VERSION ""

NS_ :

BS_:

BU_: mADC

BO_ 1321 mADC_529: 64 mADC
 SG_ ACC_Target17BSDStatus : 493|2@0+ (1,0) [0|3] "" Vector__XXX
 SG_ ACC_Target16RightLightStatus : 494|1@0+ (1,0) [0|1] "" Vector__XXX
 SG_ ACC_Target16LngRelSpeed : 487|9@0+ (1,-250) [-250|250] "km/h" Vector__XXX
 SG_ ACC_Target16LngRange : 467|12@0+ (0.1,-100) [-100|300] "m" Vector__XXX
 SG_ ACC_Target16LeftLightStatus : 436|1@0+ (1,0) [0|1] "" Vector__XXX
 SG_ ACC_Target16LDC : 437|1@0+ (1,0) [0|1] "" Vector__XXX
 SG_ ACC_Target16LatRelSpeed : 461|10@0+ (0.125,-64) [-64|63.875] "m/s" Vector__XXX
 SG_ ACC_Target16LatRange : 455|10@0+ (0.1,-50) [-50|50] "m" Vector__XXX
 SG_ ACC_Target16ID : 427|6@0+ (1,0) [0|63] "" Vector__XXX
 SG_ ACC_Target16HeadingAngle : 421|10@0+ (0.01,-3.14) [-3.14|3.14] "rad" Vector__XXX
 SG_ ACC_Target16Direction : 408|3@0+ (1,0) [0|7] "" Vector__XXX
 SG_ ACC_Target16Detection : 411|3@0+ (1,0) [0|7] "" Vector__XXX
 SG_ ACC_Target16BSDStatus : 413|2@0+ (1,0) [0|3] "" Vector__XXX
 SG_ ACC_Target16BrakeLightStatus : 414|1@0+ (1,0) [0|1] "" Vector__XXX
 SG_ ACC_Target15ZoneID : 360|5@0+ (1,0) [0|31] "" Vector__XXX
 SG_ ACC_Target15Type : 402|4@0+ (1,0) [0|15] "" Vector__XXX
 SG_ ACC_Target15RightLightStatus : 361|1@0+ (1,0) [0|1] "" Vector__XXX
 SG_ ACC_Target15LngRelSpeed : 395|9@0+ (1,-250) [-250|250] "km/h" Vector__XXX
 SG_ ACC_Target15LngRange : 391|12@0+ (0.1,-100) [-100|300] "m" Vector__XXX
 SG_ ACC_Target15LeftLightStatus : 362|1@0+ (1,0) [0|1] "" Vector__XXX
 SG_ ACC_Target15LDC : 363|1@0+ (1,0) [0|1] "" Vector__XXX
 SG_ ACC_Target15LatRelSpeed : 357|10@0+ (0.125,-64) [-64|63.875] "m/s" Vector__XXX
 SG_ ACC_Target15LatRange : 351|10@0+ (0.1,-50) [-50|50] "m" Vector__XXX
 SG_ ACC_Target15ID : 341|6@0+ (1,0) [0|63] "" Vector__XXX
 SG_ ACC_Target15HeadingAngle : 335|10@0+ (0.01,-3.14) [-3.14|3.14] "rad" Vector__XXX
 SG_ ACC_Target15Direction : 322|3@0+ (1,0) [0|7] "" Vector__XXX
 SG_ ACC_Target15Detection : 325|3@0+ (1,0) [0|7] "" Vector__XXX
 SG_ ACC_Target15BSDStatus : 327|2@0+ (1,0) [0|3] "" Vector__XXX
 SG_ ACC_Target14ZoneID : 40|5@0+ (1,0) [0|31] "" Vector__XXX
 SG_ ACC_Target14Type : 311|4@0+ (1,0) [0|15] "" Vector__XXX
 SG_ ACC_Target14LngRelSpeed : 288|9@0+ (1,-250) [-250|250] "km/h" Vector__XXX
 SG_ ACC_Target14LngRange : 284|12@0+ (0.1,-100) [-100|300] "m" Vector__XXX
 SG_ ACC_Target14LeftLightStatus : 41|1@0+ (1,0) [0|1] "" Vector__XXX
 SG_ ACC_Target14LDC : 285|1@0+ (1,0) [0|1] "" Vector__XXX
 SG_ ACC_Target14LatRelSpeed : 279|10@0+ (0.125,-64) [-64|63.875] "m/s" Vector__XXX
 SG_ ACC_Target14LatRange : 257|10@0+ (0.1,-50) [-50|50] "m" Vector__XXX
 SG_ ACC_Target14ID : 263|6@0+ (1,0) [0|63] "" Vector__XXX
 SG_ ACC_Target14HeadingAngle : 237|10@0+ (0.01,-3.14) [-3.14|3.14] "rad" Vector__XXX
 SG_ ACC_Target14Direction : 224|3@0+ (1,0) [0|7] "" Vector__XXX
 SG_ ACC_Target14Detection : 227|3@0+ (1,0) [0|7] "" Vector__XXX
 SG_ ACC_Target14BSDStatus : 229|2@0+ (1,0) [0|3] "" Vector__XXX
 SG_ ACC_Target14BrakeLightStatus : 230|1@0+ (1,0) [0|1] "" Vector__XXX
 SG_ ACC_Target13ZoneID : 219|5@0+ (1,0) [0|31] "" Vector__XXX
 SG_ ACC_Target13Type : 223|4@0+ (1,0) [0|15] "" Vector__XXX
 SG_ ACC_Target13RightLightStatus : 208|1@0+ (1,0) [0|1] "" Vector__XXX
 SG_ ACC_Target13LngRelSpeed : 201|9@0+ (1,-250) [-250|250] "km/h" Vector__XXX
 SG_ ACC_Target13LngRange : 197|12@0+ (0.1,-100) [-100|300] "m" Vector__XXX
 SG_ ACC_Target13LeftLightStatus : 198|1@0+ (1,0) [0|1] "" Vector__XXX
 SG_ ACC_Target13LDC : 199|1@0+ (1,0) [0|1] "" Vector__XXX
 SG_ ACC_Target13LatRelSpeed : 173|10@0+ (0.125,-64) [-64|63.875] "m/s" Vector__XXX
 SG_ ACC_Target13LatRange : 167|10@0+ (0.1,-50) [-50|50] "m" Vector__XXX
 SG_ ACC_Target13ID : 157|6@0+ (1,0) [0|63] "" Vector__XXX
 SG_ ACC_Target13HeadingAngle : 151|10@0+ (0.01,-3.14) [-3.14|3.14] "rad" Vector__XXX
 SG_ ACC_Target13Direction : 138|3@0+ (1,0) [0|7] "" Vector__XXX
 SG_ ACC_Target13Detection : 141|3@0+ (1,0) [0|7] "" Vector__XXX
 SG_ ACC_Target13BSDStatus : 117|2@0+ (1,0) [0|3] "" Vector__XXX
 SG_ ACC_Target13BrakeLightStatus : 142|1@0+ (1,0) [0|1] "" Vector__XXX
 SG_ ACC_Target12ZoneID : 131|5@0+ (1,0) [0|31] "" Vector__XXX
 SG_ ACC_Target12Type : 135|4@0+ (1,0) [0|15] "" Vector__XXX
 SG_ ACC_Target12RightLightStatus : 118|1@0+ (1,0) [0|1] "" Vector__XXX
 SG_ ACC_Target12LngRelSpeed : 111|9@0+ (1,-250) [-250|250] "km/h" Vector__XXX
 SG_ ACC_Target12LngRange : 91|12@0+ (0.1,-100) [-100|300] "m" Vector__XXX
 SG_ ACC_Target12LeftLightStatus : 92|1@0+ (1,0) [0|1] "" Vector__XXX
 SG_ ACC_Target12LDC : 93|1@0+ (1,0) [0|1] "" Vector__XXX
 SG_ ACC_Target12LatRelSpeed : 87|10@0+ (0.125,-64) [-64|63.875] "m/s" Vector__XXX
 SG_ ACC_Target12LatRange : 65|10@0+ (0.1,-50) [-50|50] "m" Vector__XXX
 SG_ ACC_Target12ID : 71|6@0+ (1,0) [0|63] "" Vector__XXX
 SG_ ACC_Target12HeadingAngle : 35|10@0+ (0.01,-3.14) [-3.14|3.14] "rad" Vector__XXX
 SG_ ACC_Target12Direction : 38|3@0+ (1,0) [0|7] "" Vector__XXX
 SG_ ACC_Target12Detection : 25|3@0+ (1,0) [0|7] "" Vector__XXX
 SG_ ACC_Target12BSDStatus : 27|2@0+ (1,0) [0|3] "" Vector__XXX
 SG_ ACC_Target12BrakeLightStatus : 28|1@0+ (1,0) [0|1] "" Vector__XXX
 SG_ ACC_Target11ZoneID : 17|5@0+ (1,0) [0|31] "" Vector__XXX
 SG_ ACC_Target11RightLightStatus : 18|1@0+ (1,0) [0|1] "" Vector__XXX
 SG_ ACC_Target11LngRelSpeed : 11|9@0+ (1,-250) [-250|250] "km/h" Vector__XXX
 SG_ ACC_Target11LngRange : 7|12@0+ (0.1,-100) [-100|300] "m" Vector__XXX

BO_ 1323 mADC_52B: 64 mADC
 SG_ ACC_Target22BSDStatus : 493|2@0+ (1,0) [0|3] "" Vector__XXX
 SG_ ACC_Target21RightLightStatus : 436|1@0+ (1,0) [0|1] "" Vector__XXX
 SG_ ACC_Target21LngRange : 473|12@0+ (0.1,-100) [-100|300] "m" Vector__XXX
 SG_ ACC_Target21LeftLightStatus : 437|1@0+ (1,0) [0|1] "" Vector__XXX
 SG_ ACC_Target21LDC : 438|1@0+ (1,0) [0|1] "" Vector__XXX
 SG_ ACC_Target21LatRelSpeed : 467|10@0+ (0.125,-64) [-64|63.875] "m/s" Vector__XXX
 SG_ ACC_Target21LatRange : 461|10@0+ (0.1,-50) [-50|50] "m" Vector__XXX
 SG_ ACC_Target21HeadingAngle : 455|10@0+ (0.01,-3.14) [-3.14|3.14] "rad" Vector__XXX
 SG_ ACC_Target21Direction : 425|3@0+ (1,0) [0|7] "" Vector__XXX
 SG_ ACC_Target21Detection : 428|3@0+ (1,0) [0|7] "" Vector__XXX
 SG_ ACC_Target21BSDStatus : 430|2@0+ (1,0) [0|3] "" Vector__XXX
 SG_ ACC_Target21BrakeLightStatus : 431|1@0+ (1,0) [0|1] "" Vector__XXX
 SG_ ACC_Target20ZoneID : 420|5@0+ (1,0) [0|31] "" Vector__XXX
 SG_ ACC_Target20Type : 408|4@0+ (1,0) [0|15] "" Vector__XXX
 SG_ ACC_Target20RightLightStatus : 372|1@0+ (1,0) [0|1] "" Vector__XXX
 SG_ ACC_Target20LngRelSpeed : 401|9@0+ (1,-250) [-250|250] "km/h" Vector__XXX
 SG_ ACC_Target20LngRange : 397|12@0+ (0.1,-100) [-100|300] "m" Vector__XXX
 SG_ ACC_Target20LeftLightStatus : 373|1@0+ (1,0) [0|1] "" Vector__XXX
 SG_ ACC_Target20LDC : 374|1@0+ (1,0) [0|1] "" Vector__XXX
 SG_ ACC_Target20LatRelSpeed : 391|10@0+ (0.125,-64) [-64|63.875] "m/s" Vector__XXX
 SG_ ACC_Target20LatRange : 352|10@0+ (0.1,-50) [-50|50] "m" Vector__XXX
 SG_ ACC_Target20ID : 358|6@0+ (1,0) [0|63] "" Vector__XXX
 SG_ ACC_Target20HeadingAngle : 336|10@0+ (0.01,-3.14) [-3.14|3.14] "rad" Vector__XXX
 SG_ ACC_Target20Direction : 339|3@0+ (1,0) [0|7] "" Vector__XXX
 SG_ ACC_Target20Detection : 342|3@0+ (1,0) [0|7] "" Vector__XXX
 SG_ ACC_Target20BSDStatus : 328|2@0+ (1,0) [0|3] "" Vector__XXX
 SG_ ACC_Target20BrakeLightStatus : 329|1@0+ (1,0) [0|1] "" Vector__XXX
 SG_ ACC_Target1RightLightStatus : 330|1@0+ (1,0) [0|1] "" Vector__XXX
 SG_ ACC_Target1LngRelSpeed : 323|9@0+ (1,-250) [-250|250] "km/h" Vector__XXX
 SG_ ACC_Target1LeftLightStatus : 325|1@0+ (1,0) [0|1] "" Vector__XXX
 SG_ ACC_Target1LDC : 324|1@0+ (1,0) [0|1] "" Vector__XXX
 SG_ ACC_Target1LatRelSpeed : 301|10@0+ (0.125,-64) [-64|63.875] "m/s" Vector__XXX
 SG_ ACC_Target1BSDStatus : 327|2@0+ (1,0) [0|3] "" Vector__XXX
 SG_ ACC_Target1BrakeLightStatus : 302|1@0+ (1,0) [0|1] "" Vector__XXX
 SG_ ACC_Target19ZoneID : 291|5@0+ (1,0) [0|31] "" Vector__XXX
 SG_ ACC_Target19Type : 295|4@0+ (1,0) [0|15] "" Vector__XXX
 SG_ ACC_Target19RightLightStatus : 280|1@0+ (1,0) [0|1] "" Vector__XXX
 SG_ ACC_Target19LngRelSpeed : 273|9@0+ (1,-250) [-250|250] "km/h" Vector__XXX
 SG_ ACC_Target19LngRange : 269|12@0+ (0.1,-100) [-100|300] "m" Vector__XXX
 SG_ ACC_Target19LeftLightStatus : 244|1@0+ (1,0) [0|1] "" Vector__XXX
 SG_ ACC_Target19LDC : 245|1@0+ (1,0) [0|1] "" Vector__XXX
 SG_ ACC_Target19LatRelSpeed : 263|10@0+ (0.125,-64) [-64|63.875] "m/s" Vector__XXX
 SG_ ACC_Target19LatRange : 239|10@0+ (0.1,-50) [-50|50] "m" Vector__XXX
 SG_ ACC_Target19ID : 229|6@0+ (1,0) [0|63] "" Vector__XXX
 SG_ ACC_Target19HeadingAngle : 223|10@0+ (0.01,-3.14) [-3.14|3.14] "rad" Vector__XXX
 SG_ ACC_Target19Direction : 210|3@0+ (1,0) [0|7] "" Vector__XXX
 SG_ ACC_Target19Detection : 213|3@0+ (1,0) [0|7] "" Vector__XXX
 SG_ ACC_Target19BSDStatus : 215|2@0+ (1,0) [0|3] "" Vector__XXX
 SG_ ACC_Target19BrakeLightStatus : 200|1@0+ (1,0) [0|1] "" Vector__XXX
 SG_ ACC_Target18ZoneID : 205|5@0+ (1,0) [0|31] "" Vector__XXX
 SG_ ACC_Target18Type : 183|4@0+ (1,0) [0|15] "" Vector__XXX
 SG_ ACC_Target18RightLightStatus : 206|1@0+ (1,0) [0|1] "" Vector__XXX
 SG_ ACC_Target18LngRelSpeed : 199|9@0+ (1,-250) [-250|250] "km/h" Vector__XXX
 SG_ ACC_Target18LngRange : 163|12@0+ (0.1,-100) [-100|300] "m" Vector__XXX
 SG_ ACC_Target18LeftLightStatus : 108|1@0+ (1,0) [0|1] "" Vector__XXX
 SG_ ACC_Target18LDC : 109|1@0+ (1,0) [0|1] "" Vector__XXX
 SG_ ACC_Target18LatRelSpeed : 157|10@0+ (0.125,-64) [-64|63.875] "m/s" Vector__XXX
 SG_ ACC_Target18LatRange : 151|10@0+ (0.1,-50) [-50|50] "m" Vector__XXX
 SG_ ACC_Target18ID : 141|6@0+ (1,0) [0|63] "" Vector__XXX
 SG_ ACC_Target18HeadingAngle : 135|10@0+ (0.01,-3.14) [-3.14|3.14] "rad" Vector__XXX
 SG_ ACC_Target18Direction : 96|3@0+ (1,0) [0|7] "" Vector__XXX
 SG_ ACC_Target18Detection : 99|3@0+ (1,0) [0|7] "" Vector__XXX
 SG_ ACC_Target18BSDStatus : 101|2@0+ (1,0) [0|3] "" Vector__XXX
 SG_ ACC_Target18BrakeLightStatus : 102|1@0+ (1,0) [0|1] "" Vector__XXX
 SG_ ACC_Target17ZoneID : 91|5@0+ (1,0) [0|31] "" Vector__XXX
 SG_ ACC_Target17Type : 95|4@0+ (1,0) [0|15] "" Vector__XXX
 SG_ ACC_Target17RightLightStatus : 80|1@0+ (1,0) [0|1] "" Vector__XXX
 SG_ ACC_Target17LngRelSpeed : 73|9@0+ (1,-250) [-250|250] "km/h" Vector__XXX
 SG_ ACC_Target17LngRange : 69|12@0+ (0.1,-100) [-100|300] "m" Vector__XXX
 SG_ ACC_Target17LeftLightStatus : 70|1@0+ (1,0) [0|1] "" Vector__XXX
 SG_ ACC_Target17LDC : 71|1@0+ (1,0) [0|1] "" Vector__XXX
 SG_ ACC_Target17LatRelSpeed : 45|10@0+ (0.125,-64) [-64|63.875] "m/s" Vector__XXX
 SG_ ACC_Target17LatRange : 39|10@0+ (0.1,-50) [-50|50] "m" Vector__XXX
 SG_ ACC_Target17ID : 29|6@0+ (1,0) [0|63] "" Vector__XXX
 SG_ ACC_Target17HeadingAngle : 23|10@0+ (0.01,-3.14) [-3.14|3.14] "rad" Vector__XXX
 SG_ ACC_Target17Direction : 10|3@0+ (1,0) [0|7] "" Vector__XXX
 SG_ ACC_Target17Detection : 13|3@0+ (1,0) [0|7] "" Vector__XXX
 SG_ ACC_Target17BrakeLightStatus : 14|1@0+ (1,0) [0|1] "" Vector__XXX
 SG_ ACC_Target16ZoneID : 3|5@0+ (1,0) [0|31] "" Vector__XXX
 SG_ ACC_Target16Type : 7|4@0+ (1,0) [0|15] "" Vector__XXX

BO_ 1329 mADC_531: 64 mADC
 SG_ ACC_Target27BrakeLightStatus : 492|1@0+ (1,0) [0|1] "" Vector__XXX
 SG_ ACC_Target26ZoneID : 481|5@0+ (1,0) [0|31] "" Vector__XXX
 SG_ ACC_Target26RightLightStatus : 436|1@0+ (1,0) [0|1] "" Vector__XXX
 SG_ ACC_Target26LngRange : 477|12@0+ (0.1,-100) [-100|300] "m" Vector__XXX
 SG_ ACC_Target26LeftLightStatus : 437|1@0+ (1,0) [0|1] "" Vector__XXX
 SG_ ACC_Target26LDC : 438|1@0+ (1,0) [0|1] "" Vector__XXX
 SG_ ACC_Target26LatRelSpeed : 471|10@0+ (0.125,-64) [-64|63.875] "m/s" Vector__XXX
 SG_ ACC_Target26LatRange : 449|10@0+ (0.1,-50) [-50|50] "m" Vector__XXX
 SG_ ACC_Target26ID : 455|6@0+ (1,0) [0|63] "" Vector__XXX
 SG_ ACC_Target26HeadingAngle : 416|10@0+ (0.01,-3.14) [-3.14|3.14] "rad" Vector__XXX
 SG_ ACC_Target26Direction : 419|3@0+ (1,0) [0|7] "" Vector__XXX
 SG_ ACC_Target26Detection : 422|3@0+ (1,0) [0|7] "" Vector__XXX
 SG_ ACC_Target26BSDStatus : 408|2@0+ (1,0) [0|3] "" Vector__XXX
 SG_ ACC_Target26BrakeLightStatus : 409|1@0+ (1,0) [0|1] "" Vector__XXX
 SG_ ACC_Target25ZoneID : 414|5@0+ (1,0) [0|31] "" Vector__XXX
 SG_ ACC_Target25Type : 402|4@0+ (1,0) [0|15] "" Vector__XXX
 SG_ ACC_Target25RightLightStatus : 372|1@0+ (1,0) [0|1] "" Vector__XXX
 SG_ ACC_Target25LngRelSpeed : 395|9@0+ (1,-250) [-250|250] "km/h" Vector__XXX
 SG_ ACC_Target25LngRange : 391|12@0+ (0.1,-100) [-100|300] "m" Vector__XXX
 SG_ ACC_Target25LeftLightStatus : 373|1@0+ (1,0) [0|1] "" Vector__XXX
 SG_ ACC_Target25LDC : 374|1@0+ (1,0) [0|1] "" Vector__XXX
 SG_ ACC_Target25LatRelSpeed : 352|10@0+ (0.125,-64) [-64|63.875] "m/s" Vector__XXX
 SG_ ACC_Target25LatRange : 346|10@0+ (0.1,-50) [-50|50] "m" Vector__XXX
 SG_ ACC_Target25ID : 336|6@0+ (1,0) [0|63] "" Vector__XXX
 SG_ ACC_Target25HeadingAngle : 330|10@0+ (0.01,-3.14) [-3.14|3.14] "rad" Vector__XXX
 SG_ ACC_Target25Direction : 333|3@0+ (1,0) [0|7] "" Vector__XXX
 SG_ ACC_Target25Detection : 320|3@0+ (1,0) [0|7] "" Vector__XXX
 SG_ ACC_Target25BSDStatus : 322|2@0+ (1,0) [0|3] "" Vector__XXX
 SG_ ACC_Target25BrakeLightStatus : 308|1@0+ (1,0) [0|1] "" Vector__XXX
 SG_ ACC_Target24ZoneID : 327|5@0+ (1,0) [0|31] "" Vector__XXX
 SG_ ACC_Target24Type : 296|4@0+ (1,0) [0|15] "" Vector__XXX
 SG_ ACC_Target24RightLightStatus : 297|1@0+ (1,0) [0|1] "" Vector__XXX
 SG_ ACC_Target24LngRelSpeed : 290|9@0+ (1,-250) [-250|250] "km/h" Vector__XXX
 SG_ ACC_Target24LngRange : 286|12@0+ (0.1,-100) [-100|300] "m" Vector__XXX
 SG_ ACC_Target24LeftLightStatus : 287|1@0+ (1,0) [0|1] "" Vector__XXX
 SG_ ACC_Target24LDC : 272|1@0+ (1,0) [0|1] "" Vector__XXX
 SG_ ACC_Target24LatRelSpeed : 266|10@0+ (0.125,-64) [-64|63.875] "m/s" Vector__XXX
 SG_ ACC_Target24LatRange : 260|10@0+ (0.1,-50) [-50|50] "m" Vector__XXX
 SG_ ACC_Target24ID : 233|6@0+ (1,0) [0|63] "" Vector__XXX
 SG_ ACC_Target24HeadingAngle : 227|10@0+ (0.01,-3.14) [-3.14|3.14] "rad" Vector__XXX
 SG_ ACC_Target24Direction : 230|3@0+ (1,0) [0|7] "" Vector__XXX
 SG_ ACC_Target24Detection : 263|3@0+ (1,0) [0|7] "" Vector__XXX
 SG_ ACC_Target24BSDStatus : 216|2@0+ (1,0) [0|3] "" Vector__XXX
 SG_ ACC_Target24BrakeLightStatus : 217|1@0+ (1,0) [0|1] "" Vector__XXX
 SG_ ACC_Target23ZoneID : 222|5@0+ (1,0) [0|31] "" Vector__XXX
 SG_ ACC_Target23Type : 210|4@0+ (1,0) [0|15] "" Vector__XXX
 SG_ ACC_Target23RightLightStatus : 172|1@0+ (1,0) [0|1] "" Vector__XXX
 SG_ ACC_Target23LngRelSpeed : 203|9@0+ (1,-250) [-250|250] "km/h" Vector__XXX
 SG_ ACC_Target23LngRange : 199|12@0+ (0.1,-100) [-100|300] "m" Vector__XXX
 SG_ ACC_Target23LeftLightStatus : 173|1@0+ (1,0) [0|1] "" Vector__XXX
 SG_ ACC_Target23LDC : 116|1@0+ (1,0) [0|1] "" Vector__XXX
 SG_ ACC_Target23LatRelSpeed : 167|10@0+ (0.125,-64) [-64|63.875] "m/s" Vector__XXX
 SG_ ACC_Target23LatRange : 145|10@0+ (0.1,-50) [-50|50] "m" Vector__XXX
 SG_ ACC_Target23ID : 151|6@0+ (1,0) [0|63] "" Vector__XXX
 SG_ ACC_Target23HeadingAngle : 129|10@0+ (0.01,-3.14) [-3.14|3.14] "rad" Vector__XXX
 SG_ ACC_Target23Direction : 119|3@0+ (1,0) [0|7] "" Vector__XXX
 SG_ ACC_Target23Detection : 106|3@0+ (1,0) [0|7] "" Vector__XXX
 SG_ ACC_Target23BSDStatus : 108|2@0+ (1,0) [0|3] "" Vector__XXX
 SG_ ACC_Target23BrakeLightStatus : 109|1@0+ (1,0) [0|1] "" Vector__XXX
 SG_ ACC_Target22ZoneID : 98|5@0+ (1,0) [0|31] "" Vector__XXX
 SG_ ACC_Target22Type : 102|4@0+ (1,0) [0|15] "" Vector__XXX
 SG_ ACC_Target22RightLightStatus : 103|1@0+ (1,0) [0|1] "" Vector__XXX
 SG_ ACC_Target22LngRelSpeed : 80|9@0+ (1,-250) [-250|250] "km/h" Vector__XXX
 SG_ ACC_Target22LngRange : 76|12@0+ (0.1,-100) [-100|300] "m" Vector__XXX
 SG_ ACC_Target22LeftLightStatus : 77|1@0+ (1,0) [0|1] "" Vector__XXX
 SG_ ACC_Target22LDC : 52|1@0+ (1,0) [0|1] "" Vector__XXX
 SG_ ACC_Target22LatRelSpeed : 71|10@0+ (0.125,-64) [-64|63.875] "m/s" Vector__XXX
 SG_ ACC_Target22LatRange : 46|10@0+ (0.1,-50) [-50|50] "m" Vector__XXX
 SG_ ACC_Target22ID : 36|6@0+ (1,0) [0|63] "" Vector__XXX
 SG_ ACC_Target22HeadingAngle : 30|10@0+ (0.01,-3.14) [-3.14|3.14] "rad" Vector__XXX
 SG_ ACC_Target22Direction : 17|3@0+ (1,0) [0|7] "" Vector__XXX
 SG_ ACC_Target22Detection : 20|3@0+ (1,0) [0|7] "" Vector__XXX
 SG_ ACC_Target22BrakeLightStatus : 21|1@0+ (1,0) [0|1] "" Vector__XXX
 SG_ ACC_Target21ZoneID : 10|5@0+ (1,0) [0|31] "" Vector__XXX
 SG_ ACC_Target21Type : 14|4@0+ (1,0) [0|15] "" Vector__XXX
 SG_ ACC_Target21LngRelSpeed : 7|9@0+ (1,-250) [-250|250] "km/h" Vector__XXX
 SG_ ACC_Target21ID : 135|6@0+ (1,0) [0|63] "" Vector__XXX

BO_ 1330 mADC_532: 64 mADC
 SG_ ACC_Target31LngRange : 487|12@0+ (0.1,-100) [-100|300] "m" Vector__XXX
 SG_ ACC_Target31LeftLightStatus : 472|1@0+ (1,0) [0|1] "" Vector__XXX
 SG_ ACC_Target31LDC : 473|1@0+ (1,0) [0|1] "" Vector__XXX
 SG_ ACC_Target31LatRelSpeed : 467|10@0+ (0.125,-64) [-64|63.875] "m/s" Vector__XXX
 SG_ ACC_Target31LatRange : 461|10@0+ (0.1,-50) [-50|50] "m" Vector__XXX
 SG_ ACC_Target31ID : 425|6@0+ (1,0) [0|63] "" Vector__XXX
 SG_ ACC_Target31HeadingAngle : 455|10@0+ (0.01,-3.14) [-3.14|3.14] "rad" Vector__XXX
 SG_ ACC_Target31Direction : 428|3@0+ (1,0) [0|7] "" Vector__XXX
 SG_ ACC_Target31Detection : 431|3@0+ (1,0) [0|7] "" Vector__XXX
 SG_ ACC_Target31BSDStatus : 417|2@0+ (1,0) [0|3] "" Vector__XXX
 SG_ ACC_Target31BrakeLightStatus : 418|1@0+ (1,0) [0|1] "" Vector__XXX
 SG_ ACC_Target30ZoneID : 423|5@0+ (1,0) [0|31] "" Vector__XXX
 SG_ ACC_Target30Type : 411|4@0+ (1,0) [0|15] "" Vector__XXX
 SG_ ACC_Target30RightLightStatus : 412|1@0+ (1,0) [0|1] "" Vector__XXX
 SG_ ACC_Target30LngRelSpeed : 405|9@0+ (1,-250) [-250|250] "km/h" Vector__XXX
 SG_ ACC_Target30LngRange : 385|12@0+ (0.1,-100) [-100|300] "m" Vector__XXX
 SG_ ACC_Target30LeftLightStatus : 372|1@0+ (1,0) [0|1] "" Vector__XXX
 SG_ ACC_Target30LDC : 373|1@0+ (1,0) [0|1] "" Vector__XXX
 SG_ ACC_Target30LatRelSpeed : 367|10@0+ (0.125,-64) [-64|63.875] "m/s" Vector__XXX
 SG_ ACC_Target30LatRange : 345|10@0+ (0.1,-50) [-50|50] "m" Vector__XXX
 SG_ ACC_Target30ID : 391|6@0+ (1,0) [0|63] "" Vector__XXX
 SG_ ACC_Target30HeadingAngle : 339|10@0+ (0.01,-3.14) [-3.14|3.14] "rad" Vector__XXX
 SG_ ACC_Target30Direction : 342|3@0+ (1,0) [0|7] "" Vector__XXX
 SG_ ACC_Target30Detection : 329|3@0+ (1,0) [0|7] "" Vector__XXX
 SG_ ACC_Target30BSDStatus : 331|2@0+ (1,0) [0|3] "" Vector__XXX
 SG_ ACC_Target30BrakeLightStatus : 332|1@0+ (1,0) [0|1] "" Vector__XXX
 SG_ ACC_Target2RightLightStatus : 333|1@0+ (1,0) [0|1] "" Vector__XXX
 SG_ ACC_Target2LngRelSpeed : 326|9@0+ (1,-250) [-250|250] "km/h" Vector__XXX
 SG_ ACC_Target2LeftLightStatus : 327|1@0+ (1,0) [0|1] "" Vector__XXX
 SG_ ACC_Target2LDC : 308|1@0+ (1,0) [0|1] "" Vector__XXX
 SG_ ACC_Target2LatRelSpeed : 302|10@0+ (0.125,-64) [-64|63.875] "m/s" Vector__XXX
 SG_ ACC_Target2BSDStatus : 288|2@0+ (1,0) [0|3] "" Vector__XXX
 SG_ ACC_Target2BrakeLightStatus : 289|1@0+ (1,0) [0|1] "" Vector__XXX
 SG_ ACC_Target29ZoneID : 294|5@0+ (1,0) [0|31] "" Vector__XXX
 SG_ ACC_Target29Type : 282|4@0+ (1,0) [0|15] "" Vector__XXX
 SG_ ACC_Target29RightLightStatus : 283|1@0+ (1,0) [0|1] "" Vector__XXX
 SG_ ACC_Target29LngRelSpeed : 276|9@0+ (1,-250) [-250|250] "km/h" Vector__XXX
 SG_ ACC_Target29LngRange : 256|12@0+ (0.1,-100) [-100|300] "m" Vector__XXX
 SG_ ACC_Target29LeftLightStatus : 257|1@0+ (1,0) [0|1] "" Vector__XXX
 SG_ ACC_Target29LDC : 244|1@0+ (1,0) [0|1] "" Vector__XXX
 SG_ ACC_Target29LatRelSpeed : 238|10@0+ (0.125,-64) [-64|63.875] "m/s" Vector__XXX
 SG_ ACC_Target29LatRange : 216|10@0+ (0.1,-50) [-50|50] "m" Vector__XXX
 SG_ ACC_Target29ID : 263|6@0+ (1,0) [0|63] "" Vector__XXX
 SG_ ACC_Target29HeadingAngle : 210|10@0+ (0.01,-3.14) [-3.14|3.14] "rad" Vector__XXX
 SG_ ACC_Target29Direction : 213|3@0+ (1,0) [0|7] "" Vector__XXX
 SG_ ACC_Target29Detection : 200|3@0+ (1,0) [0|7] "" Vector__XXX
 SG_ ACC_Target29BSDStatus : 202|2@0+ (1,0) [0|3] "" Vector__XXX
 SG_ ACC_Target29BrakeLightStatus : 203|1@0+ (1,0) [0|1] "" Vector__XXX
 SG_ ACC_Target28ZoneID : 192|5@0+ (1,0) [0|31] "" Vector__XXX
 SG_ ACC_Target28Type : 196|4@0+ (1,0) [0|15] "" Vector__XXX
 SG_ ACC_Target28RightLightStatus : 197|1@0+ (1,0) [0|1] "" Vector__XXX
 SG_ ACC_Target28LngRelSpeed : 172|9@0+ (1,-250) [-250|250] "km/h" Vector__XXX
 SG_ ACC_Target28LngRange : 152|12@0+ (0.1,-100) [-100|300] "m" Vector__XXX
 SG_ ACC_Target28LeftLightStatus : 198|1@0+ (1,0) [0|1] "" Vector__XXX
 SG_ ACC_Target28LDC : 199|1@0+ (1,0) [0|1] "" Vector__XXX
 SG_ ACC_Target28LatRelSpeed : 146|10@0+ (0.125,-64) [-64|63.875] "m/s" Vector__XXX
 SG_ ACC_Target28LatRange : 140|10@0+ (0.1,-50) [-50|50] "m" Vector__XXX
 SG_ ACC_Target28ID : 130|6@0+ (1,0) [0|63] "" Vector__XXX
 SG_ ACC_Target28HeadingAngle : 109|10@0+ (0.01,-3.14) [-3.14|3.14] "rad" Vector__XXX
 SG_ ACC_Target28Direction : 133|3@0+ (1,0) [0|7] "" Vector__XXX
 SG_ ACC_Target28Detection : 96|3@0+ (1,0) [0|7] "" Vector__XXX
 SG_ ACC_Target28BSDStatus : 135|2@0+ (1,0) [0|3] "" Vector__XXX
 SG_ ACC_Target28BrakeLightStatus : 97|1@0+ (1,0) [0|1] "" Vector__XXX
 SG_ ACC_Target27ZoneID : 102|5@0+ (1,0) [0|31] "" Vector__XXX
 SG_ ACC_Target27Type : 90|4@0+ (1,0) [0|15] "" Vector__XXX
 SG_ ACC_Target27RightLightStatus : 91|1@0+ (1,0) [0|1] "" Vector__XXX
 SG_ ACC_Target27LngRelSpeed : 84|9@0+ (1,-250) [-250|250] "km/h" Vector__XXX
 SG_ ACC_Target27LngRange : 64|12@0+ (0.1,-100) [-100|300] "m" Vector__XXX
 SG_ ACC_Target27LeftLightStatus : 65|1@0+ (1,0) [0|1] "" Vector__XXX
 SG_ ACC_Target27LDC : 66|1@0+ (1,0) [0|1] "" Vector__XXX
 SG_ ACC_Target27LatRelSpeed : 45|10@0+ (0.125,-64) [-64|63.875] "m/s" Vector__XXX
 SG_ ACC_Target27LatRange : 39|10@0+ (0.1,-50) [-50|50] "m" Vector__XXX
 SG_ ACC_Target27ID : 29|6@0+ (1,0) [0|63] "" Vector__XXX
 SG_ ACC_Target27HeadingAngle : 23|10@0+ (0.01,-3.14) [-3.14|3.14] "rad" Vector__XXX
 SG_ ACC_Target27Direction : 69|3@0+ (1,0) [0|7] "" Vector__XXX
 SG_ ACC_Target27Detection : 10|3@0+ (1,0) [0|7] "" Vector__XXX
 SG_ ACC_Target27BSDStatus : 71|2@0+ (1,0) [0|3] "" Vector__XXX
 SG_ ACC_Target26Type : 14|4@0+ (1,0) [0|15] "" Vector__XXX
 SG_ ACC_Target26LngRelSpeed : 7|9@0+ (1,-250) [-250|250] "km/h" Vector__XXX

BO_ 1331 mADC_533: 64 mADC
 SG_ APA_DynamicButton : 172|4@0+ (1,0) [0|15] "" Vector__XXX
 SG_ APA_DLPReq : 495|4@0+ (1,0) [0|15] "" Vector__XXX
 SG_ APA_DetailedVoice_Switch : 480|1@0+ (1,0) [0|1] "" Vector__XXX
 SG_ APA_BackstageSearchSts : 481|1@0+ (1,0) [0|1] "" Vector__XXX
 SG_ ADS_IACCSysdeactiveReason : 485|4@0+ (1,0) [0|15] "" Vector__XXX
 SG_ ADS_IACC_LatTakeOverReason : 473|4@0+ (1,0) [0|15] "" Vector__XXX
 SG_ ACC_RLaneQuality : 479|6@0+ (0.015625,0) [0|0.984375] "" Vector__XXX
 SG_ ACC_RedLightRemindEnable : 464|1@0+ (1,0) [0|1] "" Vector__XXX
 SG_ ACC_DOSECountDown : 469|5@0+ (1,0) [0|31] "" Vector__XXX
 SG_ ACC_Target9ZoneID : 458|5@0+ (1,0) [0|31] "" Vector__XXX
 SG_ ACC_Target9Type : 462|4@0+ (1,0) [0|15] "" Vector__XXX
 SG_ ACC_Target9RightLightStatus : 436|1@0+ (1,0) [0|1] "" Vector__XXX
 SG_ ACC_Target9LngRelSpeed : 455|9@0+ (1,-250) [-250|250] "km/h" Vector__XXX
 SG_ ACC_Target9LngRange : 416|12@0+ (0.1,-100) [-100|300] "m" Vector__XXX
 SG_ ACC_Target9LeftLightStatus : 372|1@0+ (1,0) [0|1] "" Vector__XXX
 SG_ ACC_Target9LDC : 373|1@0+ (1,0) [0|1] "" Vector__XXX
 SG_ ACC_Target9LatRelSpeed : 410|10@0+ (0.125,-64) [-64|63.875] "m/s" Vector__XXX
 SG_ ACC_Target9LatRange : 404|10@0+ (0.1,-50) [-50|50] "m" Vector__XXX
 SG_ ACC_Target9ID : 394|6@0+ (1,0) [0|63] "" Vector__XXX
 SG_ ACC_Target9HeadingAngle : 388|10@0+ (0.01,-3.14) [-3.14|3.14] "rad" Vector__XXX
 SG_ ACC_Target9Direction : 391|3@0+ (1,0) [0|7] "" Vector__XXX
 SG_ ACC_Target9Detection : 360|3@0+ (1,0) [0|7] "" Vector__XXX
 SG_ ACC_Target9BSDStatus : 362|2@0+ (1,0) [0|3] "" Vector__XXX
 SG_ ACC_Target9BrakeLightStatus : 363|1@0+ (1,0) [0|1] "" Vector__XXX
 SG_ ACC_Target8ZoneID : 352|5@0+ (1,0) [0|31] "" Vector__XXX
 SG_ ACC_Target8Type : 356|4@0+ (1,0) [0|15] "" Vector__XXX
 SG_ ACC_Target8RightLightStatus : 357|1@0+ (1,0) [0|1] "" Vector__XXX
 SG_ ACC_Target8LngRelSpeed : 350|9@0+ (1,-250) [-250|250] "km/h" Vector__XXX
 SG_ ACC_Target8LngRange : 330|12@0+ (0.1,-100) [-100|300] "m" Vector__XXX
 SG_ ACC_Target8LeftLightStatus : 308|1@0+ (1,0) [0|1] "" Vector__XXX
 SG_ ACC_Target8LDC : 309|1@0+ (1,0) [0|1] "" Vector__XXX
 SG_ ACC_Target8LatRelSpeed : 324|10@0+ (0.125,-64) [-64|63.875] "m/s" Vector__XXX
 SG_ ACC_Target8LatRange : 303|10@0+ (0.1,-50) [-50|50] "m" Vector__XXX
 SG_ ACC_Target8ID : 293|6@0+ (1,0) [0|63] "" Vector__XXX
 SG_ ACC_Target8HeadingAngle : 287|10@0+ (0.01,-3.14) [-3.14|3.14] "rad" Vector__XXX
 SG_ ACC_Target8Direction : 327|3@0+ (1,0) [0|7] "" Vector__XXX
 SG_ ACC_Target8Detection : 274|3@0+ (1,0) [0|7] "" Vector__XXX
 SG_ ACC_Target8BSDStatus : 276|2@0+ (1,0) [0|3] "" Vector__XXX
 SG_ ACC_Target8BrakeLightStatus : 244|1@0+ (1,0) [0|1] "" Vector__XXX
 SG_ ACC_Target7RightLightStatus : 245|1@0+ (1,0) [0|1] "" Vector__XXX
 SG_ ACC_Target7LngRelSpeed : 269|9@0+ (1,-250) [-250|250] "km/h" Vector__XXX
 SG_ ACC_Target7LeftLightStatus : 246|1@0+ (1,0) [0|1] "" Vector__XXX
 SG_ ACC_Target7LDC : 247|1@0+ (1,0) [0|1] "" Vector__XXX
 SG_ ACC_Target7LatRelSpeed : 263|10@0+ (0.125,-64) [-64|63.875] "m/s" Vector__XXX
 SG_ ACC_Target7BSDStatus : 233|2@0+ (1,0) [0|3] "" Vector__XXX
 SG_ ACC_Target7BrakeLightStatus : 234|1@0+ (1,0) [0|1] "" Vector__XXX
 SG_ ACC_Target6RightLightStatus : 235|1@0+ (1,0) [0|1] "" Vector__XXX
 SG_ ACC_Target6LngRelSpeed : 228|9@0+ (1,-250) [-250|250] "km/h" Vector__XXX
 SG_ ACC_Target6LeftLightStatus : 229|1@0+ (1,0) [0|1] "" Vector__XXX
 SG_ ACC_Target6LDC : 230|1@0+ (1,0) [0|1] "" Vector__XXX
 SG_ ACC_Target6LatRelSpeed : 208|10@0+ (0.125,-64) [-64|63.875] "m/s" Vector__XXX
 SG_ ACC_Target6BSDStatus : 210|2@0+ (1,0) [0|3] "" Vector__XXX
 SG_ ACC_Target6BrakeLightStatus : 211|1@0+ (1,0) [0|1] "" Vector__XXX
 SG_ ACC_Target5RightLightStatus : 212|1@0+ (1,0) [0|1] "" Vector__XXX
 SG_ ACC_Target5LngRelSpeed : 205|9@0+ (1,-250) [-250|250] "km/h" Vector__XXX
 SG_ ACC_Target5LeftLightStatus : 180|1@0+ (1,0) [0|1] "" Vector__XXX
 SG_ ACC_Target5LDC : 181|1@0+ (1,0) [0|1] "" Vector__XXX
 SG_ ACC_Target5LatRelSpeed : 199|10@0+ (0.125,-64) [-64|63.875] "m/s" Vector__XXX
 SG_ ACC_Target5BSDStatus : 183|2@0+ (1,0) [0|3] "" Vector__XXX
 SG_ ACC_Target5BrakeLightStatus : 168|1@0+ (1,0) [0|1] "" Vector__XXX
 SG_ ACC_Target4RightLightStatus : 173|1@0+ (1,0) [0|1] "" Vector__XXX
 SG_ ACC_Target4LngRelSpeed : 166|9@0+ (1,-250) [-250|250] "km/h" Vector__XXX
 SG_ ACC_Target4LeftLightStatus : 167|1@0+ (1,0) [0|1] "" Vector__XXX
 SG_ ACC_Target4LDC : 152|1@0+ (1,0) [0|1] "" Vector__XXX
 SG_ ACC_Target4LatRelSpeed : 146|10@0+ (0.125,-64) [-64|63.875] "m/s" Vector__XXX
 SG_ ACC_Target4BSDStatus : 148|2@0+ (1,0) [0|3] "" Vector__XXX
 SG_ ACC_Target4BrakeLightStatus : 149|1@0+ (1,0) [0|1] "" Vector__XXX
 SG_ ACC_Target3RightLightStatus : 150|1@0+ (1,0) [0|1] "" Vector__XXX
 SG_ ACC_Target3LngRelSpeed : 143|9@0+ (1,-250) [-250|250] "km/h" Vector__XXX
 SG_ ACC_Target3LeftLightStatus : 128|1@0+ (1,0) [0|1] "" Vector__XXX
 SG_ ACC_Target3LDC : 129|1@0+ (1,0) [0|1] "" Vector__XXX
 SG_ ACC_Target3LatRelSpeed : 109|10@0+ (0.125,-64) [-64|63.875] "m/s" Vector__XXX
 SG_ ACC_Target3BSDStatus : 111|2@0+ (1,0) [0|3] "" Vector__XXX
 SG_ ACC_Target3BrakeLightStatus : 130|1@0+ (1,0) [0|1] "" Vector__XXX
 SG_ ACC_Target32ZoneID : 135|5@0+ (1,0) [0|31] "" Vector__XXX
 SG_ ACC_Target32Type : 99|4@0+ (1,0) [0|15] "" Vector__XXX
 SG_ ACC_Target32RightLightStatus : 100|1@0+ (1,0) [0|1] "" Vector__XXX
 SG_ ACC_Target32LngRelSpeed : 93|9@0+ (1,-250) [-250|250] "km/h" Vector__XXX
 SG_ ACC_Target32LngRange : 73|12@0+ (0.1,-100) [-100|300] "m" Vector__XXX
 SG_ ACC_Target32LeftLightStatus : 74|1@0+ (1,0) [0|1] "" Vector__XXX
 SG_ ACC_Target32LDC : 75|1@0+ (1,0) [0|1] "" Vector__XXX
 SG_ ACC_Target32LatRelSpeed : 69|10@0+ (0.125,-64) [-64|63.875] "m/s" Vector__XXX
 SG_ ACC_Target32LatRange : 45|10@0+ (0.1,-50) [-50|50] "m" Vector__XXX
 SG_ ACC_Target32ID : 35|6@0+ (1,0) [0|63] "" Vector__XXX
 SG_ ACC_Target32HeadingAngle : 29|10@0+ (0.01,-3.14) [-3.14|3.14] "rad" Vector__XXX
 SG_ ACC_Target32Direction : 16|3@0+ (1,0) [0|7] "" Vector__XXX
 SG_ ACC_Target32Detection : 19|3@0+ (1,0) [0|7] "" Vector__XXX
 SG_ ACC_Target32BSDStatus : 71|2@0+ (1,0) [0|3] "" Vector__XXX
 SG_ ACC_Target32BrakeLightStatus : 20|1@0+ (1,0) [0|1] "" Vector__XXX
 SG_ ACC_Target31ZoneID : 9|5@0+ (1,0) [0|31] "" Vector__XXX
 SG_ ACC_Target31Type : 13|4@0+ (1,0) [0|15] "" Vector__XXX
 SG_ ACC_Target31RightLightStatus : 14|1@0+ (1,0) [0|1] "" Vector__XXX
 SG_ ACC_Target31LngRelSpeed : 7|9@0+ (1,-250) [-250|250] "km/h" Vector__XXX

BO_ 959 GW_3BF: 8 Vector__XXX
 SG_ PCU_DteDisp : 5|11@0+ (1,0) [0|2046] "KM"  mADC

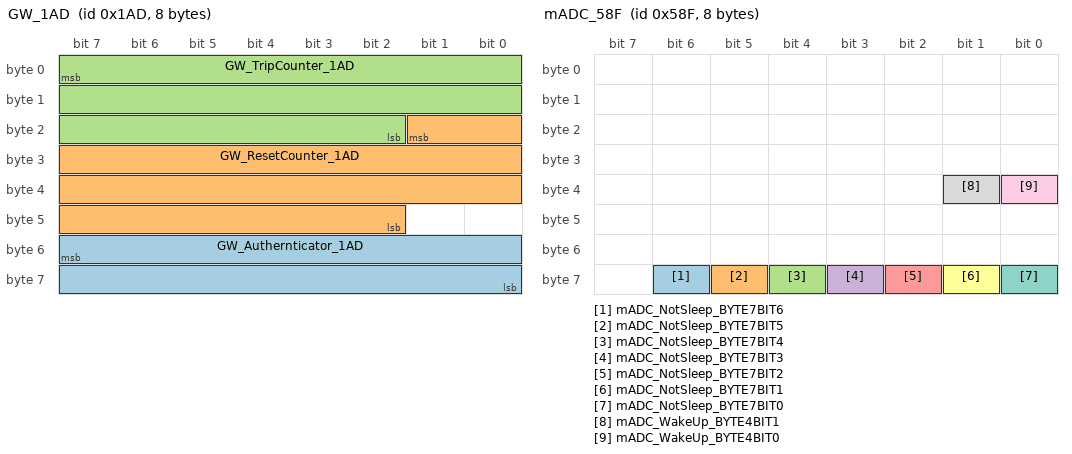
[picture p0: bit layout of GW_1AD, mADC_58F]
BO_ 429 GW_1AD: 8 Vector__XXX
 SG_ GW_Authernticator_1AD : 55|16@0+ (1,0) [0|65535] ""  mADC
 SG_ GW_ResetCounter_1AD : 17|24@0+ (1,0) [0|16777215] ""  mADC
 SG_ GW_TripCounter_1AD : 7|22@0+ (1,0) [0|4194303] ""  mADC

BO_ 1517 mADC_5ED: 8 mADC
 SG_ KeyLearn_Authernticator_5ED : 39|32@0+ (1,0) [1|4294967296] "" Vector__XXX
 SG_ KeyLearn_Random_5ED : 7|32@0+ (1,0) [1|4294967296] "" Vector__XXX

BO_ 1423 mADC_58F: 8 mADC
 SG_ mADC_NotSleep_BYTE7BIT6 : 62|1@0+ (1,0) [0|1] "" Vector__XXX
 SG_ mADC_NotSleep_BYTE7BIT5 : 61|1@0+ (1,0) [0|1] "" Vector__XXX
 SG_ mADC_NotSleep_BYTE7BIT4 : 60|1@0+ (1,0) [0|1] "" Vector__XXX
 SG_ mADC_NotSleep_BYTE7BIT3 : 59|1@0+ (1,0) [0|1] "" Vector__XXX
 SG_ mADC_NotSleep_BYTE7BIT2 : 58|1@0+ (1,0) [0|1] "" Vector__XXX
 SG_ mADC_NotSleep_BYTE7BIT1 : 57|1@0+ (1,0) [0|1] "" Vector__XXX
 SG_ mADC_NotSleep_BYTE7BIT0 : 56|1@0+ (1,0) [0|1] "" Vector__XXX
 SG_ mADC_WakeUp_BYTE4BIT1 : 33|1@0+ (1,0) [0|1] "" Vector__XXX
 SG_ mADC_WakeUp_BYTE4BIT0 : 32|1@0+ (1,0) [0|1] "" Vector__XXX

BO_ 958 GW_3BE: 8 Vector__XXX
 SG_ ATS_CurrentDrivingMode : 35|4@0+ (1,0) [0|15] ""  mADC

BO_ 1718 mADC_6B6: 64 mADC
 SG_ IQSoftwareversion_P : 151|48@0+ (1,0) [0|1] "" Vector__XXX
 SG_ IQSoftwareversion_D : 103|48@0+ (1,0) [0|1] "" Vector__XXX
 SG_ IQSoftwareversion_R : 55|48@0+ (1,0) [0|1] "" Vector__XXX
 SG_ IQSoftwareversion_F : 7|48@0+ (1,0) [0|1] "" Vector__XXX

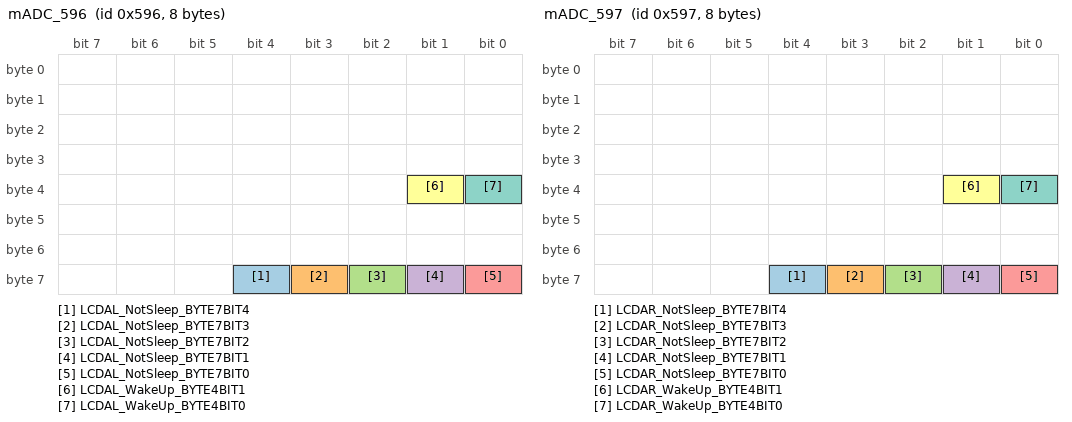
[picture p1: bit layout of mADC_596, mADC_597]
BO_ 1430 mADC_596: 8 mADC
 SG_ LCDAL_NotSleep_BYTE7BIT4 : 60|1@0+ (1,0) [0|1] "" Vector__XXX
 SG_ LCDAL_NotSleep_BYTE7BIT3 : 59|1@0+ (1,0) [0|1] "" Vector__XXX
 SG_ LCDAL_NotSleep_BYTE7BIT2 : 58|1@0+ (1,0) [0|1] "" Vector__XXX
 SG_ LCDAL_NotSleep_BYTE7BIT1 : 57|1@0+ (1,0) [0|1] "" Vector__XXX
 SG_ LCDAL_NotSleep_BYTE7BIT0 : 56|1@0+ (1,0) [0|1] "" Vector__XXX
 SG_ LCDAL_WakeUp_BYTE4BIT1 : 33|1@0+ (1,0) [0|1] "" Vector__XXX
 SG_ LCDAL_WakeUp_BYTE4BIT0 : 32|1@0+ (1,0) [0|1] "" Vector__XXX

BO_ 1431 mADC_597: 8 mADC
 SG_ LCDAR_NotSleep_BYTE7BIT4 : 60|1@0+ (1,0) [0|1] "" Vector__XXX
 SG_ LCDAR_NotSleep_BYTE7BIT3 : 59|1@0+ (1,0) [0|1] "" Vector__XXX
 SG_ LCDAR_NotSleep_BYTE7BIT2 : 58|1@0+ (1,0) [0|1] "" Vector__XXX
 SG_ LCDAR_NotSleep_BYTE7BIT1 : 57|1@0+ (1,0) [0|1] "" Vector__XXX
 SG_ LCDAR_NotSleep_BYTE7BIT0 : 56|1@0+ (1,0) [0|1] "" Vector__XXX
 SG_ LCDAR_WakeUp_BYTE4BIT1 : 33|1@0+ (1,0) [0|1] "" Vector__XXX
 SG_ LCDAR_WakeUp_BYTE4BIT0 : 32|1@0+ (1,0) [0|1] "" Vector__XXX

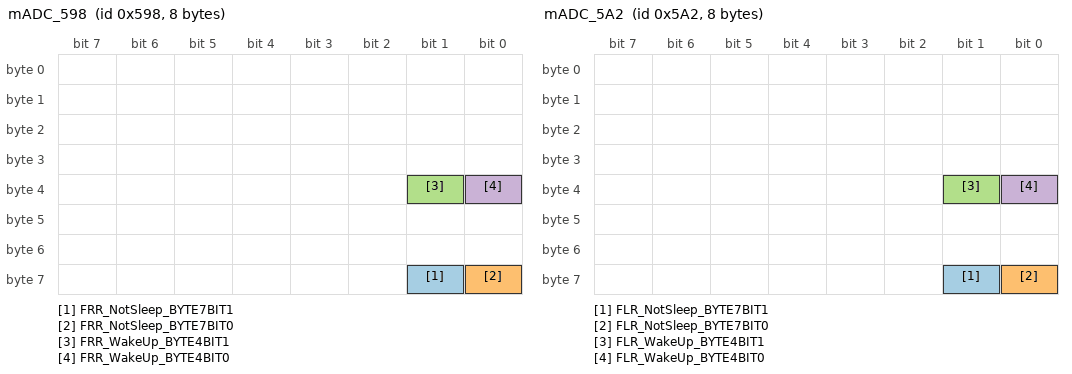
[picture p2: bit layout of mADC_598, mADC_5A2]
BO_ 1432 mADC_598: 8 mADC
 SG_ FRR_NotSleep_BYTE7BIT1 : 57|1@0+ (1,0) [0|1] "" Vector__XXX
 SG_ FRR_NotSleep_BYTE7BIT0 : 56|1@0+ (1,0) [0|1] "" Vector__XXX
 SG_ FRR_WakeUp_BYTE4BIT1 : 33|1@0+ (1,0) [0|1] "" Vector__XXX
 SG_ FRR_WakeUp_BYTE4BIT0 : 32|1@0+ (1,0) [0|1] "" Vector__XXX

BO_ 1442 mADC_5A2: 8 mADC
 SG_ FLR_NotSleep_BYTE7BIT1 : 57|1@0+ (1,0) [0|1] "" Vector__XXX
 SG_ FLR_NotSleep_BYTE7BIT0 : 56|1@0+ (1,0) [0|1] "" Vector__XXX
 SG_ FLR_WakeUp_BYTE4BIT1 : 33|1@0+ (1,0) [0|1] "" Vector__XXX
 SG_ FLR_WakeUp_BYTE4BIT0 : 32|1@0+ (1,0) [0|1] "" Vector__XXX

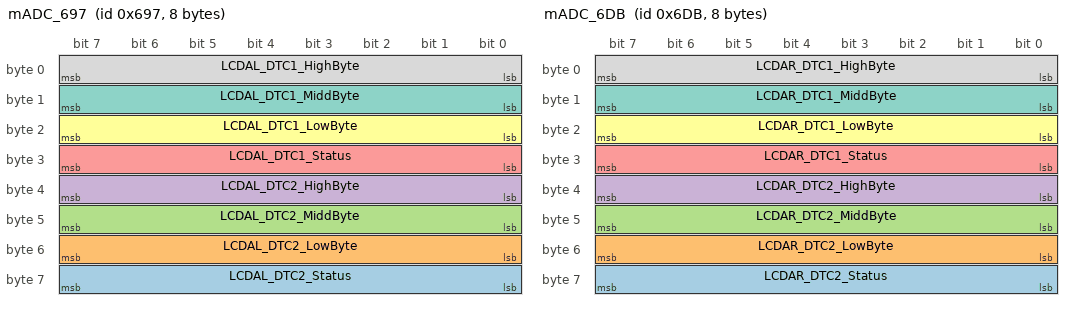
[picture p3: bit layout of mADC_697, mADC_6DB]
BO_ 1687 mADC_697: 8 mADC
 SG_ LCDAL_DTC2_Status : 63|8@0+ (1,0) [0|255] "" Vector__XXX
 SG_ LCDAL_DTC2_LowByte : 55|8@0+ (1,0) [0|255] "" Vector__XXX
 SG_ LCDAL_DTC2_MiddByte : 47|8@0+ (1,0) [0|255] "" Vector__XXX
 SG_ LCDAL_DTC2_HighByte : 39|8@0+ (1,0) [0|255] "" Vector__XXX
 SG_ LCDAL_DTC1_Status : 31|8@0+ (1,0) [0|255] "" Vector__XXX
 SG_ LCDAL_DTC1_LowByte : 23|8@0+ (1,0) [0|255] "" Vector__XXX
 SG_ LCDAL_DTC1_MiddByte : 15|8@0+ (1,0) [0|255] "" Vector__XXX
 SG_ LCDAL_DTC1_HighByte : 7|8@0+ (1,0) [0|255] "" Vector__XXX

BO_ 1755 mADC_6DB: 8 mADC
 SG_ LCDAR_DTC2_Status : 63|8@0+ (1,0) [0|255] "" Vector__XXX
 SG_ LCDAR_DTC2_LowByte : 55|8@0+ (1,0) [0|255] "" Vector__XXX
 SG_ LCDAR_DTC2_MiddByte : 47|8@0+ (1,0) [0|255] "" Vector__XXX
 SG_ LCDAR_DTC2_HighByte : 39|8@0+ (1,0) [0|255] "" Vector__XXX
 SG_ LCDAR_DTC1_Status : 31|8@0+ (1,0) [0|255] "" Vector__XXX
 SG_ LCDAR_DTC1_LowByte : 23|8@0+ (1,0) [0|255] "" Vector__XXX
 SG_ LCDAR_DTC1_MiddByte : 15|8@0+ (1,0) [0|255] "" Vector__XXX
 SG_ LCDAR_DTC1_HighByte : 7|8@0+ (1,0) [0|255] "" Vector__XXX

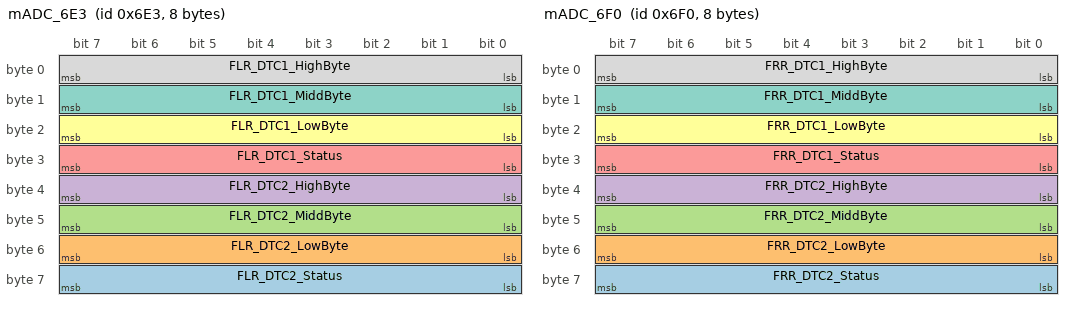
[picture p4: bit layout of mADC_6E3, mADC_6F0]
BO_ 1763 mADC_6E3: 8 mADC
 SG_ FLR_DTC2_Status : 63|8@0+ (1,0) [0|255] "" Vector__XXX
 SG_ FLR_DTC2_LowByte : 55|8@0+ (1,0) [0|255] "" Vector__XXX
 SG_ FLR_DTC2_MiddByte : 47|8@0+ (1,0) [0|255] "" Vector__XXX
 SG_ FLR_DTC2_HighByte : 39|8@0+ (1,0) [0|255] "" Vector__XXX
 SG_ FLR_DTC1_Status : 31|8@0+ (1,0) [0|255] "" Vector__XXX
 SG_ FLR_DTC1_LowByte : 23|8@0+ (1,0) [0|255] "" Vector__XXX
 SG_ FLR_DTC1_MiddByte : 15|8@0+ (1,0) [0|255] "" Vector__XXX
 SG_ FLR_DTC1_HighByte : 7|8@0+ (1,0) [0|255] "" Vector__XXX

BO_ 1776 mADC_6F0: 8 mADC
 SG_ FRR_DTC2_Status : 63|8@0+ (1,0) [0|255] "" Vector__XXX
 SG_ FRR_DTC2_LowByte : 55|8@0+ (1,0) [0|255] "" Vector__XXX
 SG_ FRR_DTC2_MiddByte : 47|8@0+ (1,0) [0|255] "" Vector__XXX
 SG_ FRR_DTC2_HighByte : 39|8@0+ (1,0) [0|255] "" Vector__XXX
 SG_ FRR_DTC1_Status : 31|8@0+ (1,0) [0|255] "" Vector__XXX
 SG_ FRR_DTC1_LowByte : 23|8@0+ (1,0) [0|255] "" Vector__XXX
 SG_ FRR_DTC1_MiddByte : 15|8@0+ (1,0) [0|255] "" Vector__XXX
 SG_ FRR_DTC1_HighByte : 7|8@0+ (1,0) [0|255] "" Vector__XXX

BO_ 2015 GW_7DF: 8 Vector__XXX
 SG_ Diagnose_message7DF : 0|1@0+ (1,0) [1|1] ""  mADC

BO_ 1937 GW_791: 64 Vector__XXX
 SG_ Diagnose_message791 : 0|1@0+ (1,0) [1|1] ""  mADC

BO_ 1945 mADC_799: 8 mADC
 SG_ Diagnose_message799 : 0|1@0+ (1,0) [1|1] "" Vector__XXX

BO_ 1895 GW_767: 64 Vector__XXX
 SG_ Diagnose_message767 : 0|1@0+ (1,0) [1|1] ""  mADC

BO_ 1903 mADC_76F: 8 mADC
 SG_ Diagnose_message76F : 0|1@0+ (1,0) [1|1] "" Vector__XXX

BO_ 1894 GW_766: 64 Vector__XXX
 SG_ Diagnose_message766 : 0|1@0+ (1,0) [1|1] ""  mADC

BO_ 1902 mADC_76E: 8 mADC
 SG_ Diagnose_message76E : 0|1@0+ (1,0) [1|1] "" Vector__XXX

BO_ 1875 GW_753: 64 Vector__XXX
 SG_ Diagnose_message753 : 0|1@0+ (1,0) [1|1] ""  mADC

BO_ 1883 mADC_75B: 8 mADC
 SG_ Diagnose_message75B : 0|1@0+ (1,0) [1|1] "" Vector__XXX

BO_ 1876 GW_754: 64 Vector__XXX
 SG_ Diagnose_message754 : 0|1@0+ (1,0) [1|1] ""  mADC

BO_ 1884 mADC_75C: 8 mADC
 SG_ Diagnose_message75C : 0|1@0+ (1,0) [1|1] "" Vector__XXX

BO_ 1890 GW_762: 64 Vector__XXX
 SG_ Diagnose_message762 : 0|1@0+ (1,0) [1|1] ""  mADC

BO_ 1898 mADC_76A: 8 mADC
 SG_ Diagnose_message76A : 0|1@0+ (1,0) [1|1] "" Vector__XXX

BO_ 953 GW_3B9: 8 Vector__XXX
 SG_ BDC_TurnLightSw : 61|3@0+ (1,1) [0|7] "1"  mADC

BO_ 691 GW_2B3: 8 Vector__XXX
 SG_ THU_ShippingMod : 22|2@0+ (1,0) [0|2] ""  mADC

BO_ 989 GW_3DD: 64 Vector__XXX
 SG_ HU_frontline8_icon : 127|8@0+ (1,0) [0|255] ""  mADC
 SG_ HU_frontline7_icon : 119|8@0+ (1,0) [0|255] ""  mADC
 SG_ HU_frontline6_icon : 111|8@0+ (1,0) [0|255] ""  mADC
 SG_ HU_frontline5_icon : 103|8@0+ (1,0) [0|255] ""  mADC
 SG_ HU_frontline4_icon : 95|8@0+ (1,0) [0|255] ""  mADC
 SG_ HU_frontline3_icon : 87|8@0+ (1,0) [0|255] ""  mADC
 SG_ HU_frontline2_icon : 79|8@0+ (1,0) [0|255] ""  mADC
 SG_ HU_frontline1_icon : 71|8@0+ (1,0) [0|255] ""  mADC
 SG_ HU_backline8_icon : 63|8@0+ (1,0) [0|255] ""  mADC
 SG_ HU_backline7_icon : 55|8@0+ (1,0) [0|255] ""  mADC
 SG_ HU_backline6_icon : 47|8@0+ (1,0) [0|255] ""  mADC
 SG_ HU_backline5_icon : 39|8@0+ (1,0) [0|255] ""  mADC
 SG_ HU_backline4_icon : 31|8@0+ (1,0) [0|255] ""  mADC
 SG_ HU_backline3_icon : 23|8@0+ (1,0) [0|255] ""  mADC
 SG_ HU_backline2_icon : 15|8@0+ (1,0) [0|255] ""  mADC
 SG_ HU_backline1_icon : 7|8@0+ (1,0) [0|255] ""  mADC
 SG_ HU_LineShow : 135|1@0+ (1,0) [0|1] ""  mADC

BO_ 1018 GW_3FA: 8 Vector__XXX
 SG_ ESP_EpbReqAvl : 2|1@0+ (1,0) [0|1] ""  mADC

BO_ 913 GW_391: 8 Vector__XXX
 SG_ PCU_TowingMode : 41|1@0+ (1,0) [0|1] ""  mADC

BO_ 573 GW_23D: 64 Vector__XXX
 SG_ HU_RollingCounter_23D : 491|4@0+ (1,0) [0|15] ""  mADC
 SG_ HU_CRCCheck_23D : 503|16@0+ (1,0) [0|65535] ""  mADC
 SG_ HU_8stRoadTransferTime : 375|16@0+ (1,0) [0|65535] "s"  mADC
 SG_ HU_8stRoadLength : 359|16@0+ (1,0) [0|65535] "m"  mADC
 SG_ HU_8stRoadTrafficStatus : 411|4@0+ (1,0) [0|15] ""  mADC
 SG_ HU_8stRoadNumber : 343|16@0+ (1,0) [0|65535] ""  mADC
 SG_ HU_7stRoadTransferTime : 327|16@0+ (1,0) [0|65535] "s"  mADC
 SG_ HU_7stRoadLength : 311|16@0+ (1,0) [0|65535] "m"  mADC
 SG_ HU_7stRoadTrafficStatus : 415|4@0+ (1,0) [0|15] ""  mADC
 SG_ HU_7stRoadNumber : 295|16@0+ (1,0) [0|65535] ""  mADC
 SG_ HU_6stRoadTransferTime : 279|16@0+ (1,0) [0|65535] "s"  mADC
 SG_ HU_6stRoadLength : 263|16@0+ (1,0) [0|65535] "m"  mADC
 SG_ HU_6stRoadTrafficStatus : 403|4@0+ (1,0) [0|15] ""  mADC
 SG_ HU_6stRoadNumber : 247|16@0+ (1,0) [0|65535] ""  mADC
 SG_ HU_5stRoadTransferTime : 231|16@0+ (1,0) [0|65535] "s"  mADC
 SG_ HU_5stRoadLength : 215|16@0+ (1,0) [0|65535] "m"  mADC
 SG_ HU_5stRoadTrafficStatus : 407|4@0+ (1,0) [0|15] ""  mADC
 SG_ HU_5stRoadNumber : 199|16@0+ (1,0) [0|65535] ""  mADC
 SG_ HU_4stRoadTransferTime : 183|16@0+ (1,0) [0|65535] "s"  mADC
 SG_ HU_4stRoadLength : 167|16@0+ (1,0) [0|65535] "m"  mADC
 SG_ HU_4stRoadTrafficStatus : 395|4@0+ (1,0) [0|15] ""  mADC
 SG_ HU_4stRoadNumber : 151|16@0+ (1,0) [0|65535] ""  mADC
 SG_ HU_3stRoadTransferTime : 135|16@0+ (1,0) [0|65535] "s"  mADC
 SG_ HU_3stRoadLength : 119|16@0+ (1,0) [0|65535] "m"  mADC
 SG_ HU_3stRoadTrafficStatus : 399|4@0+ (1,0) [0|15] ""  mADC
 SG_ HU_3stRoadNumber : 103|16@0+ (1,0) [0|65535] ""  mADC
 SG_ HU_2stRoadTransferTime : 87|16@0+ (1,0) [0|65535] "s"  mADC
 SG_ HU_2stRoadLength : 71|16@0+ (1,0) [0|65535] "m"  mADC
 SG_ HU_2stRoadTrafficStatus : 387|4@0+ (1,0) [0|15] ""  mADC
 SG_ HU_2stRoadNumber : 55|16@0+ (1,0) [0|65535] ""  mADC
 SG_ HU_1stRoadTransferTime : 39|16@0+ (1,0) [0|65535] "s"  mADC
 SG_ HU_1stRoadLength : 23|16@0+ (1,0) [0|65535] "m"  mADC
 SG_ HU_1stRoadTrafficStatus : 391|4@0+ (1,0) [0|15] ""  mADC
 SG_ HU_1stRoadNumber : 7|16@0+ (1,0) [0|65535] ""  mADC

BO_ 392 GW_188: 8 Vector__XXX
 SG_ TCU_ShiftinProgress : 5|1@0+ (1,0) [0|1] ""  mADC

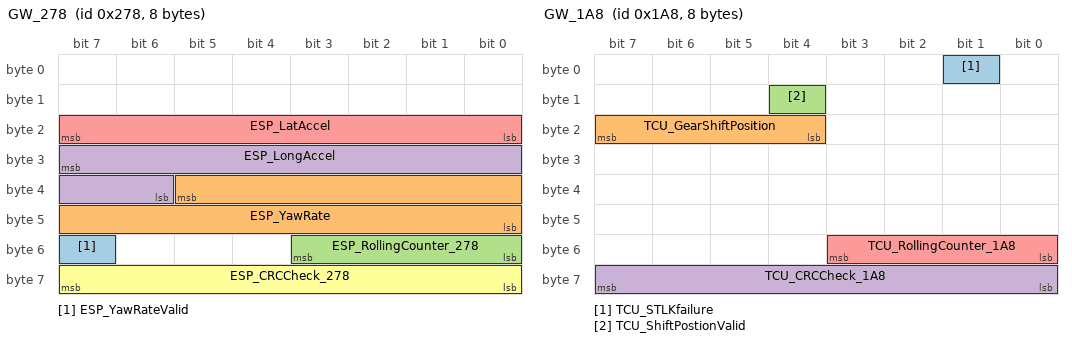
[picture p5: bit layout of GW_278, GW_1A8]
BO_ 632 GW_278: 8 Vector__XXX
 SG_ ESP_YawRateValid : 55|1@0+ (1,0) [0|1] ""  mADC
 SG_ ESP_YawRate : 37|14@0+ (0.01,-81.91) [-81.91|81.91] "degree/s"  mADC
 SG_ ESP_RollingCounter_278 : 51|4@0+ (1,0) [0|15] ""  mADC
 SG_ ESP_LongAccel : 31|10@0+ (0.03125,-16) [-16|15.90625] "m/s2"  mADC
 SG_ ESP_LatAccel : 23|8@0+ (0.1,-12.7) [-12.7|12.7] "m/s2"  mADC
 SG_ ESP_CRCCheck_278 : 63|8@0+ (1,0) [0|255] ""  mADC

BO_ 424 GW_1A8: 8 Vector__XXX
 SG_ TCU_STLKfailure : 1|1@0+ (1,0) [0|1] ""  mADC
 SG_ TCU_GearShiftPosition : 23|4@0+ (1,0) [0|15] ""  mADC
 SG_ TCU_ShiftPostionValid : 12|1@0+ (1,0) [0|1] ""  mADC
 SG_ TCU_CRCCheck_1A8 : 63|8@0+ (1,0) [0|255] ""  mADC
 SG_ TCU_RollingCounter_1A8 : 51|4@0+ (1,0) [0|15] ""  mADC

BO_ 588 GW_24C: 8 Vector__XXX
 SG_ TCU_APAShiftGearRequestEnable : 39|2@0+ (1,0) [0|3] ""  mADC

BO_ 726 GW_2D6: 8 Vector__XXX
 SG_ EMS_AltitudeFactor : 47|8@0+ (0.01575,0) [0|4] ""  mADC

BO_ 1515 GW_5EB: 8 Vector__XXX
 SG_ KeyLearn_Authernticator_5EB : 39|32@0+ (1,0) [1|4294967296] ""  mADC
 SG_ KeyLearn_Random_5EB : 7|32@0+ (1,0) [1|4294967296] ""  mADC

BO_ 901 GW_385: 8 Vector__XXX
 SG_ HU_CDCUnitSystSetStatus : 59|2@0+ (1,0) [0|2] ""  mADC

BO_ 890 GW_37A: 64 Vector__XXX
 SG_ VMC_EcasModeFB : 126|4@0+ (1,0) [0|15] ""  mADC
 SG_ VMC_RollingCounter_37A : 491|4@0+ (1,0) [0|15] ""  mADC
 SG_ VMC_CRCCheck_37A : 503|16@0+ (1,0) [0|65535] ""  mADC
 SG_ VMC_CtrlLevelRRValid : 115|1@0+ (1,0) [0|1] ""  mADC
 SG_ VMC_CtrlLevelRLyValid : 114|1@0+ (1,0) [0|1] ""  mADC
 SG_ VMC_CtrlLevelFRValid : 111|1@0+ (1,0) [0|1] ""  mADC
 SG_ VMC_CtrlLevelFLValid : 110|1@0+ (1,0) [0|1] ""  mADC
 SG_ VMC_LvlTarRR : 183|16@0+ (0.01,-327.67) [-327.67|327.67] ""  mADC
 SG_ VMC_LvlTarRL : 167|16@0+ (0.01,-327.67) [-327.67|327.67] ""  mADC
 SG_ VMC_LvlTarFR : 247|16@0+ (0.01,-327.67) [-327.67|327.67] ""  mADC
 SG_ VMC_LvlTarFL : 231|16@0+ (0.01,-327.67) [-327.67|327.67] ""  mADC
 SG_ VMC_EcasModeRELSts : 107|3@0+ (1,0) [0|7] ""  mADC
 SG_ VMC_EcasModeFRTSts : 113|3@0+ (1,0) [0|7] ""  mADC
 SG_ VMC_EcasModeCHASts : 9|2@0+ (1,0) [0|3] ""  mADC
 SG_ VMC_CtrlLevelRR : 215|16@0+ (0.01,-327.67) [-327.67|327.67] "mm"  mADC
 SG_ VMC_CtrlLevelRL : 199|16@0+ (0.01,-327.67) [-327.67|327.67] "mm"  mADC
 SG_ VMC_CtrlLevelFR : 151|16@0+ (0.01,-327.67) [-327.67|327.67] "mm"  mADC
 SG_ VMC_CtrlLevelFL : 135|16@0+ (0.01,-327.67) [-327.67|327.67] "mm"  mADC
 SG_ VMC_EcasModeVal : 15|1@0+ (1,0) [0|1] ""  mADC
 SG_ VMC_EcdcMode : 3|3@0+ (1,0) [0|4] ""  mADC

CM_ BO_ 1321 " ";
CM_ SG_ 1321 ACC_Target17BSDStatus " ";
CM_ SG_ 1321 ACC_Target16RightLightStatus " ";
CM_ SG_ 1321 ACC_Target16LngRelSpeed " ";
CM_ SG_ 1321 ACC_Target16LngRange " ";
CM_ SG_ 1321 ACC_Target16LeftLightStatus " ";
CM_ SG_ 1321 ACC_Target16LDC " ";
CM_ SG_ 1321 ACC_Target16LatRelSpeed " ";
CM_ SG_ 1321 ACC_Target16LatRange " ";
CM_ SG_ 1321 ACC_Target16ID " ";
CM_ SG_ 1321 ACC_Target16HeadingAngle " ";
CM_ SG_ 1321 ACC_Target16Direction " ";
CM_ SG_ 1321 ACC_Target16Detection " ";
CM_ SG_ 1321 ACC_Target16BSDStatus " ";
CM_ SG_ 1321 ACC_Target16BrakeLightStatus " ";
CM_ SG_ 1321 ACC_Target15ZoneID " ";
CM_ SG_ 1321 ACC_Target15Type " ";
CM_ SG_ 1321 ACC_Target15RightLightStatus " ";
CM_ SG_ 1321 ACC_Target15LngRelSpeed " ";
CM_ SG_ 1321 ACC_Target15LngRange " ";
CM_ SG_ 1321 ACC_Target15LeftLightStatus " ";
CM_ SG_ 1321 ACC_Target15LDC " ";
CM_ SG_ 1321 ACC_Target15LatRelSpeed " ";
CM_ SG_ 1321 ACC_Target15LatRange " ";
CM_ SG_ 1321 ACC_Target15ID " ";
CM_ SG_ 1321 ACC_Target15HeadingAngle " ";
CM_ SG_ 1321 ACC_Target15Direction " ";
CM_ SG_ 1321 ACC_Target15Detection " ";
CM_ SG_ 1321 ACC_Target15BSDStatus " ";
CM_ SG_ 1321 ACC_Target14ZoneID " ";
CM_ SG_ 1321 ACC_Target14Type " ";
CM_ SG_ 1321 ACC_Target14LngRelSpeed " ";
CM_ SG_ 1321 ACC_Target14LngRange " ";
CM_ SG_ 1321 ACC_Target14LeftLightStatus " ";
CM_ SG_ 1321 ACC_Target14LDC " ";
CM_ SG_ 1321 ACC_Target14LatRelSpeed " ";
CM_ SG_ 1321 ACC_Target14LatRange " ";
CM_ SG_ 1321 ACC_Target14ID " ";
CM_ SG_ 1321 ACC_Target14HeadingAngle " ";
CM_ SG_ 1321 ACC_Target14Direction " ";
CM_ SG_ 1321 ACC_Target14Detection " ";
CM_ SG_ 1321 ACC_Target14BSDStatus " ";
CM_ SG_ 1321 ACC_Target14BrakeLightStatus " ";
CM_ SG_ 1321 ACC_Target13ZoneID " ";
CM_ SG_ 1321 ACC_Target13Type " ";
CM_ SG_ 1321 ACC_Target13RightLightStatus " ";
CM_ SG_ 1321 ACC_Target13LngRelSpeed " ";
CM_ SG_ 1321 ACC_Target13LngRange " ";
CM_ SG_ 1321 ACC_Target13LeftLightStatus " ";
CM_ SG_ 1321 ACC_Target13LDC " ";
CM_ SG_ 1321 ACC_Target13LatRelSpeed " ";
CM_ SG_ 1321 ACC_Target13LatRange " ";
CM_ SG_ 1321 ACC_Target13ID " ";
CM_ SG_ 1321 ACC_Target13HeadingAngle " ";
CM_ SG_ 1321 ACC_Target13Direction " ";
CM_ SG_ 1321 ACC_Target13Detection " ";
CM_ SG_ 1321 ACC_Target13BSDStatus " ";
CM_ SG_ 1321 ACC_Target13BrakeLightStatus " ";
CM_ SG_ 1321 ACC_Target12ZoneID " ";
CM_ SG_ 1321 ACC_Target12Type " ";
CM_ SG_ 1321 ACC_Target12RightLightStatus " ";
CM_ SG_ 1321 ACC_Target12LngRelSpeed " ";
CM_ SG_ 1321 ACC_Target12LngRange " ";
CM_ SG_ 1321 ACC_Target12LeftLightStatus " ";
CM_ SG_ 1321 ACC_Target12LDC " ";
CM_ SG_ 1321 ACC_Target12LatRelSpeed " ";
CM_ SG_ 1321 ACC_Target12LatRange " ";
CM_ SG_ 1321 ACC_Target12ID " ";
CM_ SG_ 1321 ACC_Target12HeadingAngle " ";
CM_ SG_ 1321 ACC_Target12Direction " ";
CM_ SG_ 1321 ACC_Target12Detection " ";
CM_ SG_ 1321 ACC_Target12BSDStatus " ";
CM_ SG_ 1321 ACC_Target12BrakeLightStatus " ";
CM_ SG_ 1321 ACC_Target11ZoneID " ";
CM_ SG_ 1321 ACC_Target11RightLightStatus " ";
CM_ SG_ 1321 ACC_Target11LngRelSpeed " ";
CM_ SG_ 1321 ACC_Target11LngRange " ";
CM_ BO_ 1323 " ";
CM_ SG_ 1323 ACC_Target22BSDStatus " ";
CM_ SG_ 1323 ACC_Target21RightLightStatus " ";
CM_ SG_ 1323 ACC_Target21LngRange " ";
CM_ SG_ 1323 ACC_Target21LeftLightStatus " ";
CM_ SG_ 1323 ACC_Target21LDC " ";
CM_ SG_ 1323 ACC_Target21LatRelSpeed " ";
CM_ SG_ 1323 ACC_Target21LatRange " ";
CM_ SG_ 1323 ACC_Target21HeadingAngle " ";
CM_ SG_ 1323 ACC_Target21Direction " ";
CM_ SG_ 1323 ACC_Target21Detection " ";
CM_ SG_ 1323 ACC_Target21BSDStatus " ";
CM_ SG_ 1323 ACC_Target21BrakeLightStatus " ";
CM_ SG_ 1323 ACC_Target20ZoneID " ";
CM_ SG_ 1323 ACC_Target20Type " ";
CM_ SG_ 1323 ACC_Target20RightLightStatus " ";
CM_ SG_ 1323 ACC_Target20LngRelSpeed " ";
CM_ SG_ 1323 ACC_Target20LngRange " ";
CM_ SG_ 1323 ACC_Target20LeftLightStatus " ";
CM_ SG_ 1323 ACC_Target20LDC " ";
CM_ SG_ 1323 ACC_Target20LatRelSpeed " ";
CM_ SG_ 1323 ACC_Target20LatRange " ";
CM_ SG_ 1323 ACC_Target20ID " ";
CM_ SG_ 1323 ACC_Target20HeadingAngle " ";
CM_ SG_ 1323 ACC_Target20Direction " ";
CM_ SG_ 1323 ACC_Target20Detection " ";
CM_ SG_ 1323 ACC_Target20BSDStatus " ";
CM_ SG_ 1323 ACC_Target20BrakeLightStatus " ";
CM_ SG_ 1323 ACC_Target1RightLightStatus " ";
CM_ SG_ 1323 ACC_Target1LngRelSpeed " ";
CM_ SG_ 1323 ACC_Target1LeftLightStatus " ";
CM_ SG_ 1323 ACC_Target1LDC " ";
CM_ SG_ 1323 ACC_Target1LatRelSpeed " ";
CM_ SG_ 1323 ACC_Target1BSDStatus " ";
CM_ SG_ 1323 ACC_Target1BrakeLightStatus " ";
CM_ SG_ 1323 ACC_Target19ZoneID " ";
CM_ SG_ 1323 ACC_Target19Type " ";
CM_ SG_ 1323 ACC_Target19RightLightStatus " ";
CM_ SG_ 1323 ACC_Target19LngRelSpeed " ";
CM_ SG_ 1323 ACC_Target19LngRange " ";
CM_ SG_ 1323 ACC_Target19LeftLightStatus " ";
CM_ SG_ 1323 ACC_Target19LDC " ";
CM_ SG_ 1323 ACC_Target19LatRelSpeed " ";
CM_ SG_ 1323 ACC_Target19LatRange " ";
CM_ SG_ 1323 ACC_Target19ID " ";
CM_ SG_ 1323 ACC_Target19HeadingAngle " ";
CM_ SG_ 1323 ACC_Target19Direction " ";
CM_ SG_ 1323 ACC_Target19Detection " ";
CM_ SG_ 1323 ACC_Target19BSDStatus " ";
CM_ SG_ 1323 ACC_Target19BrakeLightStatus " ";
CM_ SG_ 1323 ACC_Target18ZoneID " ";
CM_ SG_ 1323 ACC_Target18Type " ";
CM_ SG_ 1323 ACC_Target18RightLightStatus " ";
CM_ SG_ 1323 ACC_Target18LngRelSpeed " ";
CM_ SG_ 1323 ACC_Target18LngRange " ";
CM_ SG_ 1323 ACC_Target18LeftLightStatus " ";
CM_ SG_ 1323 ACC_Target18LDC " ";
CM_ SG_ 1323 ACC_Target18LatRelSpeed " ";
CM_ SG_ 1323 ACC_Target18LatRange " ";
CM_ SG_ 1323 ACC_Target18ID " ";
CM_ SG_ 1323 ACC_Target18HeadingAngle " ";
CM_ SG_ 1323 ACC_Target18Direction " ";
CM_ SG_ 1323 ACC_Target18Detection " ";
CM_ SG_ 1323 ACC_Target18BSDStatus " ";
CM_ SG_ 1323 ACC_Target18BrakeLightStatus " ";
CM_ SG_ 1323 ACC_Target17ZoneID " ";
CM_ SG_ 1323 ACC_Target17Type " ";
CM_ SG_ 1323 ACC_Target17RightLightStatus " ";
CM_ SG_ 1323 ACC_Target17LngRelSpeed " ";
CM_ SG_ 1323 ACC_Target17LngRange " ";
CM_ SG_ 1323 ACC_Target17LeftLightStatus " ";
CM_ SG_ 1323 ACC_Target17LDC " ";
CM_ SG_ 1323 ACC_Target17LatRelSpeed " ";
CM_ SG_ 1323 ACC_Target17LatRange " ";
CM_ SG_ 1323 ACC_Target17ID " ";
CM_ SG_ 1323 ACC_Target17HeadingAngle " ";
CM_ SG_ 1323 ACC_Target17Direction " ";
CM_ SG_ 1323 ACC_Target17Detection " ";
CM_ SG_ 1323 ACC_Target17BrakeLightStatus " ";
CM_ SG_ 1323 ACC_Target16ZoneID " ";
CM_ SG_ 1323 ACC_Target16Type " ";
CM_ BO_ 1329 " ";
CM_ SG_ 1329 ACC_Target27BrakeLightStatus " ";
CM_ SG_ 1329 ACC_Target26ZoneID " ";
CM_ SG_ 1329 ACC_Target26RightLightStatus " ";
CM_ SG_ 1329 ACC_Target26LngRange " ";
CM_ SG_ 1329 ACC_Target26LeftLightStatus " ";
CM_ SG_ 1329 ACC_Target26LDC " ";
CM_ SG_ 1329 ACC_Target26LatRelSpeed " ";
CM_ SG_ 1329 ACC_Target26LatRange " ";
CM_ SG_ 1329 ACC_Target26ID " ";
CM_ SG_ 1329 ACC_Target26HeadingAngle " ";
CM_ SG_ 1329 ACC_Target26Direction " ";
CM_ SG_ 1329 ACC_Target26Detection " ";
CM_ SG_ 1329 ACC_Target26BSDStatus " ";
CM_ SG_ 1329 ACC_Target26BrakeLightStatus " ";
CM_ SG_ 1329 ACC_Target25ZoneID " ";
CM_ SG_ 1329 ACC_Target25Type " ";
CM_ SG_ 1329 ACC_Target25RightLightStatus " ";
CM_ SG_ 1329 ACC_Target25LngRelSpeed " ";
CM_ SG_ 1329 ACC_Target25LngRange " ";
CM_ SG_ 1329 ACC_Target25LeftLightStatus " ";
CM_ SG_ 1329 ACC_Target25LDC " ";
CM_ SG_ 1329 ACC_Target25LatRelSpeed " ";
CM_ SG_ 1329 ACC_Target25LatRange " ";
CM_ SG_ 1329 ACC_Target25ID " ";
CM_ SG_ 1329 ACC_Target25HeadingAngle " ";
CM_ SG_ 1329 ACC_Target25Direction " ";
CM_ SG_ 1329 ACC_Target25Detection " ";
CM_ SG_ 1329 ACC_Target25BSDStatus " ";
CM_ SG_ 1329 ACC_Target25BrakeLightStatus " ";
CM_ SG_ 1329 ACC_Target24ZoneID " ";
CM_ SG_ 1329 ACC_Target24Type " ";
CM_ SG_ 1329 ACC_Target24RightLightStatus " ";
CM_ SG_ 1329 ACC_Target24LngRelSpeed " ";
CM_ SG_ 1329 ACC_Target24LngRange " ";
CM_ SG_ 1329 ACC_Target24LeftLightStatus " ";
CM_ SG_ 1329 ACC_Target24LDC " ";
CM_ SG_ 1329 ACC_Target24LatRelSpeed " ";
CM_ SG_ 1329 ACC_Target24LatRange " ";
CM_ SG_ 1329 ACC_Target24ID " ";
CM_ SG_ 1329 ACC_Target24HeadingAngle " ";
CM_ SG_ 1329 ACC_Target24Direction " ";
CM_ SG_ 1329 ACC_Target24Detection " ";
CM_ SG_ 1329 ACC_Target24BSDStatus " ";
CM_ SG_ 1329 ACC_Target24BrakeLightStatus " ";
CM_ SG_ 1329 ACC_Target23ZoneID " ";
CM_ SG_ 1329 ACC_Target23Type " ";
CM_ SG_ 1329 ACC_Target23RightLightStatus " ";
CM_ SG_ 1329 ACC_Target23LngRelSpeed " ";
CM_ SG_ 1329 ACC_Target23LngRange " ";
CM_ SG_ 1329 ACC_Target23LeftLightStatus " ";
CM_ SG_ 1329 ACC_Target23LDC " ";
CM_ SG_ 1329 ACC_Target23LatRelSpeed " ";
CM_ SG_ 1329 ACC_Target23LatRange " ";
CM_ SG_ 1329 ACC_Target23ID " ";
CM_ SG_ 1329 ACC_Target23HeadingAngle " ";
CM_ SG_ 1329 ACC_Target23Direction " ";
CM_ SG_ 1329 ACC_Target23Detection " ";
CM_ SG_ 1329 ACC_Target23BSDStatus " ";
CM_ SG_ 1329 ACC_Target23BrakeLightStatus " ";
CM_ SG_ 1329 ACC_Target22ZoneID " ";
CM_ SG_ 1329 ACC_Target22Type " ";
CM_ SG_ 1329 ACC_Target22RightLightStatus " ";
CM_ SG_ 1329 ACC_Target22LngRelSpeed " ";
CM_ SG_ 1329 ACC_Target22LngRange " ";
CM_ SG_ 1329 ACC_Target22LeftLightStatus " ";
CM_ SG_ 1329 ACC_Target22LDC " ";
CM_ SG_ 1329 ACC_Target22LatRelSpeed " ";
CM_ SG_ 1329 ACC_Target22LatRange " ";
CM_ SG_ 1329 ACC_Target22ID " ";
CM_ SG_ 1329 ACC_Target22HeadingAngle " ";
CM_ SG_ 1329 ACC_Target22Direction " ";
CM_ SG_ 1329 ACC_Target22Detection " ";
CM_ SG_ 1329 ACC_Target22BrakeLightStatus " ";
CM_ SG_ 1329 ACC_Target21ZoneID " ";
CM_ SG_ 1329 ACC_Target21Type " ";
CM_ SG_ 1329 ACC_Target21LngRelSpeed " ";
CM_ SG_ 1329 ACC_Target21ID " ";
CM_ BO_ 1330 " ";
CM_ SG_ 1330 ACC_Target31LngRange " ";
CM_ SG_ 1330 ACC_Target31LeftLightStatus " ";
CM_ SG_ 1330 ACC_Target31LDC " ";
CM_ SG_ 1330 ACC_Target31LatRelSpeed " ";
CM_ SG_ 1330 ACC_Target31LatRange " ";
CM_ SG_ 1330 ACC_Target31ID " ";
CM_ SG_ 1330 ACC_Target31HeadingAngle " ";
CM_ SG_ 1330 ACC_Target31Direction " ";
CM_ SG_ 1330 ACC_Target31Detection " ";
CM_ SG_ 1330 ACC_Target31BSDStatus " ";
CM_ SG_ 1330 ACC_Target31BrakeLightStatus " ";
CM_ SG_ 1330 ACC_Target30ZoneID " ";
CM_ SG_ 1330 ACC_Target30Type " ";
CM_ SG_ 1330 ACC_Target30RightLightStatus " ";
CM_ SG_ 1330 ACC_Target30LngRelSpeed " ";
CM_ SG_ 1330 ACC_Target30LngRange " ";
CM_ SG_ 1330 ACC_Target30LeftLightStatus " ";
CM_ SG_ 1330 ACC_Target30LDC " ";
CM_ SG_ 1330 ACC_Target30LatRelSpeed " ";
CM_ SG_ 1330 ACC_Target30LatRange " ";
CM_ SG_ 1330 ACC_Target30ID " ";
CM_ SG_ 1330 ACC_Target30HeadingAngle " ";
CM_ SG_ 1330 ACC_Target30Direction " ";
CM_ SG_ 1330 ACC_Target30Detection " ";
CM_ SG_ 1330 ACC_Target30BSDStatus " ";
CM_ SG_ 1330 ACC_Target30BrakeLightStatus " ";
CM_ SG_ 1330 ACC_Target2RightLightStatus " ";
CM_ SG_ 1330 ACC_Target2LngRelSpeed " ";
CM_ SG_ 1330 ACC_Target2LeftLightStatus " ";
CM_ SG_ 1330 ACC_Target2LDC " ";
CM_ SG_ 1330 ACC_Target2LatRelSpeed " ";
CM_ SG_ 1330 ACC_Target2BSDStatus " ";
CM_ SG_ 1330 ACC_Target2BrakeLightStatus " ";
CM_ SG_ 1330 ACC_Target29ZoneID " ";
CM_ SG_ 1330 ACC_Target29Type " ";
CM_ SG_ 1330 ACC_Target29RightLightStatus " ";
CM_ SG_ 1330 ACC_Target29LngRelSpeed " ";
CM_ SG_ 1330 ACC_Target29LngRange " ";
CM_ SG_ 1330 ACC_Target29LeftLightStatus " ";
CM_ SG_ 1330 ACC_Target29LDC " ";
CM_ SG_ 1330 ACC_Target29LatRelSpeed " ";
CM_ SG_ 1330 ACC_Target29LatRange " ";
CM_ SG_ 1330 ACC_Target29ID " ";
CM_ SG_ 1330 ACC_Target29HeadingAngle " ";
CM_ SG_ 1330 ACC_Target29Direction " ";
CM_ SG_ 1330 ACC_Target29Detection " ";
CM_ SG_ 1330 ACC_Target29BSDStatus " ";
CM_ SG_ 1330 ACC_Target29BrakeLightStatus " ";
CM_ SG_ 1330 ACC_Target28ZoneID " ";
CM_ SG_ 1330 ACC_Target28Type " ";
CM_ SG_ 1330 ACC_Target28RightLightStatus " ";
CM_ SG_ 1330 ACC_Target28LngRelSpeed " ";
CM_ SG_ 1330 ACC_Target28LngRange " ";
CM_ SG_ 1330 ACC_Target28LeftLightStatus " ";
CM_ SG_ 1330 ACC_Target28LDC " ";
CM_ SG_ 1330 ACC_Target28LatRelSpeed " ";
CM_ SG_ 1330 ACC_Target28LatRange " ";
CM_ SG_ 1330 ACC_Target28ID " ";
CM_ SG_ 1330 ACC_Target28HeadingAngle " ";
CM_ SG_ 1330 ACC_Target28Direction " ";
CM_ SG_ 1330 ACC_Target28Detection " ";
CM_ SG_ 1330 ACC_Target28BSDStatus " ";
CM_ SG_ 1330 ACC_Target28BrakeLightStatus " ";
CM_ SG_ 1330 ACC_Target27ZoneID " ";
CM_ SG_ 1330 ACC_Target27Type " ";
CM_ SG_ 1330 ACC_Target27RightLightStatus " ";
CM_ SG_ 1330 ACC_Target27LngRelSpeed " ";
CM_ SG_ 1330 ACC_Target27LngRange " ";
CM_ SG_ 1330 ACC_Target27LeftLightStatus " ";
CM_ SG_ 1330 ACC_Target27LDC " ";
CM_ SG_ 1330 ACC_Target27LatRelSpeed " ";
CM_ SG_ 1330 ACC_Target27LatRange " ";
CM_ SG_ 1330 ACC_Target27ID " ";
CM_ SG_ 1330 ACC_Target27HeadingAngle " ";
CM_ SG_ 1330 ACC_Target27Direction " ";
CM_ SG_ 1330 ACC_Target27Detection " ";
CM_ SG_ 1330 ACC_Target27BSDStatus " ";
CM_ SG_ 1330 ACC_Target26Type " ";
CM_ SG_ 1330 ACC_Target26LngRelSpeed " ";
CM_ BO_ 1331 " ";
CM_ SG_ 1331 APA_DynamicButton " ";
CM_ SG_ 1331 APA_DLPReq " ";
CM_ SG_ 1331 APA_DetailedVoice_Switch " ";
CM_ SG_ 1331 APA_BackstageSearchSts " ";
CM_ SG_ 1331 ADS_IACCSysdeactiveReason " ";
CM_ SG_ 1331 ADS_IACC_LatTakeOverReason " ";
CM_ SG_ 1331 ACC_RLaneQuality " ";
CM_ SG_ 1331 ACC_RedLightRemindEnable " ";
CM_ SG_ 1331 ACC_DOSECountDown " ";
CM_ SG_ 1331 ACC_Target9ZoneID " ";
CM_ SG_ 1331 ACC_Target9Type " ";
CM_ SG_ 1331 ACC_Target9RightLightStatus " ";
CM_ SG_ 1331 ACC_Target9LngRelSpeed " ";
CM_ SG_ 1331 ACC_Target9LngRange " ";
CM_ SG_ 1331 ACC_Target9LeftLightStatus " ";
CM_ SG_ 1331 ACC_Target9LDC " ";
CM_ SG_ 1331 ACC_Target9LatRelSpeed " ";
CM_ SG_ 1331 ACC_Target9LatRange " ";
CM_ SG_ 1331 ACC_Target9ID " ";
CM_ SG_ 1331 ACC_Target9HeadingAngle " ";
CM_ SG_ 1331 ACC_Target9Direction " ";
CM_ SG_ 1331 ACC_Target9Detection " ";
CM_ SG_ 1331 ACC_Target9BSDStatus " ";
CM_ SG_ 1331 ACC_Target9BrakeLightStatus " ";
CM_ SG_ 1331 ACC_Target8ZoneID " ";
CM_ SG_ 1331 ACC_Target8Type " ";
CM_ SG_ 1331 ACC_Target8RightLightStatus " ";
CM_ SG_ 1331 ACC_Target8LngRelSpeed " ";
CM_ SG_ 1331 ACC_Target8LngRange " ";
CM_ SG_ 1331 ACC_Target8LeftLightStatus " ";
CM_ SG_ 1331 ACC_Target8LDC " ";
CM_ SG_ 1331 ACC_Target8LatRelSpeed " ";
CM_ SG_ 1331 ACC_Target8LatRange " ";
CM_ SG_ 1331 ACC_Target8ID " ";
CM_ SG_ 1331 ACC_Target8HeadingAngle " ";
CM_ SG_ 1331 ACC_Target8Direction " ";
CM_ SG_ 1331 ACC_Target8Detection " ";
CM_ SG_ 1331 ACC_Target8BSDStatus " ";
CM_ SG_ 1331 ACC_Target8BrakeLightStatus " ";
CM_ SG_ 1331 ACC_Target7RightLightStatus " ";
CM_ SG_ 1331 ACC_Target7LngRelSpeed " ";
CM_ SG_ 1331 ACC_Target7LeftLightStatus " ";
CM_ SG_ 1331 ACC_Target7LDC " ";
CM_ SG_ 1331 ACC_Target7LatRelSpeed " ";
CM_ SG_ 1331 ACC_Target7BSDStatus " ";
CM_ SG_ 1331 ACC_Target7BrakeLightStatus " ";
CM_ SG_ 1331 ACC_Target6RightLightStatus " ";
CM_ SG_ 1331 ACC_Target6LngRelSpeed " ";
CM_ SG_ 1331 ACC_Target6LeftLightStatus " ";
CM_ SG_ 1331 ACC_Target6LDC " ";
CM_ SG_ 1331 ACC_Target6LatRelSpeed " ";
CM_ SG_ 1331 ACC_Target6BSDStatus " ";
CM_ SG_ 1331 ACC_Target6BrakeLightStatus " ";
CM_ SG_ 1331 ACC_Target5RightLightStatus " ";
CM_ SG_ 1331 ACC_Target5LngRelSpeed " ";
CM_ SG_ 1331 ACC_Target5LeftLightStatus " ";
CM_ SG_ 1331 ACC_Target5LDC " ";
CM_ SG_ 1331 ACC_Target5LatRelSpeed " ";
CM_ SG_ 1331 ACC_Target5BSDStatus " ";
CM_ SG_ 1331 ACC_Target5BrakeLightStatus " ";
CM_ SG_ 1331 ACC_Target4RightLightStatus " ";
CM_ SG_ 1331 ACC_Target4LngRelSpeed " ";
CM_ SG_ 1331 ACC_Target4LeftLightStatus " ";
CM_ SG_ 1331 ACC_Target4LDC " ";
CM_ SG_ 1331 ACC_Target4LatRelSpeed " ";
CM_ SG_ 1331 ACC_Target4BSDStatus " ";
CM_ SG_ 1331 ACC_Target4BrakeLightStatus " ";
CM_ SG_ 1331 ACC_Target3RightLightStatus " ";
CM_ SG_ 1331 ACC_Target3LngRelSpeed " ";
CM_ SG_ 1331 ACC_Target3LeftLightStatus " ";
CM_ SG_ 1331 ACC_Target3LDC " ";
CM_ SG_ 1331 ACC_Target3LatRelSpeed " ";
CM_ SG_ 1331 ACC_Target3BSDStatus " ";
CM_ SG_ 1331 ACC_Target3BrakeLightStatus " ";
CM_ SG_ 1331 ACC_Target32ZoneID " ";
CM_ SG_ 1331 ACC_Target32Type " ";
CM_ SG_ 1331 ACC_Target32RightLightStatus " ";
CM_ SG_ 1331 ACC_Target32LngRelSpeed " ";
CM_ SG_ 1331 ACC_Target32LngRange " ";
CM_ SG_ 1331 ACC_Target32LeftLightStatus " ";
CM_ SG_ 1331 ACC_Target32LDC " ";
CM_ SG_ 1331 ACC_Target32LatRelSpeed " ";
CM_ SG_ 1331 ACC_Target32LatRange " ";
CM_ SG_ 1331 ACC_Target32ID " ";
CM_ SG_ 1331 ACC_Target32HeadingAngle " ";
CM_ SG_ 1331 ACC_Target32Direction " ";
CM_ SG_ 1331 ACC_Target32Detection " ";
CM_ SG_ 1331 ACC_Target32BSDStatus " ";
CM_ SG_ 1331 ACC_Target32BrakeLightStatus " ";
CM_ SG_ 1331 ACC_Target31ZoneID " ";
CM_ SG_ 1331 ACC_Target31Type " ";
CM_ SG_ 1331 ACC_Target31RightLightStatus " ";
CM_ SG_ 1331 ACC_Target31LngRelSpeed " ";
CM_ BO_ 959 "源端HybridA_PCU_33B,6 ";
CM_ SG_ 959 PCU_DteDisp " ";
CM_ BO_ 429 "GW自发 ";
CM_ BO_ 1517 "GW与mADC消息认证，电检秘钥学习流程的ID ";
CM_ SG_ 1517 KeyLearn_Authernticator_5ED "见《车端消息认证集成规范》 ";
CM_ SG_ 1517 KeyLearn_Random_5ED "见《车端消息认证集成规范》 ";
CM_ BO_ 1423 " ";
CM_ SG_ 1423 mADC_NotSleep_BYTE7BIT6 " ";
CM_ SG_ 1423 mADC_NotSleep_BYTE7BIT5 " ";
CM_ SG_ 1423 mADC_NotSleep_BYTE7BIT4 " ";
CM_ SG_ 1423 mADC_NotSleep_BYTE7BIT3 " ";
CM_ SG_ 1423 mADC_NotSleep_BYTE7BIT2 " ";
CM_ SG_ 1423 mADC_NotSleep_BYTE7BIT1 " ";
CM_ SG_ 1423 mADC_NotSleep_BYTE7BIT0 " ";
CM_ SG_ 1423 mADC_WakeUp_BYTE4BIT1 " ";
CM_ SG_ 1423 mADC_WakeUp_BYTE4BIT0 " ";
CM_ BO_ 958 " ";
CM_ BO_ 1718 " ";
CM_ SG_ 1718 IQSoftwareversion_P "UTF-8编码 ";
CM_ SG_ 1718 IQSoftwareversion_D "UTF-8编码 ";
CM_ SG_ 1718 IQSoftwareversion_R "UTF-8编码 ";
CM_ SG_ 1718 IQSoftwareversion_F "UTF-8编码 ";
CM_ BO_ 1430 " ";
CM_ SG_ 1430 LCDAL_NotSleep_BYTE7BIT4 " ";
CM_ SG_ 1430 LCDAL_NotSleep_BYTE7BIT3 " ";
CM_ SG_ 1430 LCDAL_NotSleep_BYTE7BIT2 " ";
CM_ SG_ 1430 LCDAL_NotSleep_BYTE7BIT1 " ";
CM_ SG_ 1430 LCDAL_NotSleep_BYTE7BIT0 " ";
CM_ SG_ 1430 LCDAL_WakeUp_BYTE4BIT1 " ";
CM_ SG_ 1430 LCDAL_WakeUp_BYTE4BIT0 " ";
CM_ BO_ 1431 " ";
CM_ SG_ 1431 LCDAR_NotSleep_BYTE7BIT4 " ";
CM_ SG_ 1431 LCDAR_NotSleep_BYTE7BIT3 " ";
CM_ SG_ 1431 LCDAR_NotSleep_BYTE7BIT2 " ";
CM_ SG_ 1431 LCDAR_NotSleep_BYTE7BIT1 " ";
CM_ SG_ 1431 LCDAR_NotSleep_BYTE7BIT0 " ";
CM_ SG_ 1431 LCDAR_WakeUp_BYTE4BIT1 " ";
CM_ SG_ 1431 LCDAR_WakeUp_BYTE4BIT0 " ";
CM_ BO_ 1432 " ";
CM_ SG_ 1432 FRR_NotSleep_BYTE7BIT1 " ";
CM_ SG_ 1432 FRR_NotSleep_BYTE7BIT0 " ";
CM_ SG_ 1432 FRR_WakeUp_BYTE4BIT1 " ";
CM_ SG_ 1432 FRR_WakeUp_BYTE4BIT0 " ";
CM_ BO_ 1442 " ";
CM_ SG_ 1442 FLR_NotSleep_BYTE7BIT1 " ";
CM_ SG_ 1442 FLR_NotSleep_BYTE7BIT0 " ";
CM_ SG_ 1442 FLR_WakeUp_BYTE4BIT1 " ";
CM_ SG_ 1442 FLR_WakeUp_BYTE4BIT0 " ";
CM_ BO_ 1687 " ";
CM_ SG_ 1687 LCDAL_DTC2_Status "DTC上传 ";
CM_ SG_ 1687 LCDAL_DTC2_LowByte "DTC上传 ";
CM_ SG_ 1687 LCDAL_DTC2_MiddByte "DTC上传 ";
CM_ SG_ 1687 LCDAL_DTC2_HighByte "DTC上传 ";
CM_ SG_ 1687 LCDAL_DTC1_Status "DTC上传 ";
CM_ SG_ 1687 LCDAL_DTC1_LowByte "DTC上传 ";
CM_ SG_ 1687 LCDAL_DTC1_MiddByte "DTC上传 ";
CM_ SG_ 1687 LCDAL_DTC1_HighByte "DTC上传 ";
CM_ BO_ 1755 " ";
CM_ SG_ 1755 LCDAR_DTC2_Status "DTC上传 ";
CM_ SG_ 1755 LCDAR_DTC2_LowByte "DTC上传 ";
CM_ SG_ 1755 LCDAR_DTC2_MiddByte "DTC上传 ";
CM_ SG_ 1755 LCDAR_DTC2_HighByte "DTC上传 ";
CM_ SG_ 1755 LCDAR_DTC1_Status "DTC上传 ";
CM_ SG_ 1755 LCDAR_DTC1_LowByte "DTC上传 ";
CM_ SG_ 1755 LCDAR_DTC1_MiddByte "DTC上传 ";
CM_ SG_ 1755 LCDAR_DTC1_HighByte "DTC上传 ";
CM_ BO_ 1763 " ";
CM_ SG_ 1763 FLR_DTC2_Status "DTC上传 ";
CM_ SG_ 1763 FLR_DTC2_LowByte "DTC上传 ";
CM_ SG_ 1763 FLR_DTC2_MiddByte "DTC上传 ";
CM_ SG_ 1763 FLR_DTC2_HighByte "DTC上传 ";
CM_ SG_ 1763 FLR_DTC1_Status "DTC上传 ";
CM_ SG_ 1763 FLR_DTC1_LowByte "DTC上传 ";
CM_ SG_ 1763 FLR_DTC1_MiddByte "DTC上传 ";
CM_ SG_ 1763 FLR_DTC1_HighByte "DTC上传 ";
CM_ BO_ 1776 " ";
CM_ SG_ 1776 FRR_DTC2_Status "DTC上传 ";
CM_ SG_ 1776 FRR_DTC2_LowByte "DTC上传 ";
CM_ SG_ 1776 FRR_DTC2_MiddByte "DTC上传 ";
CM_ SG_ 1776 FRR_DTC2_HighByte "DTC上传 ";
CM_ SG_ 1776 FRR_DTC1_Status "DTC上传 ";
CM_ SG_ 1776 FRR_DTC1_LowByte "DTC上传 ";
CM_ SG_ 1776 FRR_DTC1_MiddByte "DTC上传 ";
CM_ SG_ 1776 FRR_DTC1_HighByte "DTC上传 ";
CM_ BO_ 2015 "mADC/C3B报文路由至ADASB/ADASC/ADASE ";
CM_ BO_ 1937 "1、使用CAN诊断仪时发送报文DLC长度为8，使用CANFD诊断仪时发送报文DLC长度为8到64
2、mADC报文路由至ADASE ";
CM_ BO_ 1945 "mADC转发ADASE报文（报文路由） ";
CM_ BO_ 1895 "1、使用CAN诊断仪时发送报文DLC长度为8，使用CANFD诊断仪时发送报文DLC长度为8到64
2、mADC报文路由至ADASC ";
CM_ BO_ 1903 "mADC转发ADASC报文（报文路由） ";
CM_ BO_ 1894 "1、使用CAN诊断仪时发送报文DLC长度为8，使用CANFD诊断仪时发送报文DLC长度为8到64
2、mADC报文路由至ADASC ";
CM_ BO_ 1902 "mADC转发ADASC报文（报文路由） ";
CM_ BO_ 1875 "1、使用CAN诊断仪时发送报文DLC长度为8，使用CANFD诊断仪时发送报文DLC长度为8到64
2、mADC报文路由至ADASB ";
CM_ BO_ 1883 "mADC转发ADASB报文（报文路由） ";
CM_ BO_ 1876 "1、使用CAN诊断仪时发送报文DLC长度为8，使用CANFD诊断仪时发送报文DLC长度为8到64
2、mADC报文路由至ADASB ";
CM_ BO_ 1884 "mADC转发ADASB报文（报文路由） ";
CM_ BO_ 1890 "使用CAN诊断仪时发送报文DLC长度为8，使用CANFD诊断仪时发送报文DLC长度为8到64 ";
CM_ BO_ 1898 " ";
CM_ BO_ 953 " ";
CM_ BO_ 691 "源端INFO_THU_364,2 ";
CM_ BO_ 989 " ";
CM_ BO_ 1018 "源端CHS_EPBi/IBCU_337,1 ";
CM_ SG_ 1018 ESP_EpbReqAvl "CHS_IBCU_337,1 ";
CM_ BO_ 913 "源端HybridA_PCU_33B,4 ";
CM_ SG_ 913 PCU_TowingMode " ";
CM_ BO_ 573 " ";
CM_ SG_ 573 HU_RollingCounter_23D " ";
CM_ SG_ 573 HU_CRCCheck_23D " ";
CM_ SG_ 573 HU_8stRoadTransferTime " ";
CM_ SG_ 573 HU_8stRoadLength " ";
CM_ SG_ 573 HU_8stRoadTrafficStatus " ";
CM_ SG_ 573 HU_8stRoadNumber " ";
CM_ SG_ 573 HU_7stRoadTransferTime " ";
CM_ SG_ 573 HU_7stRoadLength " ";
CM_ SG_ 573 HU_7stRoadTrafficStatus " ";
CM_ SG_ 573 HU_7stRoadNumber " ";
CM_ SG_ 573 HU_6stRoadTransferTime " ";
CM_ SG_ 573 HU_6stRoadLength " ";
CM_ SG_ 573 HU_6stRoadTrafficStatus " ";
CM_ SG_ 573 HU_6stRoadNumber " ";
CM_ SG_ 573 HU_5stRoadTransferTime " ";
CM_ SG_ 573 HU_5stRoadLength " ";
CM_ SG_ 573 HU_5stRoadTrafficStatus " ";
CM_ SG_ 573 HU_5stRoadNumber " ";
CM_ SG_ 573 HU_4stRoadTransferTime " ";
CM_ SG_ 573 HU_4stRoadLength " ";
CM_ SG_ 573 HU_4stRoadTrafficStatus " ";
CM_ SG_ 573 HU_4stRoadNumber " ";
CM_ SG_ 573 HU_3stRoadTransferTime " ";
CM_ SG_ 573 HU_3stRoadLength " ";
CM_ SG_ 573 HU_3stRoadTrafficStatus " ";
CM_ SG_ 573 HU_3stRoadNumber " ";
CM_ SG_ 573 HU_2stRoadTransferTime " ";
CM_ SG_ 573 HU_2stRoadLength " ";
CM_ SG_ 573 HU_2stRoadTrafficStatus " ";
CM_ SG_ 573 HU_2stRoadNumber " ";
CM_ SG_ 573 HU_1stRoadTransferTime " ";
CM_ SG_ 573 HU_1stRoadLength " ";
CM_ SG_ 573 HU_1stRoadTrafficStatus " ";
CM_ SG_ 573 HU_1stRoadNumber " ";
CM_ BO_ 392 " ";
CM_ SG_ 392 TCU_ShiftinProgress "AT/DCT ";
CM_ BO_ 632 " ";
CM_ SG_ 632 ESP_YawRate "右正左负（举例理解=水平路面向
右转弯时，发正值。反之发负值） ";
CM_ SG_ 632 ESP_LongAccel "举例理解=水平路面直线加速
时，发正值。反之发负值。 ";
CM_ SG_ 632 ESP_LatAccel "右正左负（举例理解=水平路面向
右转弯时，发正值。反之发负值） ";
CM_ BO_ 424 " ";
CM_ SG_ 424 TCU_STLKfailure "AT/DCT ";
CM_ SG_ 424 TCU_GearShiftPosition "AT/DCT
ACM接收为AT专用 ";
CM_ SG_ 424 TCU_ShiftPostionValid "AT/DCT
ACM接收为AT专用 ";
CM_ SG_ 424 TCU_CRCCheck_1A8 "ACM接收为AT专用 ";
CM_ SG_ 424 TCU_RollingCounter_1A8 "AT/DCT
ACM接收为AT专用
rollingcounter ";
CM_ BO_ 588 " ";
CM_ SG_ 588 TCU_APAShiftGearRequestEnable "DCT专用 ";
CM_ BO_ 726 " ";
CM_ BO_ 1515 "GW与mADC消息认证，电检秘钥学习流程的ID ";
CM_ SG_ 1515 KeyLearn_Authernticator_5EB "见《车端消息认证集成规范》 ";
CM_ SG_ 1515 KeyLearn_Random_5EB "见《车端消息认证集成规范》 ";
CM_ BO_ 901 "源端INFO_IP/THU_3D5,0 ";
CM_ BO_ 890 " ";
CM_ SG_ 890 VMC_EcasModeFB " ";
CM_ SG_ 890 VMC_EcasModeCHASts " ";
CM_ SG_ 890 VMC_CtrlLevelRR " ";
CM_ SG_ 890 VMC_CtrlLevelRL " ";
CM_ SG_ 890 VMC_CtrlLevelFR " ";
CM_ SG_ 890 VMC_CtrlLevelFL " ";
CM_ SG_ 890 VMC_EcasModeVal " ";
CM_ SG_ 890 VMC_EcdcMode " ";
BA_DEF_ SG_  "GenSigSendType" ENUM  "Cyclic","OnWrite","OnWriteWithRepetition","OnChange","OnChangeWithRepetition","IfActive","IfActiveWithRepetition","NoSigSendType","NotUsed","NotUsed","NotUsed","NotUsed","NotUsed";
BA_DEF_ SG_  "GenSigCycleTime" INT 0 0;
BA_DEF_ SG_  "GenSigInvalidValue" STRING ;
BA_DEF_ SG_  "GenSigStartValue" INT 0 0;
BA_DEF_ BO_  "VFrameFormat" ENUM  "StandardCAN","ExtendedCAN","reserved","reserved","reserved","reserved","reserved","reserved","reserved","reserved","reserved","reserved","reserved","reserved","StandardCAN_FD","ExtendedCAN_FD";
BA_DEF_ BO_  "CANFD_BRS" ENUM  "0","1";
BA_DEF_ BO_  "GenMsgCycleTime" INT 0 65535;
BA_DEF_ BO_  "GenMsgILSupport" ENUM  "No","Yes";
BA_DEF_ BO_  "GenMsgSendType" ENUM  "Cyclic","Event","NotUsed","NotUsed","NotUsed","Cyclic","NotUsed","IfActive","NoMsgSendType","NotUsed";
BA_DEF_ SG_  "SystemSignalLongSymbol" STRING ;
BA_DEF_DEF_  "GenSigSendType" "Cyclic";
BA_DEF_DEF_  "GenSigCycleTime" 0;
BA_DEF_DEF_  "GenSigInvalidValue" "/";
BA_DEF_DEF_  "GenSigStartValue" 0;
BA_DEF_DEF_  "VFrameFormat" "StandardCAN";
BA_DEF_DEF_  "CANFD_BRS" "1";
BA_DEF_DEF_  "GenMsgCycleTime" 0;
BA_DEF_DEF_  "GenMsgILSupport" "Yes";
BA_DEF_DEF_  "GenMsgSendType" "NoMsgSendType";
BA_DEF_DEF_  "SystemSignalLongSymbol" "";
BA_ "GenMsgCycleTime" BO_ 1321 100;
BA_ "GenMsgSendType" BO_ 1321 0;
BA_ "VFrameFormat" BO_ 1321 14;
BA_ "GenMsgCycleTime" BO_ 1323 100;
BA_ "GenMsgSendType" BO_ 1323 0;
BA_ "VFrameFormat" BO_ 1323 14;
BA_ "GenMsgCycleTime" BO_ 1329 100;
BA_ "GenMsgSendType" BO_ 1329 0;
BA_ "VFrameFormat" BO_ 1329 14;
BA_ "GenMsgCycleTime" BO_ 1330 100;
BA_ "GenMsgSendType" BO_ 1330 0;
BA_ "VFrameFormat" BO_ 1330 14;
BA_ "GenMsgCycleTime" BO_ 1331 100;
BA_ "GenMsgSendType" BO_ 1331 0;
BA_ "VFrameFormat" BO_ 1331 14;
BA_ "GenMsgCycleTime" BO_ 959 100;
BA_ "GenMsgSendType" BO_ 959 0;
BA_ "VFrameFormat" BO_ 959 14;
BA_ "GenMsgSendType" BO_ 429 1;
BA_ "VFrameFormat" BO_ 429 14;
BA_ "GenMsgSendType" BO_ 1517 1;
BA_ "VFrameFormat" BO_ 1517 14;
BA_ "GenMsgCycleTime" BO_ 1423 1000;
BA_ "GenMsgSendType" BO_ 1423 0;
BA_ "VFrameFormat" BO_ 1423 14;
BA_ "GenMsgCycleTime" BO_ 958 100;
BA_ "GenMsgSendType" BO_ 958 0;
BA_ "VFrameFormat" BO_ 958 14;
BA_ "GenMsgSendType" BO_ 1718 1;
BA_ "VFrameFormat" BO_ 1718 14;
BA_ "GenMsgCycleTime" BO_ 1430 1000;
BA_ "GenMsgSendType" BO_ 1430 0;
BA_ "VFrameFormat" BO_ 1430 14;
BA_ "GenMsgCycleTime" BO_ 1431 1000;
BA_ "GenMsgSendType" BO_ 1431 0;
BA_ "VFrameFormat" BO_ 1431 14;
BA_ "GenMsgCycleTime" BO_ 1432 1000;
BA_ "GenMsgSendType" BO_ 1432 0;
BA_ "VFrameFormat" BO_ 1432 14;
BA_ "GenMsgCycleTime" BO_ 1442 1000;
BA_ "GenMsgSendType" BO_ 1442 0;
BA_ "VFrameFormat" BO_ 1442 14;
BA_ "GenMsgCycleTime" BO_ 1687 500;
BA_ "GenMsgSendType" BO_ 1687 0;
BA_ "VFrameFormat" BO_ 1687 14;
BA_ "GenMsgCycleTime" BO_ 1755 500;
BA_ "GenMsgSendType" BO_ 1755 0;
BA_ "VFrameFormat" BO_ 1755 14;
BA_ "GenMsgCycleTime" BO_ 1763 500;
BA_ "GenMsgSendType" BO_ 1763 0;
BA_ "VFrameFormat" BO_ 1763 14;
BA_ "GenMsgCycleTime" BO_ 1776 500;
BA_ "GenMsgSendType" BO_ 1776 0;
BA_ "VFrameFormat" BO_ 1776 14;
BA_ "GenMsgSendType" BO_ 2015 1;
BA_ "VFrameFormat" BO_ 2015 14;
BA_ "GenMsgSendType" BO_ 1937 1;
BA_ "VFrameFormat" BO_ 1937 14;
BA_ "GenMsgSendType" BO_ 1945 1;
BA_ "VFrameFormat" BO_ 1945 14;
BA_ "GenMsgSendType" BO_ 1895 1;
BA_ "VFrameFormat" BO_ 1895 14;
BA_ "GenMsgSendType" BO_ 1903 1;
BA_ "VFrameFormat" BO_ 1903 14;
BA_ "GenMsgSendType" BO_ 1894 1;
BA_ "VFrameFormat" BO_ 1894 14;
BA_ "GenMsgSendType" BO_ 1902 1;
BA_ "VFrameFormat" BO_ 1902 14;
BA_ "GenMsgSendType" BO_ 1875 1;
BA_ "VFrameFormat" BO_ 1875 14;
BA_ "GenMsgSendType" BO_ 1883 1;
BA_ "VFrameFormat" BO_ 1883 14;
BA_ "GenMsgSendType" BO_ 1876 1;
BA_ "VFrameFormat" BO_ 1876 14;
BA_ "GenMsgSendType" BO_ 1884 1;
BA_ "VFrameFormat" BO_ 1884 14;
BA_ "GenMsgSendType" BO_ 1890 1;
BA_ "VFrameFormat" BO_ 1890 14;
BA_ "GenMsgSendType" BO_ 1898 1;
BA_ "VFrameFormat" BO_ 1898 14;
BA_ "GenMsgCycleTime" BO_ 953 100;
BA_ "GenMsgSendType" BO_ 953 0;
BA_ "VFrameFormat" BO_ 953 14;
BA_ "GenMsgCycleTime" BO_ 691 100;
BA_ "GenMsgSendType" BO_ 691 0;
BA_ "VFrameFormat" BO_ 691 14;
BA_ "GenMsgCycleTime" BO_ 989 100;
BA_ "GenMsgSendType" BO_ 989 0;
BA_ "VFrameFormat" BO_ 989 14;
BA_ "GenMsgCycleTime" BO_ 1018 100;
BA_ "GenMsgSendType" BO_ 1018 0;
BA_ "VFrameFormat" BO_ 1018 14;
BA_ "GenMsgCycleTime" BO_ 913 100;
BA_ "GenMsgSendType" BO_ 913 0;
BA_ "VFrameFormat" BO_ 913 14;
BA_ "GenMsgCycleTime" BO_ 573 100;
BA_ "GenMsgSendType" BO_ 573 0;
BA_ "VFrameFormat" BO_ 573 14;
BA_ "GenMsgCycleTime" BO_ 392 10;
BA_ "GenMsgSendType" BO_ 392 0;
BA_ "VFrameFormat" BO_ 392 14;
BA_ "GenMsgCycleTime" BO_ 632 20;
BA_ "GenMsgSendType" BO_ 632 0;
BA_ "VFrameFormat" BO_ 632 14;
BA_ "GenMsgCycleTime" BO_ 424 10;
BA_ "GenMsgSendType" BO_ 424 0;
BA_ "VFrameFormat" BO_ 424 14;
BA_ "GenMsgCycleTime" BO_ 588 20;
BA_ "GenMsgSendType" BO_ 588 0;
BA_ "VFrameFormat" BO_ 588 14;
BA_ "GenMsgCycleTime" BO_ 726 50;
BA_ "GenMsgSendType" BO_ 726 0;
BA_ "VFrameFormat" BO_ 726 14;
BA_ "GenMsgSendType" BO_ 1515 1;
BA_ "VFrameFormat" BO_ 1515 14;
BA_ "GenMsgCycleTime" BO_ 901 100;
BA_ "GenMsgSendType" BO_ 901 0;
BA_ "VFrameFormat" BO_ 901 14;
BA_ "GenMsgCycleTime" BO_ 890 100;
BA_ "GenMsgSendType" BO_ 890 0;
BA_ "VFrameFormat" BO_ 890 14;
BA_ "GenSigCycleTime" SG_ 1321 ACC_Target17BSDStatus 100;
BA_ "GenSigInvalidValue" SG_ 1321 ACC_Target17BSDStatus "3";
BA_ "GenSigCycleTime" SG_ 1321 ACC_Target16RightLightStatus 100;
BA_ "GenSigCycleTime" SG_ 1321 ACC_Target16LngRelSpeed 100;
BA_ "GenSigInvalidValue" SG_ 1321 ACC_Target16LngRelSpeed "511";
BA_ "GenSigStartValue" SG_ 1321 ACC_Target16LngRelSpeed 250;
BA_ "GenSigCycleTime" SG_ 1321 ACC_Target16LngRange 100;
BA_ "GenSigInvalidValue" SG_ 1321 ACC_Target16LngRange "4095";
BA_ "GenSigStartValue" SG_ 1321 ACC_Target16LngRange 1500;
BA_ "GenSigCycleTime" SG_ 1321 ACC_Target16LeftLightStatus 100;
BA_ "GenSigCycleTime" SG_ 1321 ACC_Target16LDC 100;
BA_ "GenSigCycleTime" SG_ 1321 ACC_Target16LatRelSpeed 100;
BA_ "GenSigInvalidValue" SG_ 1321 ACC_Target16LatRelSpeed "1024";
BA_ "GenSigStartValue" SG_ 1321 ACC_Target16LatRelSpeed 512;
BA_ "GenSigCycleTime" SG_ 1321 ACC_Target16LatRange 100;
BA_ "GenSigInvalidValue" SG_ 1321 ACC_Target16LatRange "1023";
BA_ "GenSigStartValue" SG_ 1321 ACC_Target16LatRange 500;
BA_ "GenSigCycleTime" SG_ 1321 ACC_Target16ID 100;
BA_ "GenSigCycleTime" SG_ 1321 ACC_Target16HeadingAngle 100;
BA_ "GenSigStartValue" SG_ 1321 ACC_Target16HeadingAngle 314;
BA_ "GenSigCycleTime" SG_ 1321 ACC_Target16Direction 100;
BA_ "GenSigStartValue" SG_ 1321 ACC_Target16Direction 5;
BA_ "GenSigCycleTime" SG_ 1321 ACC_Target16Detection 100;
BA_ "GenSigCycleTime" SG_ 1321 ACC_Target16BSDStatus 100;
BA_ "GenSigInvalidValue" SG_ 1321 ACC_Target16BSDStatus "3";
BA_ "GenSigCycleTime" SG_ 1321 ACC_Target16BrakeLightStatus 100;
BA_ "GenSigCycleTime" SG_ 1321 ACC_Target15ZoneID 100;
BA_ "GenSigCycleTime" SG_ 1321 ACC_Target15Type 100;
BA_ "GenSigCycleTime" SG_ 1321 ACC_Target15RightLightStatus 100;
BA_ "GenSigCycleTime" SG_ 1321 ACC_Target15LngRelSpeed 100;
BA_ "GenSigInvalidValue" SG_ 1321 ACC_Target15LngRelSpeed "511";
BA_ "GenSigStartValue" SG_ 1321 ACC_Target15LngRelSpeed 250;
BA_ "GenSigCycleTime" SG_ 1321 ACC_Target15LngRange 100;
BA_ "GenSigInvalidValue" SG_ 1321 ACC_Target15LngRange "4095";
BA_ "GenSigStartValue" SG_ 1321 ACC_Target15LngRange 1500;
BA_ "GenSigCycleTime" SG_ 1321 ACC_Target15LeftLightStatus 100;
BA_ "GenSigCycleTime" SG_ 1321 ACC_Target15LDC 100;
BA_ "GenSigCycleTime" SG_ 1321 ACC_Target15LatRelSpeed 100;
BA_ "GenSigInvalidValue" SG_ 1321 ACC_Target15LatRelSpeed "1024";
BA_ "GenSigStartValue" SG_ 1321 ACC_Target15LatRelSpeed 512;
BA_ "GenSigCycleTime" SG_ 1321 ACC_Target15LatRange 100;
BA_ "GenSigInvalidValue" SG_ 1321 ACC_Target15LatRange "1023";
BA_ "GenSigStartValue" SG_ 1321 ACC_Target15LatRange 500;
BA_ "GenSigCycleTime" SG_ 1321 ACC_Target15ID 100;
BA_ "GenSigCycleTime" SG_ 1321 ACC_Target15HeadingAngle 100;
BA_ "GenSigStartValue" SG_ 1321 ACC_Target15HeadingAngle 314;
BA_ "GenSigCycleTime" SG_ 1321 ACC_Target15Direction 100;
BA_ "GenSigStartValue" SG_ 1321 ACC_Target15Direction 5;
BA_ "GenSigCycleTime" SG_ 1321 ACC_Target15Detection 100;
BA_ "GenSigCycleTime" SG_ 1321 ACC_Target15BSDStatus 100;
BA_ "GenSigInvalidValue" SG_ 1321 ACC_Target15BSDStatus "3";
BA_ "GenSigCycleTime" SG_ 1321 ACC_Target14ZoneID 100;
BA_ "GenSigCycleTime" SG_ 1321 ACC_Target14Type 100;
BA_ "GenSigCycleTime" SG_ 1321 ACC_Target14LngRelSpeed 100;
BA_ "GenSigInvalidValue" SG_ 1321 ACC_Target14LngRelSpeed "511";
BA_ "GenSigStartValue" SG_ 1321 ACC_Target14LngRelSpeed 250;
BA_ "GenSigCycleTime" SG_ 1321 ACC_Target14LngRange 100;
BA_ "GenSigInvalidValue" SG_ 1321 ACC_Target14LngRange "4095";
BA_ "GenSigStartValue" SG_ 1321 ACC_Target14LngRange 1500;
BA_ "GenSigCycleTime" SG_ 1321 ACC_Target14LeftLightStatus 100;
BA_ "GenSigCycleTime" SG_ 1321 ACC_Target14LDC 100;
BA_ "GenSigCycleTime" SG_ 1321 ACC_Target14LatRelSpeed 100;
BA_ "GenSigInvalidValue" SG_ 1321 ACC_Target14LatRelSpeed "1024";
BA_ "GenSigStartValue" SG_ 1321 ACC_Target14LatRelSpeed 512;
BA_ "GenSigCycleTime" SG_ 1321 ACC_Target14LatRange 100;
BA_ "GenSigInvalidValue" SG_ 1321 ACC_Target14LatRange "1023";
BA_ "GenSigStartValue" SG_ 1321 ACC_Target14LatRange 500;
BA_ "GenSigCycleTime" SG_ 1321 ACC_Target14ID 100;
BA_ "GenSigCycleTime" SG_ 1321 ACC_Target14HeadingAngle 100;
BA_ "GenSigStartValue" SG_ 1321 ACC_Target14HeadingAngle 314;
BA_ "GenSigCycleTime" SG_ 1321 ACC_Target14Direction 100;
BA_ "GenSigStartValue" SG_ 1321 ACC_Target14Direction 5;
BA_ "GenSigCycleTime" SG_ 1321 ACC_Target14Detection 100;
BA_ "GenSigCycleTime" SG_ 1321 ACC_Target14BSDStatus 100;
BA_ "GenSigInvalidValue" SG_ 1321 ACC_Target14BSDStatus "3";
BA_ "GenSigCycleTime" SG_ 1321 ACC_Target14BrakeLightStatus 100;
BA_ "GenSigCycleTime" SG_ 1321 ACC_Target13ZoneID 100;
BA_ "GenSigCycleTime" SG_ 1321 ACC_Target13Type 100;
BA_ "GenSigCycleTime" SG_ 1321 ACC_Target13RightLightStatus 100;
BA_ "GenSigCycleTime" SG_ 1321 ACC_Target13LngRelSpeed 100;
BA_ "GenSigInvalidValue" SG_ 1321 ACC_Target13LngRelSpeed "511";
BA_ "GenSigStartValue" SG_ 1321 ACC_Target13LngRelSpeed 250;
BA_ "GenSigCycleTime" SG_ 1321 ACC_Target13LngRange 100;
BA_ "GenSigInvalidValue" SG_ 1321 ACC_Target13LngRange "4095";
BA_ "GenSigStartValue" SG_ 1321 ACC_Target13LngRange 1500;
BA_ "GenSigCycleTime" SG_ 1321 ACC_Target13LeftLightStatus 100;
BA_ "GenSigCycleTime" SG_ 1321 ACC_Target13LDC 100;
BA_ "GenSigCycleTime" SG_ 1321 ACC_Target13LatRelSpeed 100;
BA_ "GenSigInvalidValue" SG_ 1321 ACC_Target13LatRelSpeed "1024";
BA_ "GenSigStartValue" SG_ 1321 ACC_Target13LatRelSpeed 512;
BA_ "GenSigCycleTime" SG_ 1321 ACC_Target13LatRange 100;
BA_ "GenSigInvalidValue" SG_ 1321 ACC_Target13LatRange "1023";
BA_ "GenSigStartValue" SG_ 1321 ACC_Target13LatRange 500;
BA_ "GenSigCycleTime" SG_ 1321 ACC_Target13ID 100;
BA_ "GenSigCycleTime" SG_ 1321 ACC_Target13HeadingAngle 100;
BA_ "GenSigStartValue" SG_ 1321 ACC_Target13HeadingAngle 314;
BA_ "GenSigCycleTime" SG_ 1321 ACC_Target13Direction 100;
BA_ "GenSigStartValue" SG_ 1321 ACC_Target13Direction 5;
BA_ "GenSigCycleTime" SG_ 1321 ACC_Target13Detection 100;
BA_ "GenSigCycleTime" SG_ 1321 ACC_Target13BSDStatus 100;
BA_ "GenSigInvalidValue" SG_ 1321 ACC_Target13BSDStatus "3";
BA_ "GenSigCycleTime" SG_ 1321 ACC_Target13BrakeLightStatus 100;
BA_ "GenSigCycleTime" SG_ 1321 ACC_Target12ZoneID 100;
BA_ "GenSigCycleTime" SG_ 1321 ACC_Target12Type 100;
BA_ "GenSigCycleTime" SG_ 1321 ACC_Target12RightLightStatus 100;
BA_ "GenSigCycleTime" SG_ 1321 ACC_Target12LngRelSpeed 100;
BA_ "GenSigInvalidValue" SG_ 1321 ACC_Target12LngRelSpeed "511";
BA_ "GenSigStartValue" SG_ 1321 ACC_Target12LngRelSpeed 250;
BA_ "GenSigCycleTime" SG_ 1321 ACC_Target12LngRange 100;
BA_ "GenSigInvalidValue" SG_ 1321 ACC_Target12LngRange "4095";
BA_ "GenSigStartValue" SG_ 1321 ACC_Target12LngRange 1500;
BA_ "GenSigCycleTime" SG_ 1321 ACC_Target12LeftLightStatus 100;
BA_ "GenSigCycleTime" SG_ 1321 ACC_Target12LDC 100;
BA_ "GenSigCycleTime" SG_ 1321 ACC_Target12LatRelSpeed 100;
BA_ "GenSigInvalidValue" SG_ 1321 ACC_Target12LatRelSpeed "1024";
BA_ "GenSigStartValue" SG_ 1321 ACC_Target12LatRelSpeed 512;
BA_ "GenSigCycleTime" SG_ 1321 ACC_Target12LatRange 100;
BA_ "GenSigInvalidValue" SG_ 1321 ACC_Target12LatRange "1023";
BA_ "GenSigStartValue" SG_ 1321 ACC_Target12LatRange 500;
BA_ "GenSigCycleTime" SG_ 1321 ACC_Target12ID 100;
BA_ "GenSigCycleTime" SG_ 1321 ACC_Target12HeadingAngle 100;
BA_ "GenSigStartValue" SG_ 1321 ACC_Target12HeadingAngle 314;
BA_ "GenSigCycleTime" SG_ 1321 ACC_Target12Direction 100;
BA_ "GenSigStartValue" SG_ 1321 ACC_Target12Direction 5;
BA_ "GenSigCycleTime" SG_ 1321 ACC_Target12Detection 100;
BA_ "GenSigCycleTime" SG_ 1321 ACC_Target12BSDStatus 100;
BA_ "GenSigInvalidValue" SG_ 1321 ACC_Target12BSDStatus "3";
BA_ "GenSigCycleTime" SG_ 1321 ACC_Target12BrakeLightStatus 100;
BA_ "GenSigCycleTime" SG_ 1321 ACC_Target11ZoneID 100;
BA_ "GenSigCycleTime" SG_ 1321 ACC_Target11RightLightStatus 100;
BA_ "GenSigCycleTime" SG_ 1321 ACC_Target11LngRelSpeed 100;
BA_ "GenSigInvalidValue" SG_ 1321 ACC_Target11LngRelSpeed "511";
BA_ "GenSigStartValue" SG_ 1321 ACC_Target11LngRelSpeed 250;
BA_ "GenSigCycleTime" SG_ 1321 ACC_Target11LngRange 100;
BA_ "GenSigInvalidValue" SG_ 1321 ACC_Target11LngRange "4095";
BA_ "GenSigStartValue" SG_ 1321 ACC_Target11LngRange 1500;
BA_ "GenSigCycleTime" SG_ 1323 ACC_Target22BSDStatus 100;
BA_ "GenSigInvalidValue" SG_ 1323 ACC_Target22BSDStatus "3";
BA_ "GenSigCycleTime" SG_ 1323 ACC_Target21RightLightStatus 100;
BA_ "GenSigCycleTime" SG_ 1323 ACC_Target21LngRange 100;
BA_ "GenSigInvalidValue" SG_ 1323 ACC_Target21LngRange "4095";
BA_ "GenSigStartValue" SG_ 1323 ACC_Target21LngRange 1500;
BA_ "GenSigCycleTime" SG_ 1323 ACC_Target21LeftLightStatus 100;
BA_ "GenSigCycleTime" SG_ 1323 ACC_Target21LDC 100;
BA_ "GenSigCycleTime" SG_ 1323 ACC_Target21LatRelSpeed 100;
BA_ "GenSigInvalidValue" SG_ 1323 ACC_Target21LatRelSpeed "1024";
BA_ "GenSigStartValue" SG_ 1323 ACC_Target21LatRelSpeed 512;
BA_ "GenSigCycleTime" SG_ 1323 ACC_Target21LatRange 100;
BA_ "GenSigInvalidValue" SG_ 1323 ACC_Target21LatRange "1023";
BA_ "GenSigStartValue" SG_ 1323 ACC_Target21LatRange 500;
BA_ "GenSigCycleTime" SG_ 1323 ACC_Target21HeadingAngle 100;
BA_ "GenSigStartValue" SG_ 1323 ACC_Target21HeadingAngle 314;
BA_ "GenSigCycleTime" SG_ 1323 ACC_Target21Direction 100;
BA_ "GenSigStartValue" SG_ 1323 ACC_Target21Direction 5;
BA_ "GenSigCycleTime" SG_ 1323 ACC_Target21Detection 100;
BA_ "GenSigCycleTime" SG_ 1323 ACC_Target21BSDStatus 100;
BA_ "GenSigInvalidValue" SG_ 1323 ACC_Target21BSDStatus "3";
BA_ "GenSigCycleTime" SG_ 1323 ACC_Target21BrakeLightStatus 100;
BA_ "GenSigCycleTime" SG_ 1323 ACC_Target20ZoneID 100;
BA_ "GenSigCycleTime" SG_ 1323 ACC_Target20Type 100;
BA_ "GenSigCycleTime" SG_ 1323 ACC_Target20RightLightStatus 100;
BA_ "GenSigCycleTime" SG_ 1323 ACC_Target20LngRelSpeed 100;
BA_ "GenSigInvalidValue" SG_ 1323 ACC_Target20LngRelSpeed "511";
BA_ "GenSigStartValue" SG_ 1323 ACC_Target20LngRelSpeed 250;
BA_ "GenSigCycleTime" SG_ 1323 ACC_Target20LngRange 100;
BA_ "GenSigInvalidValue" SG_ 1323 ACC_Target20LngRange "4095";
BA_ "GenSigStartValue" SG_ 1323 ACC_Target20LngRange 1500;
BA_ "GenSigCycleTime" SG_ 1323 ACC_Target20LeftLightStatus 100;
BA_ "GenSigCycleTime" SG_ 1323 ACC_Target20LDC 100;
BA_ "GenSigCycleTime" SG_ 1323 ACC_Target20LatRelSpeed 100;
BA_ "GenSigInvalidValue" SG_ 1323 ACC_Target20LatRelSpeed "1024";
BA_ "GenSigStartValue" SG_ 1323 ACC_Target20LatRelSpeed 512;
BA_ "GenSigCycleTime" SG_ 1323 ACC_Target20LatRange 100;
BA_ "GenSigInvalidValue" SG_ 1323 ACC_Target20LatRange "1023";
BA_ "GenSigStartValue" SG_ 1323 ACC_Target20LatRange 500;
BA_ "GenSigCycleTime" SG_ 1323 ACC_Target20ID 100;
BA_ "GenSigCycleTime" SG_ 1323 ACC_Target20HeadingAngle 100;
BA_ "GenSigStartValue" SG_ 1323 ACC_Target20HeadingAngle 314;
BA_ "GenSigCycleTime" SG_ 1323 ACC_Target20Direction 100;
BA_ "GenSigStartValue" SG_ 1323 ACC_Target20Direction 5;
BA_ "GenSigCycleTime" SG_ 1323 ACC_Target20Detection 100;
BA_ "GenSigCycleTime" SG_ 1323 ACC_Target20BSDStatus 100;
BA_ "GenSigInvalidValue" SG_ 1323 ACC_Target20BSDStatus "3";
BA_ "GenSigCycleTime" SG_ 1323 ACC_Target20BrakeLightStatus 100;
BA_ "GenSigCycleTime" SG_ 1323 ACC_Target1RightLightStatus 100;
BA_ "GenSigCycleTime" SG_ 1323 ACC_Target1LngRelSpeed 100;
BA_ "GenSigInvalidValue" SG_ 1323 ACC_Target1LngRelSpeed "511";
BA_ "GenSigStartValue" SG_ 1323 ACC_Target1LngRelSpeed 250;
BA_ "GenSigCycleTime" SG_ 1323 ACC_Target1LeftLightStatus 100;
BA_ "GenSigCycleTime" SG_ 1323 ACC_Target1LDC 100;
BA_ "GenSigCycleTime" SG_ 1323 ACC_Target1LatRelSpeed 100;
BA_ "GenSigInvalidValue" SG_ 1323 ACC_Target1LatRelSpeed "1024";
BA_ "GenSigStartValue" SG_ 1323 ACC_Target1LatRelSpeed 512;
BA_ "GenSigCycleTime" SG_ 1323 ACC_Target1BSDStatus 100;
BA_ "GenSigInvalidValue" SG_ 1323 ACC_Target1BSDStatus "3";
BA_ "GenSigCycleTime" SG_ 1323 ACC_Target1BrakeLightStatus 100;
BA_ "GenSigCycleTime" SG_ 1323 ACC_Target19ZoneID 100;
BA_ "GenSigCycleTime" SG_ 1323 ACC_Target19Type 100;
BA_ "GenSigCycleTime" SG_ 1323 ACC_Target19RightLightStatus 100;
BA_ "GenSigCycleTime" SG_ 1323 ACC_Target19LngRelSpeed 100;
BA_ "GenSigInvalidValue" SG_ 1323 ACC_Target19LngRelSpeed "511";
BA_ "GenSigStartValue" SG_ 1323 ACC_Target19LngRelSpeed 250;
BA_ "GenSigCycleTime" SG_ 1323 ACC_Target19LngRange 100;
BA_ "GenSigInvalidValue" SG_ 1323 ACC_Target19LngRange "4095";
BA_ "GenSigStartValue" SG_ 1323 ACC_Target19LngRange 1500;
BA_ "GenSigCycleTime" SG_ 1323 ACC_Target19LeftLightStatus 100;
BA_ "GenSigCycleTime" SG_ 1323 ACC_Target19LDC 100;
BA_ "GenSigCycleTime" SG_ 1323 ACC_Target19LatRelSpeed 100;
BA_ "GenSigInvalidValue" SG_ 1323 ACC_Target19LatRelSpeed "1024";
BA_ "GenSigStartValue" SG_ 1323 ACC_Target19LatRelSpeed 512;
BA_ "GenSigCycleTime" SG_ 1323 ACC_Target19LatRange 100;
BA_ "GenSigInvalidValue" SG_ 1323 ACC_Target19LatRange "1023";
BA_ "GenSigStartValue" SG_ 1323 ACC_Target19LatRange 500;
BA_ "GenSigCycleTime" SG_ 1323 ACC_Target19ID 100;
BA_ "GenSigCycleTime" SG_ 1323 ACC_Target19HeadingAngle 100;
BA_ "GenSigStartValue" SG_ 1323 ACC_Target19HeadingAngle 314;
BA_ "GenSigCycleTime" SG_ 1323 ACC_Target19Direction 100;
BA_ "GenSigStartValue" SG_ 1323 ACC_Target19Direction 5;
BA_ "GenSigCycleTime" SG_ 1323 ACC_Target19Detection 100;
BA_ "GenSigCycleTime" SG_ 1323 ACC_Target19BSDStatus 100;
BA_ "GenSigInvalidValue" SG_ 1323 ACC_Target19BSDStatus "3";
BA_ "GenSigCycleTime" SG_ 1323 ACC_Target19BrakeLightStatus 100;
BA_ "GenSigCycleTime" SG_ 1323 ACC_Target18ZoneID 100;
BA_ "GenSigCycleTime" SG_ 1323 ACC_Target18Type 100;
BA_ "GenSigCycleTime" SG_ 1323 ACC_Target18RightLightStatus 100;
BA_ "GenSigCycleTime" SG_ 1323 ACC_Target18LngRelSpeed 100;
BA_ "GenSigInvalidValue" SG_ 1323 ACC_Target18LngRelSpeed "511";
BA_ "GenSigStartValue" SG_ 1323 ACC_Target18LngRelSpeed 250;
BA_ "GenSigCycleTime" SG_ 1323 ACC_Target18LngRange 100;
BA_ "GenSigInvalidValue" SG_ 1323 ACC_Target18LngRange "4095";
BA_ "GenSigStartValue" SG_ 1323 ACC_Target18LngRange 1500;
BA_ "GenSigCycleTime" SG_ 1323 ACC_Target18LeftLightStatus 100;
BA_ "GenSigCycleTime" SG_ 1323 ACC_Target18LDC 100;
BA_ "GenSigCycleTime" SG_ 1323 ACC_Target18LatRelSpeed 100;
BA_ "GenSigInvalidValue" SG_ 1323 ACC_Target18LatRelSpeed "1024";
BA_ "GenSigStartValue" SG_ 1323 ACC_Target18LatRelSpeed 512;
BA_ "GenSigCycleTime" SG_ 1323 ACC_Target18LatRange 100;
BA_ "GenSigInvalidValue" SG_ 1323 ACC_Target18LatRange "1023";
BA_ "GenSigStartValue" SG_ 1323 ACC_Target18LatRange 500;
BA_ "GenSigCycleTime" SG_ 1323 ACC_Target18ID 100;
BA_ "GenSigCycleTime" SG_ 1323 ACC_Target18HeadingAngle 100;
BA_ "GenSigStartValue" SG_ 1323 ACC_Target18HeadingAngle 314;
BA_ "GenSigCycleTime" SG_ 1323 ACC_Target18Direction 100;
BA_ "GenSigStartValue" SG_ 1323 ACC_Target18Direction 5;
BA_ "GenSigCycleTime" SG_ 1323 ACC_Target18Detection 100;
BA_ "GenSigCycleTime" SG_ 1323 ACC_Target18BSDStatus 100;
BA_ "GenSigInvalidValue" SG_ 1323 ACC_Target18BSDStatus "3";
BA_ "GenSigCycleTime" SG_ 1323 ACC_Target18BrakeLightStatus 100;
BA_ "GenSigCycleTime" SG_ 1323 ACC_Target17ZoneID 100;
BA_ "GenSigCycleTime" SG_ 1323 ACC_Target17Type 100;
BA_ "GenSigCycleTime" SG_ 1323 ACC_Target17RightLightStatus 100;
BA_ "GenSigCycleTime" SG_ 1323 ACC_Target17LngRelSpeed 100;
BA_ "GenSigInvalidValue" SG_ 1323 ACC_Target17LngRelSpeed "511";
BA_ "GenSigStartValue" SG_ 1323 ACC_Target17LngRelSpeed 250;
BA_ "GenSigCycleTime" SG_ 1323 ACC_Target17LngRange 100;
BA_ "GenSigInvalidValue" SG_ 1323 ACC_Target17LngRange "4095";
BA_ "GenSigStartValue" SG_ 1323 ACC_Target17LngRange 1500;
BA_ "GenSigCycleTime" SG_ 1323 ACC_Target17LeftLightStatus 100;
BA_ "GenSigCycleTime" SG_ 1323 ACC_Target17LDC 100;
BA_ "GenSigCycleTime" SG_ 1323 ACC_Target17LatRelSpeed 100;
BA_ "GenSigInvalidValue" SG_ 1323 ACC_Target17LatRelSpeed "1024";
BA_ "GenSigStartValue" SG_ 1323 ACC_Target17LatRelSpeed 512;
BA_ "GenSigCycleTime" SG_ 1323 ACC_Target17LatRange 100;
BA_ "GenSigInvalidValue" SG_ 1323 ACC_Target17LatRange "1023";
BA_ "GenSigStartValue" SG_ 1323 ACC_Target17LatRange 500;
BA_ "GenSigCycleTime" SG_ 1323 ACC_Target17ID 100;
BA_ "GenSigCycleTime" SG_ 1323 ACC_Target17HeadingAngle 100;
BA_ "GenSigStartValue" SG_ 1323 ACC_Target17HeadingAngle 314;
BA_ "GenSigCycleTime" SG_ 1323 ACC_Target17Direction 100;
BA_ "GenSigStartValue" SG_ 1323 ACC_Target17Direction 5;
BA_ "GenSigCycleTime" SG_ 1323 ACC_Target17Detection 100;
BA_ "GenSigCycleTime" SG_ 1323 ACC_Target17BrakeLightStatus 100;
BA_ "GenSigCycleTime" SG_ 1323 ACC_Target16ZoneID 100;
BA_ "GenSigCycleTime" SG_ 1323 ACC_Target16Type 100;
BA_ "GenSigCycleTime" SG_ 1329 ACC_Target27BrakeLightStatus 100;
BA_ "GenSigCycleTime" SG_ 1329 ACC_Target26ZoneID 100;
BA_ "GenSigCycleTime" SG_ 1329 ACC_Target26RightLightStatus 100;
BA_ "GenSigCycleTime" SG_ 1329 ACC_Target26LngRange 100;
BA_ "GenSigInvalidValue" SG_ 1329 ACC_Target26LngRange "4095";
BA_ "GenSigStartValue" SG_ 1329 ACC_Target26LngRange 1500;
BA_ "GenSigCycleTime" SG_ 1329 ACC_Target26LeftLightStatus 100;
BA_ "GenSigCycleTime" SG_ 1329 ACC_Target26LDC 100;
BA_ "GenSigCycleTime" SG_ 1329 ACC_Target26LatRelSpeed 100;
BA_ "GenSigInvalidValue" SG_ 1329 ACC_Target26LatRelSpeed "1024";
BA_ "GenSigStartValue" SG_ 1329 ACC_Target26LatRelSpeed 512;
BA_ "GenSigCycleTime" SG_ 1329 ACC_Target26LatRange 100;
BA_ "GenSigInvalidValue" SG_ 1329 ACC_Target26LatRange "1023";
BA_ "GenSigStartValue" SG_ 1329 ACC_Target26LatRange 500;
BA_ "GenSigCycleTime" SG_ 1329 ACC_Target26ID 100;
BA_ "GenSigCycleTime" SG_ 1329 ACC_Target26HeadingAngle 100;
BA_ "GenSigStartValue" SG_ 1329 ACC_Target26HeadingAngle 314;
BA_ "GenSigCycleTime" SG_ 1329 ACC_Target26Direction 100;
BA_ "GenSigStartValue" SG_ 1329 ACC_Target26Direction 5;
BA_ "GenSigCycleTime" SG_ 1329 ACC_Target26Detection 100;
BA_ "GenSigCycleTime" SG_ 1329 ACC_Target26BSDStatus 100;
BA_ "GenSigInvalidValue" SG_ 1329 ACC_Target26BSDStatus "3";
BA_ "GenSigCycleTime" SG_ 1329 ACC_Target26BrakeLightStatus 100;
BA_ "GenSigCycleTime" SG_ 1329 ACC_Target25ZoneID 100;
BA_ "GenSigCycleTime" SG_ 1329 ACC_Target25Type 100;
BA_ "GenSigCycleTime" SG_ 1329 ACC_Target25RightLightStatus 100;
BA_ "GenSigCycleTime" SG_ 1329 ACC_Target25LngRelSpeed 100;
BA_ "GenSigInvalidValue" SG_ 1329 ACC_Target25LngRelSpeed "511";
BA_ "GenSigStartValue" SG_ 1329 ACC_Target25LngRelSpeed 250;
BA_ "GenSigCycleTime" SG_ 1329 ACC_Target25LngRange 100;
BA_ "GenSigInvalidValue" SG_ 1329 ACC_Target25LngRange "4095";
BA_ "GenSigStartValue" SG_ 1329 ACC_Target25LngRange 1500;
BA_ "GenSigCycleTime" SG_ 1329 ACC_Target25LeftLightStatus 100;
BA_ "GenSigCycleTime" SG_ 1329 ACC_Target25LDC 100;
BA_ "GenSigCycleTime" SG_ 1329 ACC_Target25LatRelSpeed 100;
BA_ "GenSigInvalidValue" SG_ 1329 ACC_Target25LatRelSpeed "1024";
BA_ "GenSigStartValue" SG_ 1329 ACC_Target25LatRelSpeed 512;
BA_ "GenSigCycleTime" SG_ 1329 ACC_Target25LatRange 100;
BA_ "GenSigInvalidValue" SG_ 1329 ACC_Target25LatRange "1023";
BA_ "GenSigStartValue" SG_ 1329 ACC_Target25LatRange 500;
BA_ "GenSigCycleTime" SG_ 1329 ACC_Target25ID 100;
BA_ "GenSigCycleTime" SG_ 1329 ACC_Target25HeadingAngle 100;
BA_ "GenSigStartValue" SG_ 1329 ACC_Target25HeadingAngle 314;
BA_ "GenSigCycleTime" SG_ 1329 ACC_Target25Direction 100;
BA_ "GenSigStartValue" SG_ 1329 ACC_Target25Direction 5;
BA_ "GenSigCycleTime" SG_ 1329 ACC_Target25Detection 100;
BA_ "GenSigCycleTime" SG_ 1329 ACC_Target25BSDStatus 100;
BA_ "GenSigInvalidValue" SG_ 1329 ACC_Target25BSDStatus "3";
BA_ "GenSigCycleTime" SG_ 1329 ACC_Target25BrakeLightStatus 100;
BA_ "GenSigCycleTime" SG_ 1329 ACC_Target24ZoneID 100;
BA_ "GenSigCycleTime" SG_ 1329 ACC_Target24Type 100;
BA_ "GenSigCycleTime" SG_ 1329 ACC_Target24RightLightStatus 100;
BA_ "GenSigCycleTime" SG_ 1329 ACC_Target24LngRelSpeed 100;
BA_ "GenSigInvalidValue" SG_ 1329 ACC_Target24LngRelSpeed "511";
BA_ "GenSigStartValue" SG_ 1329 ACC_Target24LngRelSpeed 250;
BA_ "GenSigCycleTime" SG_ 1329 ACC_Target24LngRange 100;
BA_ "GenSigInvalidValue" SG_ 1329 ACC_Target24LngRange "4095";
BA_ "GenSigStartValue" SG_ 1329 ACC_Target24LngRange 1500;
BA_ "GenSigCycleTime" SG_ 1329 ACC_Target24LeftLightStatus 100;
BA_ "GenSigCycleTime" SG_ 1329 ACC_Target24LDC 100;
BA_ "GenSigCycleTime" SG_ 1329 ACC_Target24LatRelSpeed 100;
BA_ "GenSigInvalidValue" SG_ 1329 ACC_Target24LatRelSpeed "1024";
BA_ "GenSigStartValue" SG_ 1329 ACC_Target24LatRelSpeed 512;
BA_ "GenSigCycleTime" SG_ 1329 ACC_Target24LatRange 100;
BA_ "GenSigInvalidValue" SG_ 1329 ACC_Target24LatRange "1023";
BA_ "GenSigStartValue" SG_ 1329 ACC_Target24LatRange 500;
BA_ "GenSigCycleTime" SG_ 1329 ACC_Target24ID 100;
BA_ "GenSigCycleTime" SG_ 1329 ACC_Target24HeadingAngle 100;
BA_ "GenSigStartValue" SG_ 1329 ACC_Target24HeadingAngle 314;
BA_ "GenSigCycleTime" SG_ 1329 ACC_Target24Direction 100;
BA_ "GenSigStartValue" SG_ 1329 ACC_Target24Direction 5;
BA_ "GenSigCycleTime" SG_ 1329 ACC_Target24Detection 100;
BA_ "GenSigCycleTime" SG_ 1329 ACC_Target24BSDStatus 100;
BA_ "GenSigInvalidValue" SG_ 1329 ACC_Target24BSDStatus "3";
BA_ "GenSigCycleTime" SG_ 1329 ACC_Target24BrakeLightStatus 100;
BA_ "GenSigCycleTime" SG_ 1329 ACC_Target23ZoneID 100;
BA_ "GenSigCycleTime" SG_ 1329 ACC_Target23Type 100;
BA_ "GenSigCycleTime" SG_ 1329 ACC_Target23RightLightStatus 100;
BA_ "GenSigCycleTime" SG_ 1329 ACC_Target23LngRelSpeed 100;
BA_ "GenSigInvalidValue" SG_ 1329 ACC_Target23LngRelSpeed "511";
BA_ "GenSigStartValue" SG_ 1329 ACC_Target23LngRelSpeed 250;
BA_ "GenSigCycleTime" SG_ 1329 ACC_Target23LngRange 100;
BA_ "GenSigInvalidValue" SG_ 1329 ACC_Target23LngRange "4095";
BA_ "GenSigStartValue" SG_ 1329 ACC_Target23LngRange 1500;
BA_ "GenSigCycleTime" SG_ 1329 ACC_Target23LeftLightStatus 100;
BA_ "GenSigCycleTime" SG_ 1329 ACC_Target23LDC 100;
BA_ "GenSigCycleTime" SG_ 1329 ACC_Target23LatRelSpeed 100;
BA_ "GenSigInvalidValue" SG_ 1329 ACC_Target23LatRelSpeed "1024";
BA_ "GenSigStartValue" SG_ 1329 ACC_Target23LatRelSpeed 512;
BA_ "GenSigCycleTime" SG_ 1329 ACC_Target23LatRange 100;
BA_ "GenSigInvalidValue" SG_ 1329 ACC_Target23LatRange "1023";
BA_ "GenSigStartValue" SG_ 1329 ACC_Target23LatRange 500;
BA_ "GenSigCycleTime" SG_ 1329 ACC_Target23ID 100;
BA_ "GenSigCycleTime" SG_ 1329 ACC_Target23HeadingAngle 100;
BA_ "GenSigStartValue" SG_ 1329 ACC_Target23HeadingAngle 314;
BA_ "GenSigCycleTime" SG_ 1329 ACC_Target23Direction 100;
BA_ "GenSigStartValue" SG_ 1329 ACC_Target23Direction 5;
BA_ "GenSigCycleTime" SG_ 1329 ACC_Target23Detection 100;
BA_ "GenSigCycleTime" SG_ 1329 ACC_Target23BSDStatus 100;
BA_ "GenSigInvalidValue" SG_ 1329 ACC_Target23BSDStatus "3";
BA_ "GenSigCycleTime" SG_ 1329 ACC_Target23BrakeLightStatus 100;
BA_ "GenSigCycleTime" SG_ 1329 ACC_Target22ZoneID 100;
BA_ "GenSigCycleTime" SG_ 1329 ACC_Target22Type 100;
BA_ "GenSigCycleTime" SG_ 1329 ACC_Target22RightLightStatus 100;
BA_ "GenSigCycleTime" SG_ 1329 ACC_Target22LngRelSpeed 100;
BA_ "GenSigInvalidValue" SG_ 1329 ACC_Target22LngRelSpeed "511";
BA_ "GenSigStartValue" SG_ 1329 ACC_Target22LngRelSpeed 250;
BA_ "GenSigCycleTime" SG_ 1329 ACC_Target22LngRange 100;
BA_ "GenSigInvalidValue" SG_ 1329 ACC_Target22LngRange "4095";
BA_ "GenSigStartValue" SG_ 1329 ACC_Target22LngRange 1500;
BA_ "GenSigCycleTime" SG_ 1329 ACC_Target22LeftLightStatus 100;
BA_ "GenSigCycleTime" SG_ 1329 ACC_Target22LDC 100;
BA_ "GenSigCycleTime" SG_ 1329 ACC_Target22LatRelSpeed 100;
BA_ "GenSigInvalidValue" SG_ 1329 ACC_Target22LatRelSpeed "1024";
BA_ "GenSigStartValue" SG_ 1329 ACC_Target22LatRelSpeed 512;
BA_ "GenSigCycleTime" SG_ 1329 ACC_Target22LatRange 100;
BA_ "GenSigInvalidValue" SG_ 1329 ACC_Target22LatRange "1023";
BA_ "GenSigStartValue" SG_ 1329 ACC_Target22LatRange 500;
BA_ "GenSigCycleTime" SG_ 1329 ACC_Target22ID 100;
BA_ "GenSigCycleTime" SG_ 1329 ACC_Target22HeadingAngle 100;
BA_ "GenSigStartValue" SG_ 1329 ACC_Target22HeadingAngle 314;
BA_ "GenSigCycleTime" SG_ 1329 ACC_Target22Direction 100;
BA_ "GenSigStartValue" SG_ 1329 ACC_Target22Direction 5;
BA_ "GenSigCycleTime" SG_ 1329 ACC_Target22Detection 100;
BA_ "GenSigCycleTime" SG_ 1329 ACC_Target22BrakeLightStatus 100;
BA_ "GenSigCycleTime" SG_ 1329 ACC_Target21ZoneID 100;
BA_ "GenSigCycleTime" SG_ 1329 ACC_Target21Type 100;
BA_ "GenSigCycleTime" SG_ 1329 ACC_Target21LngRelSpeed 100;
BA_ "GenSigInvalidValue" SG_ 1329 ACC_Target21LngRelSpeed "511";
BA_ "GenSigStartValue" SG_ 1329 ACC_Target21LngRelSpeed 250;
BA_ "GenSigCycleTime" SG_ 1329 ACC_Target21ID 100;
BA_ "GenSigCycleTime" SG_ 1330 ACC_Target31LngRange 100;
BA_ "GenSigInvalidValue" SG_ 1330 ACC_Target31LngRange "4095";
BA_ "GenSigStartValue" SG_ 1330 ACC_Target31LngRange 1500;
BA_ "GenSigCycleTime" SG_ 1330 ACC_Target31LeftLightStatus 100;
BA_ "GenSigCycleTime" SG_ 1330 ACC_Target31LDC 100;
BA_ "GenSigCycleTime" SG_ 1330 ACC_Target31LatRelSpeed 100;
BA_ "GenSigInvalidValue" SG_ 1330 ACC_Target31LatRelSpeed "1024";
BA_ "GenSigStartValue" SG_ 1330 ACC_Target31LatRelSpeed 512;
BA_ "GenSigCycleTime" SG_ 1330 ACC_Target31LatRange 100;
BA_ "GenSigInvalidValue" SG_ 1330 ACC_Target31LatRange "1023";
BA_ "GenSigStartValue" SG_ 1330 ACC_Target31LatRange 500;
BA_ "GenSigCycleTime" SG_ 1330 ACC_Target31ID 100;
BA_ "GenSigCycleTime" SG_ 1330 ACC_Target31HeadingAngle 100;
BA_ "GenSigStartValue" SG_ 1330 ACC_Target31HeadingAngle 314;
BA_ "GenSigCycleTime" SG_ 1330 ACC_Target31Direction 100;
BA_ "GenSigStartValue" SG_ 1330 ACC_Target31Direction 5;
BA_ "GenSigCycleTime" SG_ 1330 ACC_Target31Detection 100;
BA_ "GenSigCycleTime" SG_ 1330 ACC_Target31BSDStatus 100;
BA_ "GenSigInvalidValue" SG_ 1330 ACC_Target31BSDStatus "3";
BA_ "GenSigCycleTime" SG_ 1330 ACC_Target31BrakeLightStatus 100;
BA_ "GenSigCycleTime" SG_ 1330 ACC_Target30ZoneID 100;
BA_ "GenSigCycleTime" SG_ 1330 ACC_Target30Type 100;
BA_ "GenSigCycleTime" SG_ 1330 ACC_Target30RightLightStatus 100;
BA_ "GenSigCycleTime" SG_ 1330 ACC_Target30LngRelSpeed 100;
BA_ "GenSigInvalidValue" SG_ 1330 ACC_Target30LngRelSpeed "511";
BA_ "GenSigStartValue" SG_ 1330 ACC_Target30LngRelSpeed 250;
BA_ "GenSigCycleTime" SG_ 1330 ACC_Target30LngRange 100;
BA_ "GenSigInvalidValue" SG_ 1330 ACC_Target30LngRange "4095";
BA_ "GenSigStartValue" SG_ 1330 ACC_Target30LngRange 1500;
BA_ "GenSigCycleTime" SG_ 1330 ACC_Target30LeftLightStatus 100;
BA_ "GenSigCycleTime" SG_ 1330 ACC_Target30LDC 100;
BA_ "GenSigCycleTime" SG_ 1330 ACC_Target30LatRelSpeed 100;
BA_ "GenSigInvalidValue" SG_ 1330 ACC_Target30LatRelSpeed "1024";
BA_ "GenSigStartValue" SG_ 1330 ACC_Target30LatRelSpeed 512;
BA_ "GenSigCycleTime" SG_ 1330 ACC_Target30LatRange 100;
BA_ "GenSigInvalidValue" SG_ 1330 ACC_Target30LatRange "1023";
BA_ "GenSigStartValue" SG_ 1330 ACC_Target30LatRange 500;
BA_ "GenSigCycleTime" SG_ 1330 ACC_Target30ID 100;
BA_ "GenSigCycleTime" SG_ 1330 ACC_Target30HeadingAngle 100;
BA_ "GenSigStartValue" SG_ 1330 ACC_Target30HeadingAngle 314;
BA_ "GenSigCycleTime" SG_ 1330 ACC_Target30Direction 100;
BA_ "GenSigStartValue" SG_ 1330 ACC_Target30Direction 5;
BA_ "GenSigCycleTime" SG_ 1330 ACC_Target30Detection 100;
BA_ "GenSigCycleTime" SG_ 1330 ACC_Target30BSDStatus 100;
BA_ "GenSigInvalidValue" SG_ 1330 ACC_Target30BSDStatus "3";
BA_ "GenSigCycleTime" SG_ 1330 ACC_Target30BrakeLightStatus 100;
BA_ "GenSigCycleTime" SG_ 1330 ACC_Target2RightLightStatus 100;
BA_ "GenSigCycleTime" SG_ 1330 ACC_Target2LngRelSpeed 100;
BA_ "GenSigInvalidValue" SG_ 1330 ACC_Target2LngRelSpeed "511";
BA_ "GenSigStartValue" SG_ 1330 ACC_Target2LngRelSpeed 250;
BA_ "GenSigCycleTime" SG_ 1330 ACC_Target2LeftLightStatus 100;
BA_ "GenSigCycleTime" SG_ 1330 ACC_Target2LDC 100;
BA_ "GenSigCycleTime" SG_ 1330 ACC_Target2LatRelSpeed 100;
BA_ "GenSigInvalidValue" SG_ 1330 ACC_Target2LatRelSpeed "1024";
BA_ "GenSigStartValue" SG_ 1330 ACC_Target2LatRelSpeed 512;
BA_ "GenSigCycleTime" SG_ 1330 ACC_Target2BSDStatus 100;
BA_ "GenSigInvalidValue" SG_ 1330 ACC_Target2BSDStatus "3";
BA_ "GenSigCycleTime" SG_ 1330 ACC_Target2BrakeLightStatus 100;
BA_ "GenSigCycleTime" SG_ 1330 ACC_Target29ZoneID 100;
BA_ "GenSigCycleTime" SG_ 1330 ACC_Target29Type 100;
BA_ "GenSigCycleTime" SG_ 1330 ACC_Target29RightLightStatus 100;
BA_ "GenSigCycleTime" SG_ 1330 ACC_Target29LngRelSpeed 100;
BA_ "GenSigInvalidValue" SG_ 1330 ACC_Target29LngRelSpeed "511";
BA_ "GenSigStartValue" SG_ 1330 ACC_Target29LngRelSpeed 250;
BA_ "GenSigCycleTime" SG_ 1330 ACC_Target29LngRange 100;
BA_ "GenSigInvalidValue" SG_ 1330 ACC_Target29LngRange "4095";
BA_ "GenSigStartValue" SG_ 1330 ACC_Target29LngRange 1500;
BA_ "GenSigCycleTime" SG_ 1330 ACC_Target29LeftLightStatus 100;
BA_ "GenSigCycleTime" SG_ 1330 ACC_Target29LDC 100;
BA_ "GenSigCycleTime" SG_ 1330 ACC_Target29LatRelSpeed 100;
BA_ "GenSigInvalidValue" SG_ 1330 ACC_Target29LatRelSpeed "1024";
BA_ "GenSigStartValue" SG_ 1330 ACC_Target29LatRelSpeed 512;
BA_ "GenSigCycleTime" SG_ 1330 ACC_Target29LatRange 100;
BA_ "GenSigInvalidValue" SG_ 1330 ACC_Target29LatRange "1023";
BA_ "GenSigStartValue" SG_ 1330 ACC_Target29LatRange 500;
BA_ "GenSigCycleTime" SG_ 1330 ACC_Target29ID 100;
BA_ "GenSigCycleTime" SG_ 1330 ACC_Target29HeadingAngle 100;
BA_ "GenSigStartValue" SG_ 1330 ACC_Target29HeadingAngle 314;
BA_ "GenSigCycleTime" SG_ 1330 ACC_Target29Direction 100;
BA_ "GenSigStartValue" SG_ 1330 ACC_Target29Direction 5;
BA_ "GenSigCycleTime" SG_ 1330 ACC_Target29Detection 100;
BA_ "GenSigCycleTime" SG_ 1330 ACC_Target29BSDStatus 100;
BA_ "GenSigInvalidValue" SG_ 1330 ACC_Target29BSDStatus "3";
BA_ "GenSigCycleTime" SG_ 1330 ACC_Target29BrakeLightStatus 100;
BA_ "GenSigCycleTime" SG_ 1330 ACC_Target28ZoneID 100;
BA_ "GenSigCycleTime" SG_ 1330 ACC_Target28Type 100;
BA_ "GenSigCycleTime" SG_ 1330 ACC_Target28RightLightStatus 100;
BA_ "GenSigCycleTime" SG_ 1330 ACC_Target28LngRelSpeed 100;
BA_ "GenSigInvalidValue" SG_ 1330 ACC_Target28LngRelSpeed "511";
BA_ "GenSigStartValue" SG_ 1330 ACC_Target28LngRelSpeed 250;
BA_ "GenSigCycleTime" SG_ 1330 ACC_Target28LngRange 100;
BA_ "GenSigInvalidValue" SG_ 1330 ACC_Target28LngRange "4095";
BA_ "GenSigStartValue" SG_ 1330 ACC_Target28LngRange 1500;
BA_ "GenSigCycleTime" SG_ 1330 ACC_Target28LeftLightStatus 100;
BA_ "GenSigCycleTime" SG_ 1330 ACC_Target28LDC 100;
BA_ "GenSigCycleTime" SG_ 1330 ACC_Target28LatRelSpeed 100;
BA_ "GenSigInvalidValue" SG_ 1330 ACC_Target28LatRelSpeed "1024";
BA_ "GenSigStartValue" SG_ 1330 ACC_Target28LatRelSpeed 512;
BA_ "GenSigCycleTime" SG_ 1330 ACC_Target28LatRange 100;
BA_ "GenSigInvalidValue" SG_ 1330 ACC_Target28LatRange "1023";
BA_ "GenSigStartValue" SG_ 1330 ACC_Target28LatRange 500;
BA_ "GenSigCycleTime" SG_ 1330 ACC_Target28ID 100;
BA_ "GenSigCycleTime" SG_ 1330 ACC_Target28HeadingAngle 100;
BA_ "GenSigStartValue" SG_ 1330 ACC_Target28HeadingAngle 314;
BA_ "GenSigCycleTime" SG_ 1330 ACC_Target28Direction 100;
BA_ "GenSigStartValue" SG_ 1330 ACC_Target28Direction 5;
BA_ "GenSigCycleTime" SG_ 1330 ACC_Target28Detection 100;
BA_ "GenSigCycleTime" SG_ 1330 ACC_Target28BSDStatus 100;
BA_ "GenSigInvalidValue" SG_ 1330 ACC_Target28BSDStatus "3";
BA_ "GenSigCycleTime" SG_ 1330 ACC_Target28BrakeLightStatus 100;
BA_ "GenSigCycleTime" SG_ 1330 ACC_Target27ZoneID 100;
BA_ "GenSigCycleTime" SG_ 1330 ACC_Target27Type 100;
BA_ "GenSigCycleTime" SG_ 1330 ACC_Target27RightLightStatus 100;
BA_ "GenSigCycleTime" SG_ 1330 ACC_Target27LngRelSpeed 100;
BA_ "GenSigInvalidValue" SG_ 1330 ACC_Target27LngRelSpeed "511";
BA_ "GenSigStartValue" SG_ 1330 ACC_Target27LngRelSpeed 250;
BA_ "GenSigCycleTime" SG_ 1330 ACC_Target27LngRange 100;
BA_ "GenSigInvalidValue" SG_ 1330 ACC_Target27LngRange "4095";
BA_ "GenSigStartValue" SG_ 1330 ACC_Target27LngRange 1500;
BA_ "GenSigCycleTime" SG_ 1330 ACC_Target27LeftLightStatus 100;
BA_ "GenSigCycleTime" SG_ 1330 ACC_Target27LDC 100;
BA_ "GenSigCycleTime" SG_ 1330 ACC_Target27LatRelSpeed 100;
BA_ "GenSigInvalidValue" SG_ 1330 ACC_Target27LatRelSpeed "1024";
BA_ "GenSigStartValue" SG_ 1330 ACC_Target27LatRelSpeed 512;
BA_ "GenSigCycleTime" SG_ 1330 ACC_Target27LatRange 100;
BA_ "GenSigInvalidValue" SG_ 1330 ACC_Target27LatRange "1023";
BA_ "GenSigStartValue" SG_ 1330 ACC_Target27LatRange 500;
BA_ "GenSigCycleTime" SG_ 1330 ACC_Target27ID 100;
BA_ "GenSigCycleTime" SG_ 1330 ACC_Target27HeadingAngle 100;
BA_ "GenSigStartValue" SG_ 1330 ACC_Target27HeadingAngle 314;
BA_ "GenSigCycleTime" SG_ 1330 ACC_Target27Direction 100;
BA_ "GenSigStartValue" SG_ 1330 ACC_Target27Direction 5;
BA_ "GenSigCycleTime" SG_ 1330 ACC_Target27Detection 100;
BA_ "GenSigCycleTime" SG_ 1330 ACC_Target27BSDStatus 100;
BA_ "GenSigInvalidValue" SG_ 1330 ACC_Target27BSDStatus "3";
BA_ "GenSigCycleTime" SG_ 1330 ACC_Target26Type 100;
BA_ "GenSigCycleTime" SG_ 1330 ACC_Target26LngRelSpeed 100;
BA_ "GenSigInvalidValue" SG_ 1330 ACC_Target26LngRelSpeed "511";
BA_ "GenSigStartValue" SG_ 1330 ACC_Target26LngRelSpeed 250;
BA_ "GenSigCycleTime" SG_ 1331 APA_DynamicButton 100;
BA_ "GenSigCycleTime" SG_ 1331 APA_DLPReq 100;
BA_ "GenSigCycleTime" SG_ 1331 APA_DetailedVoice_Switch 100;
BA_ "GenSigCycleTime" SG_ 1331 APA_BackstageSearchSts 100;
BA_ "GenSigCycleTime" SG_ 1331 ADS_IACCSysdeactiveReason 100;
BA_ "GenSigCycleTime" SG_ 1331 ADS_IACC_LatTakeOverReason 100;
BA_ "GenSigCycleTime" SG_ 1331 ACC_RLaneQuality 100;
BA_ "GenSigCycleTime" SG_ 1331 ACC_RedLightRemindEnable 100;
BA_ "GenSigCycleTime" SG_ 1331 ACC_DOSECountDown 100;
BA_ "GenSigCycleTime" SG_ 1331 ACC_Target9ZoneID 100;
BA_ "GenSigCycleTime" SG_ 1331 ACC_Target9Type 100;
BA_ "GenSigCycleTime" SG_ 1331 ACC_Target9RightLightStatus 100;
BA_ "GenSigCycleTime" SG_ 1331 ACC_Target9LngRelSpeed 100;
BA_ "GenSigInvalidValue" SG_ 1331 ACC_Target9LngRelSpeed "511";
BA_ "GenSigStartValue" SG_ 1331 ACC_Target9LngRelSpeed 250;
BA_ "GenSigCycleTime" SG_ 1331 ACC_Target9LngRange 100;
BA_ "GenSigInvalidValue" SG_ 1331 ACC_Target9LngRange "4095";
BA_ "GenSigStartValue" SG_ 1331 ACC_Target9LngRange 1500;
BA_ "GenSigCycleTime" SG_ 1331 ACC_Target9LeftLightStatus 100;
BA_ "GenSigCycleTime" SG_ 1331 ACC_Target9LDC 100;
BA_ "GenSigCycleTime" SG_ 1331 ACC_Target9LatRelSpeed 100;
BA_ "GenSigInvalidValue" SG_ 1331 ACC_Target9LatRelSpeed "1024";
BA_ "GenSigStartValue" SG_ 1331 ACC_Target9LatRelSpeed 512;
BA_ "GenSigCycleTime" SG_ 1331 ACC_Target9LatRange 100;
BA_ "GenSigInvalidValue" SG_ 1331 ACC_Target9LatRange "1023";
BA_ "GenSigStartValue" SG_ 1331 ACC_Target9LatRange 500;
BA_ "GenSigCycleTime" SG_ 1331 ACC_Target9ID 100;
BA_ "GenSigCycleTime" SG_ 1331 ACC_Target9HeadingAngle 100;
BA_ "GenSigStartValue" SG_ 1331 ACC_Target9HeadingAngle 314;
BA_ "GenSigCycleTime" SG_ 1331 ACC_Target9Direction 100;
BA_ "GenSigStartValue" SG_ 1331 ACC_Target9Direction 5;
BA_ "GenSigCycleTime" SG_ 1331 ACC_Target9Detection 100;
BA_ "GenSigCycleTime" SG_ 1331 ACC_Target9BSDStatus 100;
BA_ "GenSigInvalidValue" SG_ 1331 ACC_Target9BSDStatus "3";
BA_ "GenSigCycleTime" SG_ 1331 ACC_Target9BrakeLightStatus 100;
BA_ "GenSigCycleTime" SG_ 1331 ACC_Target8ZoneID 100;
BA_ "GenSigCycleTime" SG_ 1331 ACC_Target8Type 100;
BA_ "GenSigCycleTime" SG_ 1331 ACC_Target8RightLightStatus 100;
BA_ "GenSigCycleTime" SG_ 1331 ACC_Target8LngRelSpeed 100;
BA_ "GenSigInvalidValue" SG_ 1331 ACC_Target8LngRelSpeed "511";
BA_ "GenSigStartValue" SG_ 1331 ACC_Target8LngRelSpeed 250;
BA_ "GenSigCycleTime" SG_ 1331 ACC_Target8LngRange 100;
BA_ "GenSigInvalidValue" SG_ 1331 ACC_Target8LngRange "4095";
BA_ "GenSigStartValue" SG_ 1331 ACC_Target8LngRange 1500;
BA_ "GenSigCycleTime" SG_ 1331 ACC_Target8LeftLightStatus 100;
BA_ "GenSigCycleTime" SG_ 1331 ACC_Target8LDC 100;
BA_ "GenSigCycleTime" SG_ 1331 ACC_Target8LatRelSpeed 100;
BA_ "GenSigInvalidValue" SG_ 1331 ACC_Target8LatRelSpeed "1024";
BA_ "GenSigStartValue" SG_ 1331 ACC_Target8LatRelSpeed 512;
BA_ "GenSigCycleTime" SG_ 1331 ACC_Target8LatRange 100;
BA_ "GenSigInvalidValue" SG_ 1331 ACC_Target8LatRange "1023";
BA_ "GenSigStartValue" SG_ 1331 ACC_Target8LatRange 500;
BA_ "GenSigCycleTime" SG_ 1331 ACC_Target8ID 100;
BA_ "GenSigCycleTime" SG_ 1331 ACC_Target8HeadingAngle 100;
BA_ "GenSigStartValue" SG_ 1331 ACC_Target8HeadingAngle 314;
BA_ "GenSigCycleTime" SG_ 1331 ACC_Target8Direction 100;
BA_ "GenSigStartValue" SG_ 1331 ACC_Target8Direction 5;
BA_ "GenSigCycleTime" SG_ 1331 ACC_Target8Detection 100;
BA_ "GenSigCycleTime" SG_ 1331 ACC_Target8BSDStatus 100;
BA_ "GenSigInvalidValue" SG_ 1331 ACC_Target8BSDStatus "3";
BA_ "GenSigCycleTime" SG_ 1331 ACC_Target8BrakeLightStatus 100;
BA_ "GenSigCycleTime" SG_ 1331 ACC_Target7RightLightStatus 100;
BA_ "GenSigCycleTime" SG_ 1331 ACC_Target7LngRelSpeed 100;
BA_ "GenSigInvalidValue" SG_ 1331 ACC_Target7LngRelSpeed "511";
BA_ "GenSigStartValue" SG_ 1331 ACC_Target7LngRelSpeed 250;
BA_ "GenSigCycleTime" SG_ 1331 ACC_Target7LeftLightStatus 100;
BA_ "GenSigCycleTime" SG_ 1331 ACC_Target7LDC 100;
BA_ "GenSigCycleTime" SG_ 1331 ACC_Target7LatRelSpeed 100;
BA_ "GenSigInvalidValue" SG_ 1331 ACC_Target7LatRelSpeed "1024";
BA_ "GenSigStartValue" SG_ 1331 ACC_Target7LatRelSpeed 512;
BA_ "GenSigCycleTime" SG_ 1331 ACC_Target7BSDStatus 100;
BA_ "GenSigInvalidValue" SG_ 1331 ACC_Target7BSDStatus "3";
BA_ "GenSigCycleTime" SG_ 1331 ACC_Target7BrakeLightStatus 100;
BA_ "GenSigCycleTime" SG_ 1331 ACC_Target6RightLightStatus 100;
BA_ "GenSigCycleTime" SG_ 1331 ACC_Target6LngRelSpeed 100;
BA_ "GenSigInvalidValue" SG_ 1331 ACC_Target6LngRelSpeed "511";
BA_ "GenSigStartValue" SG_ 1331 ACC_Target6LngRelSpeed 250;
BA_ "GenSigCycleTime" SG_ 1331 ACC_Target6LeftLightStatus 100;
BA_ "GenSigCycleTime" SG_ 1331 ACC_Target6LDC 100;
BA_ "GenSigCycleTime" SG_ 1331 ACC_Target6LatRelSpeed 100;
BA_ "GenSigInvalidValue" SG_ 1331 ACC_Target6LatRelSpeed "1024";
BA_ "GenSigStartValue" SG_ 1331 ACC_Target6LatRelSpeed 512;
BA_ "GenSigCycleTime" SG_ 1331 ACC_Target6BSDStatus 100;
BA_ "GenSigInvalidValue" SG_ 1331 ACC_Target6BSDStatus "3";
BA_ "GenSigCycleTime" SG_ 1331 ACC_Target6BrakeLightStatus 100;
BA_ "GenSigCycleTime" SG_ 1331 ACC_Target5RightLightStatus 100;
BA_ "GenSigCycleTime" SG_ 1331 ACC_Target5LngRelSpeed 100;
BA_ "GenSigInvalidValue" SG_ 1331 ACC_Target5LngRelSpeed "511";
BA_ "GenSigStartValue" SG_ 1331 ACC_Target5LngRelSpeed 250;
BA_ "GenSigCycleTime" SG_ 1331 ACC_Target5LeftLightStatus 100;
BA_ "GenSigCycleTime" SG_ 1331 ACC_Target5LDC 100;
BA_ "GenSigCycleTime" SG_ 1331 ACC_Target5LatRelSpeed 100;
BA_ "GenSigInvalidValue" SG_ 1331 ACC_Target5LatRelSpeed "1024";
BA_ "GenSigStartValue" SG_ 1331 ACC_Target5LatRelSpeed 512;
BA_ "GenSigCycleTime" SG_ 1331 ACC_Target5BSDStatus 100;
BA_ "GenSigInvalidValue" SG_ 1331 ACC_Target5BSDStatus "3";
BA_ "GenSigCycleTime" SG_ 1331 ACC_Target5BrakeLightStatus 100;
BA_ "GenSigCycleTime" SG_ 1331 ACC_Target4RightLightStatus 100;
BA_ "GenSigCycleTime" SG_ 1331 ACC_Target4LngRelSpeed 100;
BA_ "GenSigInvalidValue" SG_ 1331 ACC_Target4LngRelSpeed "511";
BA_ "GenSigStartValue" SG_ 1331 ACC_Target4LngRelSpeed 250;
BA_ "GenSigCycleTime" SG_ 1331 ACC_Target4LeftLightStatus 100;
BA_ "GenSigCycleTime" SG_ 1331 ACC_Target4LDC 100;
BA_ "GenSigCycleTime" SG_ 1331 ACC_Target4LatRelSpeed 100;
BA_ "GenSigInvalidValue" SG_ 1331 ACC_Target4LatRelSpeed "1024";
BA_ "GenSigStartValue" SG_ 1331 ACC_Target4LatRelSpeed 512;
BA_ "GenSigCycleTime" SG_ 1331 ACC_Target4BSDStatus 100;
BA_ "GenSigInvalidValue" SG_ 1331 ACC_Target4BSDStatus "3";
BA_ "GenSigCycleTime" SG_ 1331 ACC_Target4BrakeLightStatus 100;
BA_ "GenSigCycleTime" SG_ 1331 ACC_Target3RightLightStatus 100;
BA_ "GenSigCycleTime" SG_ 1331 ACC_Target3LngRelSpeed 100;
BA_ "GenSigInvalidValue" SG_ 1331 ACC_Target3LngRelSpeed "511";
BA_ "GenSigStartValue" SG_ 1331 ACC_Target3LngRelSpeed 250;
BA_ "GenSigCycleTime" SG_ 1331 ACC_Target3LeftLightStatus 100;
BA_ "GenSigCycleTime" SG_ 1331 ACC_Target3LDC 100;
BA_ "GenSigCycleTime" SG_ 1331 ACC_Target3LatRelSpeed 100;
BA_ "GenSigInvalidValue" SG_ 1331 ACC_Target3LatRelSpeed "1024";
BA_ "GenSigStartValue" SG_ 1331 ACC_Target3LatRelSpeed 512;
BA_ "GenSigCycleTime" SG_ 1331 ACC_Target3BSDStatus 100;
BA_ "GenSigInvalidValue" SG_ 1331 ACC_Target3BSDStatus "3";
BA_ "GenSigCycleTime" SG_ 1331 ACC_Target3BrakeLightStatus 100;
BA_ "GenSigCycleTime" SG_ 1331 ACC_Target32ZoneID 100;
BA_ "GenSigCycleTime" SG_ 1331 ACC_Target32Type 100;
BA_ "GenSigCycleTime" SG_ 1331 ACC_Target32RightLightStatus 100;
BA_ "GenSigCycleTime" SG_ 1331 ACC_Target32LngRelSpeed 100;
BA_ "GenSigInvalidValue" SG_ 1331 ACC_Target32LngRelSpeed "511";
BA_ "GenSigStartValue" SG_ 1331 ACC_Target32LngRelSpeed 250;
BA_ "GenSigCycleTime" SG_ 1331 ACC_Target32LngRange 100;
BA_ "GenSigInvalidValue" SG_ 1331 ACC_Target32LngRange "4095";
BA_ "GenSigStartValue" SG_ 1331 ACC_Target32LngRange 1500;
BA_ "GenSigCycleTime" SG_ 1331 ACC_Target32LeftLightStatus 100;
BA_ "GenSigCycleTime" SG_ 1331 ACC_Target32LDC 100;
BA_ "GenSigCycleTime" SG_ 1331 ACC_Target32LatRelSpeed 100;
BA_ "GenSigInvalidValue" SG_ 1331 ACC_Target32LatRelSpeed "1024";
BA_ "GenSigStartValue" SG_ 1331 ACC_Target32LatRelSpeed 512;
BA_ "GenSigCycleTime" SG_ 1331 ACC_Target32LatRange 100;
BA_ "GenSigInvalidValue" SG_ 1331 ACC_Target32LatRange "1023";
BA_ "GenSigStartValue" SG_ 1331 ACC_Target32LatRange 500;
BA_ "GenSigCycleTime" SG_ 1331 ACC_Target32ID 100;
BA_ "GenSigCycleTime" SG_ 1331 ACC_Target32HeadingAngle 100;
BA_ "GenSigStartValue" SG_ 1331 ACC_Target32HeadingAngle 314;
BA_ "GenSigCycleTime" SG_ 1331 ACC_Target32Direction 100;
BA_ "GenSigStartValue" SG_ 1331 ACC_Target32Direction 5;
BA_ "GenSigCycleTime" SG_ 1331 ACC_Target32Detection 100;
BA_ "GenSigCycleTime" SG_ 1331 ACC_Target32BSDStatus 100;
BA_ "GenSigInvalidValue" SG_ 1331 ACC_Target32BSDStatus "3";
BA_ "GenSigCycleTime" SG_ 1331 ACC_Target32BrakeLightStatus 100;
BA_ "GenSigCycleTime" SG_ 1331 ACC_Target31ZoneID 100;
BA_ "GenSigCycleTime" SG_ 1331 ACC_Target31Type 100;
BA_ "GenSigCycleTime" SG_ 1331 ACC_Target31RightLightStatus 100;
BA_ "GenSigCycleTime" SG_ 1331 ACC_Target31LngRelSpeed 100;
BA_ "GenSigInvalidValue" SG_ 1331 ACC_Target31LngRelSpeed "511";
BA_ "GenSigStartValue" SG_ 1331 ACC_Target31LngRelSpeed 250;
BA_ "GenSigCycleTime" SG_ 959 PCU_DteDisp 100;
BA_ "GenSigInvalidValue" SG_ 959 PCU_DteDisp "2047";
BA_ "GenSigSendType" SG_ 429 GW_Authernticator_1AD 1;
BA_ "GenSigSendType" SG_ 429 GW_ResetCounter_1AD 1;
BA_ "GenSigSendType" SG_ 429 GW_TripCounter_1AD 1;
BA_ "GenSigSendType" SG_ 1517 KeyLearn_Authernticator_5ED 1;
BA_ "GenSigStartValue" SG_ 1517 KeyLearn_Authernticator_5ED 1;
BA_ "GenSigSendType" SG_ 1517 KeyLearn_Random_5ED 1;
BA_ "GenSigStartValue" SG_ 1517 KeyLearn_Random_5ED 1;
BA_ "GenSigCycleTime" SG_ 1423 mADC_NotSleep_BYTE7BIT6 1000;
BA_ "GenSigCycleTime" SG_ 1423 mADC_NotSleep_BYTE7BIT5 1000;
BA_ "GenSigCycleTime" SG_ 1423 mADC_NotSleep_BYTE7BIT4 1000;
BA_ "GenSigCycleTime" SG_ 1423 mADC_NotSleep_BYTE7BIT3 1000;
BA_ "GenSigCycleTime" SG_ 1423 mADC_NotSleep_BYTE7BIT2 1000;
BA_ "GenSigCycleTime" SG_ 1423 mADC_NotSleep_BYTE7BIT1 1000;
BA_ "GenSigCycleTime" SG_ 1423 mADC_NotSleep_BYTE7BIT0 1000;
BA_ "GenSigCycleTime" SG_ 1423 mADC_WakeUp_BYTE4BIT1 1000;
BA_ "GenSigCycleTime" SG_ 1423 mADC_WakeUp_BYTE4BIT0 1000;
BA_ "GenSigCycleTime" SG_ 958 ATS_CurrentDrivingMode 100;
BA_ "GenSigSendType" SG_ 1718 IQSoftwareversion_P 1;
BA_ "GenSigInvalidValue" SG_ 1718 IQSoftwareversion_P "0";
BA_ "GenSigSendType" SG_ 1718 IQSoftwareversion_D 1;
BA_ "GenSigInvalidValue" SG_ 1718 IQSoftwareversion_D "0";
BA_ "GenSigSendType" SG_ 1718 IQSoftwareversion_R 1;
BA_ "GenSigInvalidValue" SG_ 1718 IQSoftwareversion_R "0";
BA_ "GenSigSendType" SG_ 1718 IQSoftwareversion_F 1;
BA_ "GenSigInvalidValue" SG_ 1718 IQSoftwareversion_F "0";
BA_ "GenSigCycleTime" SG_ 1430 LCDAL_NotSleep_BYTE7BIT4 1000;
BA_ "GenSigCycleTime" SG_ 1430 LCDAL_NotSleep_BYTE7BIT3 1000;
BA_ "GenSigCycleTime" SG_ 1430 LCDAL_NotSleep_BYTE7BIT2 1000;
BA_ "GenSigCycleTime" SG_ 1430 LCDAL_NotSleep_BYTE7BIT1 1000;
BA_ "GenSigCycleTime" SG_ 1430 LCDAL_NotSleep_BYTE7BIT0 1000;
BA_ "GenSigCycleTime" SG_ 1430 LCDAL_WakeUp_BYTE4BIT1 1000;
BA_ "GenSigCycleTime" SG_ 1430 LCDAL_WakeUp_BYTE4BIT0 1000;
BA_ "GenSigCycleTime" SG_ 1431 LCDAR_NotSleep_BYTE7BIT4 1000;
BA_ "GenSigCycleTime" SG_ 1431 LCDAR_NotSleep_BYTE7BIT3 1000;
BA_ "GenSigCycleTime" SG_ 1431 LCDAR_NotSleep_BYTE7BIT2 1000;
BA_ "GenSigCycleTime" SG_ 1431 LCDAR_NotSleep_BYTE7BIT1 1000;
BA_ "GenSigCycleTime" SG_ 1431 LCDAR_NotSleep_BYTE7BIT0 1000;
BA_ "GenSigCycleTime" SG_ 1431 LCDAR_WakeUp_BYTE4BIT1 1000;
BA_ "GenSigCycleTime" SG_ 1431 LCDAR_WakeUp_BYTE4BIT0 1000;
BA_ "GenSigCycleTime" SG_ 1432 FRR_NotSleep_BYTE7BIT1 1000;
BA_ "GenSigCycleTime" SG_ 1432 FRR_NotSleep_BYTE7BIT0 1000;
BA_ "GenSigCycleTime" SG_ 1432 FRR_WakeUp_BYTE4BIT1 1000;
BA_ "GenSigCycleTime" SG_ 1432 FRR_WakeUp_BYTE4BIT0 1000;
BA_ "GenSigCycleTime" SG_ 1442 FLR_NotSleep_BYTE7BIT1 1000;
BA_ "GenSigCycleTime" SG_ 1442 FLR_NotSleep_BYTE7BIT0 1000;
BA_ "GenSigCycleTime" SG_ 1442 FLR_WakeUp_BYTE4BIT1 1000;
BA_ "GenSigCycleTime" SG_ 1442 FLR_WakeUp_BYTE4BIT0 1000;
BA_ "GenSigCycleTime" SG_ 1687 LCDAL_DTC2_Status 500;
BA_ "GenSigCycleTime" SG_ 1687 LCDAL_DTC2_LowByte 500;
BA_ "GenSigCycleTime" SG_ 1687 LCDAL_DTC2_MiddByte 500;
BA_ "GenSigCycleTime" SG_ 1687 LCDAL_DTC2_HighByte 500;
BA_ "GenSigCycleTime" SG_ 1687 LCDAL_DTC1_Status 500;
BA_ "GenSigCycleTime" SG_ 1687 LCDAL_DTC1_LowByte 500;
BA_ "GenSigCycleTime" SG_ 1687 LCDAL_DTC1_MiddByte 500;
BA_ "GenSigCycleTime" SG_ 1687 LCDAL_DTC1_HighByte 500;
BA_ "GenSigCycleTime" SG_ 1755 LCDAR_DTC2_Status 500;
BA_ "GenSigCycleTime" SG_ 1755 LCDAR_DTC2_LowByte 500;
BA_ "GenSigCycleTime" SG_ 1755 LCDAR_DTC2_MiddByte 500;
BA_ "GenSigCycleTime" SG_ 1755 LCDAR_DTC2_HighByte 500;
BA_ "GenSigCycleTime" SG_ 1755 LCDAR_DTC1_Status 500;
BA_ "GenSigCycleTime" SG_ 1755 LCDAR_DTC1_LowByte 500;
BA_ "GenSigCycleTime" SG_ 1755 LCDAR_DTC1_MiddByte 500;
BA_ "GenSigCycleTime" SG_ 1755 LCDAR_DTC1_HighByte 500;
BA_ "GenSigCycleTime" SG_ 1763 FLR_DTC2_Status 500;
BA_ "GenSigCycleTime" SG_ 1763 FLR_DTC2_LowByte 500;
BA_ "GenSigCycleTime" SG_ 1763 FLR_DTC2_MiddByte 500;
BA_ "GenSigCycleTime" SG_ 1763 FLR_DTC2_HighByte 500;
BA_ "GenSigCycleTime" SG_ 1763 FLR_DTC1_Status 500;
BA_ "GenSigCycleTime" SG_ 1763 FLR_DTC1_LowByte 500;
BA_ "GenSigCycleTime" SG_ 1763 FLR_DTC1_MiddByte 500;
BA_ "GenSigCycleTime" SG_ 1763 FLR_DTC1_HighByte 500;
BA_ "GenSigCycleTime" SG_ 1776 FRR_DTC2_Status 500;
BA_ "GenSigCycleTime" SG_ 1776 FRR_DTC2_LowByte 500;
BA_ "GenSigCycleTime" SG_ 1776 FRR_DTC2_MiddByte 500;
BA_ "GenSigCycleTime" SG_ 1776 FRR_DTC2_HighByte 500;
BA_ "GenSigCycleTime" SG_ 1776 FRR_DTC1_Status 500;
BA_ "GenSigCycleTime" SG_ 1776 FRR_DTC1_LowByte 500;
BA_ "GenSigCycleTime" SG_ 1776 FRR_DTC1_MiddByte 500;
BA_ "GenSigCycleTime" SG_ 1776 FRR_DTC1_HighByte 500;
BA_ "GenSigSendType" SG_ 2015 Diagnose_message7DF 1;
BA_ "GenSigSendType" SG_ 1937 Diagnose_message791 1;
BA_ "GenSigSendType" SG_ 1945 Diagnose_message799 1;
BA_ "GenSigSendType" SG_ 1895 Diagnose_message767 1;
BA_ "GenSigSendType" SG_ 1903 Diagnose_message76F 1;
BA_ "GenSigSendType" SG_ 1894 Diagnose_message766 1;
BA_ "GenSigSendType" SG_ 1902 Diagnose_message76E 1;
BA_ "GenSigSendType" SG_ 1875 Diagnose_message753 1;
BA_ "GenSigSendType" SG_ 1883 Diagnose_message75B 1;
BA_ "GenSigSendType" SG_ 1876 Diagnose_message754 1;
BA_ "GenSigSendType" SG_ 1884 Diagnose_message75C 1;
BA_ "GenSigSendType" SG_ 1890 Diagnose_message762 1;
BA_ "GenSigSendType" SG_ 1898 Diagnose_message76A 1;
BA_ "GenSigCycleTime" SG_ 953 BDC_TurnLightSw 100;
BA_ "GenSigInvalidValue" SG_ 953 BDC_TurnLightSw "0";
BA_ "GenSigCycleTime" SG_ 691 THU_ShippingMod 100;
BA_ "GenSigCycleTime" SG_ 989 HU_frontline8_icon 100;
BA_ "GenSigInvalidValue" SG_ 989 HU_frontline8_icon "254";
BA_ "GenSigStartValue" SG_ 989 HU_frontline8_icon 255;
BA_ "GenSigCycleTime" SG_ 989 HU_frontline7_icon 100;
BA_ "GenSigInvalidValue" SG_ 989 HU_frontline7_icon "254";
BA_ "GenSigStartValue" SG_ 989 HU_frontline7_icon 255;
BA_ "GenSigCycleTime" SG_ 989 HU_frontline6_icon 100;
BA_ "GenSigInvalidValue" SG_ 989 HU_frontline6_icon "254";
BA_ "GenSigStartValue" SG_ 989 HU_frontline6_icon 255;
BA_ "GenSigCycleTime" SG_ 989 HU_frontline5_icon 100;
BA_ "GenSigInvalidValue" SG_ 989 HU_frontline5_icon "254";
BA_ "GenSigStartValue" SG_ 989 HU_frontline5_icon 255;
BA_ "GenSigCycleTime" SG_ 989 HU_frontline4_icon 100;
BA_ "GenSigInvalidValue" SG_ 989 HU_frontline4_icon "254";
BA_ "GenSigStartValue" SG_ 989 HU_frontline4_icon 255;
BA_ "GenSigCycleTime" SG_ 989 HU_frontline3_icon 100;
BA_ "GenSigInvalidValue" SG_ 989 HU_frontline3_icon "254";
BA_ "GenSigStartValue" SG_ 989 HU_frontline3_icon 255;
BA_ "GenSigCycleTime" SG_ 989 HU_frontline2_icon 100;
BA_ "GenSigInvalidValue" SG_ 989 HU_frontline2_icon "254";
BA_ "GenSigStartValue" SG_ 989 HU_frontline2_icon 255;
BA_ "GenSigCycleTime" SG_ 989 HU_frontline1_icon 100;
BA_ "GenSigInvalidValue" SG_ 989 HU_frontline1_icon "254";
BA_ "GenSigStartValue" SG_ 989 HU_frontline1_icon 255;
BA_ "GenSigCycleTime" SG_ 989 HU_backline8_icon 100;
BA_ "GenSigInvalidValue" SG_ 989 HU_backline8_icon "255";
BA_ "GenSigStartValue" SG_ 989 HU_backline8_icon 255;
BA_ "GenSigCycleTime" SG_ 989 HU_backline7_icon 100;
BA_ "GenSigInvalidValue" SG_ 989 HU_backline7_icon "255";
BA_ "GenSigStartValue" SG_ 989 HU_backline7_icon 255;
BA_ "GenSigCycleTime" SG_ 989 HU_backline6_icon 100;
BA_ "GenSigInvalidValue" SG_ 989 HU_backline6_icon "255";
BA_ "GenSigStartValue" SG_ 989 HU_backline6_icon 255;
BA_ "GenSigCycleTime" SG_ 989 HU_backline5_icon 100;
BA_ "GenSigInvalidValue" SG_ 989 HU_backline5_icon "255";
BA_ "GenSigStartValue" SG_ 989 HU_backline5_icon 255;
BA_ "GenSigCycleTime" SG_ 989 HU_backline4_icon 100;
BA_ "GenSigInvalidValue" SG_ 989 HU_backline4_icon "255";
BA_ "GenSigStartValue" SG_ 989 HU_backline4_icon 255;
BA_ "GenSigCycleTime" SG_ 989 HU_backline3_icon 100;
BA_ "GenSigInvalidValue" SG_ 989 HU_backline3_icon "255";
BA_ "GenSigStartValue" SG_ 989 HU_backline3_icon 255;
BA_ "GenSigCycleTime" SG_ 989 HU_backline2_icon 100;
BA_ "GenSigInvalidValue" SG_ 989 HU_backline2_icon "255";
BA_ "GenSigStartValue" SG_ 989 HU_backline2_icon 255;
BA_ "GenSigCycleTime" SG_ 989 HU_backline1_icon 100;
BA_ "GenSigInvalidValue" SG_ 989 HU_backline1_icon "255";
BA_ "GenSigStartValue" SG_ 989 HU_backline1_icon 255;
BA_ "GenSigCycleTime" SG_ 989 HU_LineShow 100;
BA_ "GenSigCycleTime" SG_ 1018 ESP_EpbReqAvl 100;
BA_ "GenSigInvalidValue" SG_ 1018 ESP_EpbReqAvl "NA";
BA_ "GenSigCycleTime" SG_ 913 PCU_TowingMode 100;
BA_ "GenSigCycleTime" SG_ 573 HU_RollingCounter_23D 100;
BA_ "GenSigCycleTime" SG_ 573 HU_CRCCheck_23D 100;
BA_ "GenSigCycleTime" SG_ 573 HU_8stRoadTransferTime 100;
BA_ "GenSigInvalidValue" SG_ 573 HU_8stRoadTransferTime "0";
BA_ "GenSigCycleTime" SG_ 573 HU_8stRoadLength 100;
BA_ "GenSigInvalidValue" SG_ 573 HU_8stRoadLength "0";
BA_ "GenSigCycleTime" SG_ 573 HU_8stRoadTrafficStatus 100;
BA_ "GenSigInvalidValue" SG_ 573 HU_8stRoadTrafficStatus "0";
BA_ "GenSigCycleTime" SG_ 573 HU_8stRoadNumber 100;
BA_ "GenSigInvalidValue" SG_ 573 HU_8stRoadNumber "0";
BA_ "GenSigCycleTime" SG_ 573 HU_7stRoadTransferTime 100;
BA_ "GenSigInvalidValue" SG_ 573 HU_7stRoadTransferTime "0";
BA_ "GenSigCycleTime" SG_ 573 HU_7stRoadLength 100;
BA_ "GenSigInvalidValue" SG_ 573 HU_7stRoadLength "0";
BA_ "GenSigCycleTime" SG_ 573 HU_7stRoadTrafficStatus 100;
BA_ "GenSigInvalidValue" SG_ 573 HU_7stRoadTrafficStatus "0";
BA_ "GenSigCycleTime" SG_ 573 HU_7stRoadNumber 100;
BA_ "GenSigInvalidValue" SG_ 573 HU_7stRoadNumber "0";
BA_ "GenSigCycleTime" SG_ 573 HU_6stRoadTransferTime 100;
BA_ "GenSigInvalidValue" SG_ 573 HU_6stRoadTransferTime "0";
BA_ "GenSigCycleTime" SG_ 573 HU_6stRoadLength 100;
BA_ "GenSigInvalidValue" SG_ 573 HU_6stRoadLength "0";
BA_ "GenSigCycleTime" SG_ 573 HU_6stRoadTrafficStatus 100;
BA_ "GenSigInvalidValue" SG_ 573 HU_6stRoadTrafficStatus "0";
BA_ "GenSigCycleTime" SG_ 573 HU_6stRoadNumber 100;
BA_ "GenSigInvalidValue" SG_ 573 HU_6stRoadNumber "0";
BA_ "GenSigCycleTime" SG_ 573 HU_5stRoadTransferTime 100;
BA_ "GenSigInvalidValue" SG_ 573 HU_5stRoadTransferTime "0";
BA_ "GenSigCycleTime" SG_ 573 HU_5stRoadLength 100;
BA_ "GenSigInvalidValue" SG_ 573 HU_5stRoadLength "0";
BA_ "GenSigCycleTime" SG_ 573 HU_5stRoadTrafficStatus 100;
BA_ "GenSigInvalidValue" SG_ 573 HU_5stRoadTrafficStatus "0";
BA_ "GenSigCycleTime" SG_ 573 HU_5stRoadNumber 100;
BA_ "GenSigInvalidValue" SG_ 573 HU_5stRoadNumber "0";
BA_ "GenSigCycleTime" SG_ 573 HU_4stRoadTransferTime 100;
BA_ "GenSigInvalidValue" SG_ 573 HU_4stRoadTransferTime "0";
BA_ "GenSigCycleTime" SG_ 573 HU_4stRoadLength 100;
BA_ "GenSigInvalidValue" SG_ 573 HU_4stRoadLength "0";
BA_ "GenSigCycleTime" SG_ 573 HU_4stRoadTrafficStatus 100;
BA_ "GenSigInvalidValue" SG_ 573 HU_4stRoadTrafficStatus "0";
BA_ "GenSigCycleTime" SG_ 573 HU_4stRoadNumber 100;
BA_ "GenSigInvalidValue" SG_ 573 HU_4stRoadNumber "0";
BA_ "GenSigCycleTime" SG_ 573 HU_3stRoadTransferTime 100;
BA_ "GenSigInvalidValue" SG_ 573 HU_3stRoadTransferTime "0";
BA_ "GenSigCycleTime" SG_ 573 HU_3stRoadLength 100;
BA_ "GenSigInvalidValue" SG_ 573 HU_3stRoadLength "0";
BA_ "GenSigCycleTime" SG_ 573 HU_3stRoadTrafficStatus 100;
BA_ "GenSigInvalidValue" SG_ 573 HU_3stRoadTrafficStatus "0";
BA_ "GenSigCycleTime" SG_ 573 HU_3stRoadNumber 100;
BA_ "GenSigInvalidValue" SG_ 573 HU_3stRoadNumber "0";
BA_ "GenSigCycleTime" SG_ 573 HU_2stRoadTransferTime 100;
BA_ "GenSigInvalidValue" SG_ 573 HU_2stRoadTransferTime "0";
BA_ "GenSigCycleTime" SG_ 573 HU_2stRoadLength 100;
BA_ "GenSigInvalidValue" SG_ 573 HU_2stRoadLength "0";
BA_ "GenSigCycleTime" SG_ 573 HU_2stRoadTrafficStatus 100;
BA_ "GenSigInvalidValue" SG_ 573 HU_2stRoadTrafficStatus "0";
BA_ "GenSigCycleTime" SG_ 573 HU_2stRoadNumber 100;
BA_ "GenSigInvalidValue" SG_ 573 HU_2stRoadNumber "0";
BA_ "GenSigCycleTime" SG_ 573 HU_1stRoadTransferTime 100;
BA_ "GenSigInvalidValue" SG_ 573 HU_1stRoadTransferTime "0";
BA_ "GenSigCycleTime" SG_ 573 HU_1stRoadLength 100;
BA_ "GenSigInvalidValue" SG_ 573 HU_1stRoadLength "1";
BA_ "GenSigCycleTime" SG_ 573 HU_1stRoadTrafficStatus 100;
BA_ "GenSigInvalidValue" SG_ 573 HU_1stRoadTrafficStatus "0";
BA_ "GenSigCycleTime" SG_ 573 HU_1stRoadNumber 100;
BA_ "GenSigInvalidValue" SG_ 573 HU_1stRoadNumber "0";
BA_ "GenSigCycleTime" SG_ 392 TCU_ShiftinProgress 10;
BA_ "GenSigCycleTime" SG_ 632 ESP_YawRateValid 20;
BA_ "GenSigCycleTime" SG_ 632 ESP_YawRate 20;
BA_ "GenSigInvalidValue" SG_ 632 ESP_YawRate "16383";
BA_ "GenSigCycleTime" SG_ 632 ESP_RollingCounter_278 20;
BA_ "GenSigCycleTime" SG_ 632 ESP_LongAccel 20;
BA_ "GenSigInvalidValue" SG_ 632 ESP_LongAccel "1023";
BA_ "GenSigCycleTime" SG_ 632 ESP_LatAccel 20;
BA_ "GenSigInvalidValue" SG_ 632 ESP_LatAccel "255";
BA_ "GenSigCycleTime" SG_ 632 ESP_CRCCheck_278 20;
BA_ "GenSigCycleTime" SG_ 424 TCU_STLKfailure 10;
BA_ "GenSigCycleTime" SG_ 424 TCU_GearShiftPosition 10;
BA_ "GenSigInvalidValue" SG_ 424 TCU_GearShiftPosition "15";
BA_ "GenSigStartValue" SG_ 424 TCU_GearShiftPosition 14;
BA_ "GenSigCycleTime" SG_ 424 TCU_ShiftPostionValid 10;
BA_ "GenSigInvalidValue" SG_ 424 TCU_ShiftPostionValid "1";
BA_ "GenSigCycleTime" SG_ 424 TCU_CRCCheck_1A8 10;
BA_ "GenSigCycleTime" SG_ 424 TCU_RollingCounter_1A8 10;
BA_ "GenSigCycleTime" SG_ 588 TCU_APAShiftGearRequestEnable 20;
BA_ "GenSigInvalidValue" SG_ 588 TCU_APAShiftGearRequestEnable "3";
BA_ "GenSigCycleTime" SG_ 726 EMS_AltitudeFactor 50;
BA_ "GenSigInvalidValue" SG_ 726 EMS_AltitudeFactor "255";
BA_ "GenSigStartValue" SG_ 726 EMS_AltitudeFactor 64;
BA_ "GenSigSendType" SG_ 1515 KeyLearn_Authernticator_5EB 1;
BA_ "GenSigStartValue" SG_ 1515 KeyLearn_Authernticator_5EB 1;
BA_ "GenSigSendType" SG_ 1515 KeyLearn_Random_5EB 1;
BA_ "GenSigStartValue" SG_ 1515 KeyLearn_Random_5EB 1;
BA_ "GenSigCycleTime" SG_ 901 HU_CDCUnitSystSetStatus 100;
BA_ "GenSigStartValue" SG_ 901 HU_CDCUnitSystSetStatus 1;
BA_ "GenSigCycleTime" SG_ 890 VMC_EcasModeFB 100;
BA_ "GenSigCycleTime" SG_ 890 VMC_RollingCounter_37A 100;
BA_ "GenSigCycleTime" SG_ 890 VMC_CRCCheck_37A 100;
BA_ "GenSigCycleTime" SG_ 890 VMC_CtrlLevelRRValid 100;
BA_ "GenSigInvalidValue" SG_ 890 VMC_CtrlLevelRRValid "0";
BA_ "GenSigCycleTime" SG_ 890 VMC_CtrlLevelRLyValid 100;
BA_ "GenSigInvalidValue" SG_ 890 VMC_CtrlLevelRLyValid "0";
BA_ "GenSigCycleTime" SG_ 890 VMC_CtrlLevelFRValid 100;
BA_ "GenSigInvalidValue" SG_ 890 VMC_CtrlLevelFRValid "0";
BA_ "GenSigCycleTime" SG_ 890 VMC_CtrlLevelFLValid 100;
BA_ "GenSigInvalidValue" SG_ 890 VMC_CtrlLevelFLValid "0";
BA_ "GenSigCycleTime" SG_ 890 VMC_LvlTarRR 100;
BA_ "GenSigInvalidValue" SG_ 890 VMC_LvlTarRR "65535";
BA_ "GenSigCycleTime" SG_ 890 VMC_LvlTarRL 100;
BA_ "GenSigInvalidValue" SG_ 890 VMC_LvlTarRL "65535";
BA_ "GenSigCycleTime" SG_ 890 VMC_LvlTarFR 100;
BA_ "GenSigInvalidValue" SG_ 890 VMC_LvlTarFR "65535";
BA_ "GenSigCycleTime" SG_ 890 VMC_LvlTarFL 100;
BA_ "GenSigInvalidValue" SG_ 890 VMC_LvlTarFL "65535";
BA_ "GenSigCycleTime" SG_ 890 VMC_EcasModeRELSts 100;
BA_ "GenSigCycleTime" SG_ 890 VMC_EcasModeFRTSts 100;
BA_ "GenSigCycleTime" SG_ 890 VMC_EcasModeCHASts 100;
BA_ "GenSigCycleTime" SG_ 890 VMC_CtrlLevelRR 100;
BA_ "GenSigInvalidValue" SG_ 890 VMC_CtrlLevelRR "65535";
BA_ "GenSigCycleTime" SG_ 890 VMC_CtrlLevelRL 100;
BA_ "GenSigInvalidValue" SG_ 890 VMC_CtrlLevelRL "65535";
BA_ "GenSigCycleTime" SG_ 890 VMC_CtrlLevelFR 100;
BA_ "GenSigInvalidValue" SG_ 890 VMC_CtrlLevelFR "65535";
BA_ "GenSigCycleTime" SG_ 890 VMC_CtrlLevelFL 100;
BA_ "GenSigInvalidValue" SG_ 890 VMC_CtrlLevelFL "65535";
BA_ "GenSigCycleTime" SG_ 890 VMC_EcasModeVal 100;
BA_ "GenSigCycleTime" SG_ 890 VMC_EcdcMode 100;
VAL_ 1321 ACC_Target17BSDStatus 0 "No LCA warning" 1 "LCA warning level 1" 2 " LCA warning level 2" 3 "Reserved" ;
VAL_ 1321 ACC_Target16RightLightStatus 0 "off" 1 "on" ;
VAL_ 1321 ACC_Target16LngRelSpeed 0 "-250~250
0x1F5~0x1FE=reserved
0x1FF=unknown" ;
VAL_ 1321 ACC_Target16LngRange 0 "-100~300" 4001 "reserved" 4095 "Invalid" ;
VAL_ 1321 ACC_Target16LeftLightStatus 0 "off" 1 "on" ;
VAL_ 1321 ACC_Target16LDC 0 "No LDC warning" 1 " LDC warning" ;
VAL_ 1321 ACC_Target16LatRelSpeed 0 "-64~63.875
0x400=unknown" ;
VAL_ 1321 ACC_Target16LatRange 0 "-50-50m" 1001 "reserved" 1023 "Invalid" ;
VAL_ 1321 ACC_Target16ID 0 "" ;
VAL_ 1321 ACC_Target16Direction 0 "Forward" 1 "OnComing" 2 "Left" 3 "Right" 4 "unknown" 5 "refer to headingangle" 6 "reserved" ;
VAL_ 1321 ACC_Target16Detection 0 "not dectected" 1 "IP display" 2 "Front Target" 3 "IACC target" 4 "AEB target" 5 "dangerous target（ELK、UDLC、RCW, etc）" 6 "other target" 7 "reserved" ;
VAL_ 1321 ACC_Target16BSDStatus 0 "No LCA warning" 1 "LCA warning level 1" 2 " LCA warning level 2" 3 "Reserved" ;
VAL_ 1321 ACC_Target16BrakeLightStatus 0 "off" 1 "on" ;
VAL_ 1321 ACC_Target15ZoneID 0 "no zoneid" 1 "zoneid1-11
0xC=hostlane_zone
0xD=leftlane_zone
0xE=rightlane_zone
0xF=LLLane_zone
0x10=RRLane_zone
0x11=Ramp_zone" 18 "others" 19 "reserved" ;
VAL_ 1321 ACC_Target15Type 0 "no display" 1 "sedan" 2 "motorcycle" 3 "pedestrian" 4 "Bicycle" 5 "Bus" 6 "VAN" 7 "truck" 8 "Cone Consideration" 9 "Warning Column" 10 "Water Horse" 11 "Anti-Collision Bucket" 12 "others" 13 "animal" 14 "Non-road vehicle" 15 "CarWarningTriangle" ;
VAL_ 1321 ACC_Target15RightLightStatus 0 "off" 1 "on" ;
VAL_ 1321 ACC_Target15LngRelSpeed 0 "-250~250
0x1F5~0x1FE=reserved
0x1FF=unknown" ;
VAL_ 1321 ACC_Target15LngRange 0 "-100~300" 4001 "reserved" 4095 "Invalid" ;
VAL_ 1321 ACC_Target15LeftLightStatus 0 "off" 1 "on" ;
VAL_ 1321 ACC_Target15LDC 0 "No LDC warning" 1 " LDC warning" ;
VAL_ 1321 ACC_Target15LatRelSpeed 0 "-64~63.875
0x400=unknown" ;
VAL_ 1321 ACC_Target15LatRange 0 "-50-50m" 1001 "reserved" 1023 "Invalid" ;
VAL_ 1321 ACC_Target15ID 0 "" ;
VAL_ 1321 ACC_Target15Direction 0 "Forward" 1 "OnComing" 2 "Left" 3 "Right" 4 "unknown" 5 "refer to headingangle" 6 "reserved" ;
VAL_ 1321 ACC_Target15Detection 0 "not dectected" 1 "IP display" 2 "Front Target" 3 "IACC target" 4 "AEB target" 5 "dangerous target（ELK、UDLC、RCW, etc）" 6 "other target" 7 "reserved" ;
VAL_ 1321 ACC_Target15BSDStatus 0 "No LCA warning" 1 "LCA warning level 1" 2 " LCA warning level 2" 3 "Reserved" ;
VAL_ 1321 ACC_Target14ZoneID 0 "no zoneid" 1 "zoneid1-11
0xC=hostlane_zone
0xD=leftlane_zone
0xE=rightlane_zone
0xF=LLLane_zone
0x10=RRLane_zone
0x11=Ramp_zone" 18 "others" 19 "reserved" ;
VAL_ 1321 ACC_Target14Type 0 "no display" 1 "sedan" 2 "motorcycle" 3 "pedestrian" 4 "Bicycle" 5 "Bus" 6 "VAN" 7 "truck" 8 "Cone Consideration" 9 "Warning Column" 10 "Water Horse" 11 "Anti-Collision Bucket" 12 "others" 13 "animal" 14 "Non-road vehicle" 15 "CarWarningTriangle" ;
VAL_ 1321 ACC_Target14LngRelSpeed 0 "-250~250" 501 "reserved" 511 "unknown" ;
VAL_ 1321 ACC_Target14LngRange 0 "-100~300" 4001 "reserved" 4095 "Invalid" ;
VAL_ 1321 ACC_Target14LeftLightStatus 0 "off" 1 "on" ;
VAL_ 1321 ACC_Target14LDC 0 "No LDC warning" 1 " LDC warning" ;
VAL_ 1321 ACC_Target14LatRelSpeed 0 "-64~63.875" 1024 "unknown" ;
VAL_ 1321 ACC_Target14LatRange 0 "-50-50m" 1001 "reserved" 1023 "Invalid" ;
VAL_ 1321 ACC_Target14ID 0 "" ;
VAL_ 1321 ACC_Target14Direction 0 "Forward" 1 "OnComing" 2 "Left" 3 "Right" 4 "unknown" 5 "refer to headingangle" 6 "reserved" ;
VAL_ 1321 ACC_Target14Detection 0 "not dectected" 1 "IP display" 2 "Front Target" 3 "IACC target" 4 "AEB target" 5 "dangerous target（ELK、UDLC、RCW, etc）" 6 "other target" 7 "reserved" ;
VAL_ 1321 ACC_Target14BSDStatus 0 "No LCA warning" 1 "LCA warning level 1" 2 " LCA warning level 2" 3 "Reserved" ;
VAL_ 1321 ACC_Target14BrakeLightStatus 0 "off" 1 "on" ;
VAL_ 1321 ACC_Target13ZoneID 0 "no zoneid" 1 "zoneid1-11
0xC=hostlane_zone
0xD=leftlane_zone
0xE=rightlane_zone
0xF=LLLane_zone
0x10=RRLane_zone
0x11=Ramp_zone" 18 "others" 19 "reserved" ;
VAL_ 1321 ACC_Target13Type 0 "no display" 1 "sedan" 2 "motorcycle" 3 "pedestrian" 4 "Bicycle" 5 "Bus" 6 "VAN" 7 "truck" 8 "Cone Consideration" 9 "Warning Column" 10 "Water Horse" 11 "Anti-Collision Bucket" 12 "others" 13 "animal" 14 "Non-road vehicle" 15 "CarWarningTriangle" ;
VAL_ 1321 ACC_Target13RightLightStatus 0 "off" 1 "on" ;
VAL_ 1321 ACC_Target13LngRelSpeed 0 "-250~250" 501 "reserved" 511 "unknown" ;
VAL_ 1321 ACC_Target13LngRange 0 "-100~300" 4001 "reserved" 4095 "Invalid" ;
VAL_ 1321 ACC_Target13LeftLightStatus 0 "off" 1 "on" ;
VAL_ 1321 ACC_Target13LDC 0 "No LDC warning" 1 " LDC warning" ;
VAL_ 1321 ACC_Target13LatRelSpeed 0 "-64~63.875" 1024 "unknown" ;
VAL_ 1321 ACC_Target13LatRange 0 "-50-50m" 1001 "reserved" 1023 "Invalid" ;
VAL_ 1321 ACC_Target13ID 0 "" ;
VAL_ 1321 ACC_Target13Direction 0 "Forward" 1 "OnComing" 2 "Left" 3 "Right" 4 "unknown" 5 "refer to headingangle" 6 "reserved" ;
VAL_ 1321 ACC_Target13Detection 0 "not dectected" 1 "IP display" 2 "Front Target" 3 "IACC target" 4 "AEB target" 5 "dangerous target（ELK、UDLC、RCW, etc）" 6 "other target" 7 "reserved" ;
VAL_ 1321 ACC_Target13BSDStatus 0 "No LCA warning" 1 "LCA warning level 1" 2 " LCA warning level 2" 3 "Reserved" ;
VAL_ 1321 ACC_Target13BrakeLightStatus 0 "off" 1 "on" ;
VAL_ 1321 ACC_Target12ZoneID 0 "no zoneid" 1 "zoneid1-11" 12 "hostlane_zone" 13 "leftlane_zone" 14 "rightlane_zone" 15 "LLLane_zone" 16 "RRLane_zone" 17 "Ramp_zone" 18 "others" 19 "reserved" ;
VAL_ 1321 ACC_Target12Type 0 "no display" 1 "sedan" 2 "motorcycle" 3 "pedestrian" 4 "Bicycle" 5 "Bus" 6 "VAN" 7 "truck" 8 "Cone Consideration" 9 "Warning Column" 10 "Water Horse" 11 "Anti-Collision Bucket" 12 "others" 13 "animal" 14 "Non-road vehicle" 15 "CarWarningTriangle" ;
VAL_ 1321 ACC_Target12RightLightStatus 0 "off" 1 "on" ;
VAL_ 1321 ACC_Target12LngRelSpeed 0 "-250~250
0x1F5~0x1FE=reserved
0x1FF=unknown" ;
VAL_ 1321 ACC_Target12LngRange 0 "-100~300" 4001 "reserved" 4095 "Invalid" ;
VAL_ 1321 ACC_Target12LeftLightStatus 0 "off" 1 "on" ;
VAL_ 1321 ACC_Target12LDC 0 "No LDC warning" 1 " LDC warning" ;
VAL_ 1321 ACC_Target12LatRelSpeed 0 "-64~63.875
0x400=unknown" ;
VAL_ 1321 ACC_Target12LatRange 0 "-50-50m" 1001 "reserved" 1023 "Invalid" ;
VAL_ 1321 ACC_Target12ID 0 "" ;
VAL_ 1321 ACC_Target12Direction 0 "Forward" 1 "OnComing" 2 "Left" 3 "Right" 4 "unknown" 5 "refer to headingangle" 6 "reserved" ;
VAL_ 1321 ACC_Target12Detection 0 "not dectected" 1 "IP display" 2 "Front Target" 3 "IACC target" 4 "AEB target" 5 "dangerous target（ELK、UDLC、RCW, etc）" 6 "other target" 7 "reserved" ;
VAL_ 1321 ACC_Target12BSDStatus 0 "No LCA warning" 1 "LCA warning level 1" 2 " LCA warning level 2" 3 "Reserved" ;
VAL_ 1321 ACC_Target12BrakeLightStatus 0 "off" 1 "on" ;
VAL_ 1321 ACC_Target11ZoneID 0 "no zoneid" 1 "zoneid1-11
0xC=hostlane_zone
0xD=leftlane_zone
0xE=rightlane_zone
0xF=LLLane_zone
0x10=RRLane_zone
0x11=Ramp_zone" 18 "others" 19 "reserved" ;
VAL_ 1321 ACC_Target11RightLightStatus 0 "off" 1 "on" ;
VAL_ 1321 ACC_Target11LngRelSpeed 0 "-250~250
0x1F5~0x1FE=reserved
0x1FF=unknown" ;
VAL_ 1321 ACC_Target11LngRange 0 "-100~300" 4001 "reserved" 4095 "Invalid" ;
VAL_ 1323 ACC_Target22BSDStatus 0 "No LCA warning" 1 "LCA warning level 1" 2 " LCA warning level 2" 3 "Reserved" ;
VAL_ 1323 ACC_Target21RightLightStatus 0 "off" 1 "on" ;
VAL_ 1323 ACC_Target21LngRange 0 "-100~300" 4001 "reserved" 4095 "Invalid" ;
VAL_ 1323 ACC_Target21LeftLightStatus 0 "off" 1 "on" ;
VAL_ 1323 ACC_Target21LDC 0 "No LDC warning" 1 " LDC warning" ;
VAL_ 1323 ACC_Target21LatRelSpeed 0 "-64~63.875
0x400=unknown" ;
VAL_ 1323 ACC_Target21LatRange 0 "-50-50m" 1001 "reserved" 1023 "Invalid" ;
VAL_ 1323 ACC_Target21Direction 0 "Forward" 1 "OnComing" 2 "Left" 3 "Right" 4 "unknown" 5 "refer to headingangle" 6 "reserved" ;
VAL_ 1323 ACC_Target21Detection 0 "not dectected" 1 "IP display" 2 "Front Target" 3 "IACC target" 4 "AEB target" 5 "dangerous target（ELK、UDLC、RCW, etc）" 6 "other target" 7 "reserved" ;
VAL_ 1323 ACC_Target21BSDStatus 0 "No LCA warning" 1 "LCA warning level 1" 2 " LCA warning level 2" 3 "Reserved" ;
VAL_ 1323 ACC_Target21BrakeLightStatus 0 "off" 1 "on" ;
VAL_ 1323 ACC_Target20ZoneID 0 "no zoneid" 1 "zoneid1-11
0xC=hostlane_zone
0xD=leftlane_zone
0xE=rightlane_zone
0xF=LLLane_zone
0x10=RRLane_zone
0x11=Ramp_zone" 18 "others" 19 "reserved" ;
VAL_ 1323 ACC_Target20Type 0 "no display" 1 "sedan" 2 "motorcycle" 3 "pedestrian" 4 "Bicycle" 5 "Bus" 6 "VAN" 7 "truck" 8 "Cone Consideration" 9 "Warning Column" 10 "Water Horse" 11 "Anti-Collision Bucket" 12 "others" 13 "animal" 14 "Non-road vehicle" 15 "CarWarningTriangle" ;
VAL_ 1323 ACC_Target20RightLightStatus 0 "off" 1 "on" ;
VAL_ 1323 ACC_Target20LngRelSpeed 0 "-250~250
0x1F5~0x1FE=reserved
0x1FF=unknown" ;
VAL_ 1323 ACC_Target20LngRange 0 "-100~300" 4001 "reserved" 4095 "Invalid" ;
VAL_ 1323 ACC_Target20LeftLightStatus 0 "off" 1 "on" ;
VAL_ 1323 ACC_Target20LDC 0 "No LDC warning" 1 " LDC warning" ;
VAL_ 1323 ACC_Target20LatRelSpeed 0 "-64~63.875
0x400=unknown" ;
VAL_ 1323 ACC_Target20LatRange 0 "-50-50m" 1001 "reserved" 1023 "Invalid" ;
VAL_ 1323 ACC_Target20ID 0 "" ;
VAL_ 1323 ACC_Target20Direction 0 "Forward" 1 "OnComing" 2 "Left" 3 "Right" 4 "unknown" 5 "refer to headingangle" 6 "reserved" ;
VAL_ 1323 ACC_Target20Detection 0 "not dectected" 1 "IP display" 2 "Front Target" 3 "IACC target" 4 "AEB target" 5 "dangerous target（ELK、UDLC、RCW, etc）" 6 "other target" 7 "reserved" ;
VAL_ 1323 ACC_Target20BSDStatus 0 "No LCA warning" 1 "LCA warning level 1" 2 " LCA warning level 2" 3 "Reserved" ;
VAL_ 1323 ACC_Target20BrakeLightStatus 0 "off" 1 "on" ;
VAL_ 1323 ACC_Target1RightLightStatus 0 "off" 1 "on" ;
VAL_ 1323 ACC_Target1LngRelSpeed 0 "-250~250
0x1F5~0x1FE=reserved
0x1FF=unknown" ;
VAL_ 1323 ACC_Target1LeftLightStatus 0 "off" 1 "on" ;
VAL_ 1323 ACC_Target1LDC 0 "No LDC warning" 1 " LDC warning" ;
VAL_ 1323 ACC_Target1LatRelSpeed 0 "-64~63.875
0x400=unknown" ;
VAL_ 1323 ACC_Target1BSDStatus 0 "No LCA warning" 1 "LCA warning level 1" 2 " LCA warning level 2" 3 "Reserved" ;
VAL_ 1323 ACC_Target1BrakeLightStatus 0 "off" 1 "on" ;
VAL_ 1323 ACC_Target19ZoneID 0 "no zoneid" 1 "zoneid1-11
0xC=hostlane_zone
0xD=leftlane_zone
0xE=rightlane_zone
0xF=LLLane_zone
0x10=RRLane_zone
0x11=Ramp_zone" 18 "others" 19 "reserved" ;
VAL_ 1323 ACC_Target19Type 0 "no display" 1 "sedan" 2 "motorcycle" 3 "pedestrian" 4 "Bicycle" 5 "Bus" 6 "VAN" 7 "truck" 8 "Cone Consideration" 9 "Warning Column" 10 "Water Horse" 11 "Anti-Collision Bucket" 12 "others" 13 "animal" 14 "Non-road vehicle" 15 "CarWarningTriangle" ;
VAL_ 1323 ACC_Target19RightLightStatus 0 "off" 1 "on" ;
VAL_ 1323 ACC_Target19LngRelSpeed 0 "-250~250
0x1F5~0x1FE=reserved
0x1FF=unknown" ;
VAL_ 1323 ACC_Target19LngRange 0 "-100~300" 4001 "reserved" 4095 "Invalid" ;
VAL_ 1323 ACC_Target19LeftLightStatus 0 "off" 1 "on" ;
VAL_ 1323 ACC_Target19LDC 0 "No LDC warning" 1 " LDC warning" ;
VAL_ 1323 ACC_Target19LatRelSpeed 0 "-64~63.875
0x400=unknown" ;
VAL_ 1323 ACC_Target19LatRange 0 "-50-50m" 1001 "reserved" 1023 "Invalid" ;
VAL_ 1323 ACC_Target19ID 0 "" ;
VAL_ 1323 ACC_Target19Direction 0 "Forward" 1 "OnComing" 2 "Left" 3 "Right" 4 "unknown" 5 "refer to headingangle" 6 "reserved" ;
VAL_ 1323 ACC_Target19Detection 0 "not dectected" 1 "IP display" 2 "Front Target" 3 "IACC target" 4 "AEB target" 5 "dangerous target（ELK、UDLC、RCW, etc）" 6 "other target" 7 "reserved" ;
VAL_ 1323 ACC_Target19BSDStatus 0 "No LCA warning" 1 "LCA warning level 1" 2 " LCA warning level 2" 3 "Reserved" ;
VAL_ 1323 ACC_Target19BrakeLightStatus 0 "off" 1 "on" ;
VAL_ 1323 ACC_Target18ZoneID 0 "no zoneid" 1 "zoneid1-11
0xC=hostlane_zone
0xD=leftlane_zone
0xE=rightlane_zone
0xF=LLLane_zone
0x10=RRLane_zone
0x11=Ramp_zone" 18 "others" 19 "reserved" ;
VAL_ 1323 ACC_Target18Type 0 "no display" 1 "sedan" 2 "motorcycle" 3 "pedestrian" 4 "Bicycle" 5 "Bus" 6 "VAN" 7 "truck" 8 "Cone Consideration" 9 "Warning Column" 10 "Water Horse" 11 "Anti-Collision Bucket" 12 "others" 13 "animal" 14 "Non-road vehicle" 15 "CarWarningTriangle" ;
VAL_ 1323 ACC_Target18RightLightStatus 0 "off" 1 "on" ;
VAL_ 1323 ACC_Target18LngRelSpeed 0 "-250~250
0x1F5~0x1FE=reserved
0x1FF=unknown" ;
VAL_ 1323 ACC_Target18LngRange 0 "-100~300" 4001 "reserved" 4095 "Invalid" ;
VAL_ 1323 ACC_Target18LeftLightStatus 0 "off" 1 "on" ;
VAL_ 1323 ACC_Target18LDC 0 "No LDC warning" 1 " LDC warning" ;
VAL_ 1323 ACC_Target18LatRelSpeed 0 "-64~63.875
0x400=unknown" ;
VAL_ 1323 ACC_Target18LatRange 0 "-50-50m" 1001 "reserved" 1023 "Invalid" ;
VAL_ 1323 ACC_Target18ID 0 "" ;
VAL_ 1323 ACC_Target18Direction 0 "Forward" 1 "OnComing" 2 "Left" 3 "Right" 4 "unknown" 5 "refer to headingangle" 6 "reserved" ;
VAL_ 1323 ACC_Target18Detection 0 "not dectected" 1 "IP display" 2 "Front Target" 3 "IACC target" 4 "AEB target" 5 "dangerous target（ELK、UDLC、RCW, etc）" 6 "other target" 7 "reserved" ;
VAL_ 1323 ACC_Target18BSDStatus 0 "No LCA warning" 1 "LCA warning level 1" 2 " LCA warning level 2" 3 "Reserved" ;
VAL_ 1323 ACC_Target18BrakeLightStatus 0 "off" 1 "on" ;
VAL_ 1323 ACC_Target17ZoneID 0 "no zoneid" 1 "zoneid1-11
0xC=hostlane_zone
0xD=leftlane_zone
0xE=rightlane_zone
0xF=LLLane_zone
0x10=RRLane_zone
0x11=Ramp_zone" 18 "others" 19 "reserved" ;
VAL_ 1323 ACC_Target17Type 0 "no display" 1 "sedan" 2 "motorcycle" 3 "pedestrian" 4 "Bicycle" 5 "Bus" 6 "VAN" 7 "truck" 8 "Cone Consideration" 9 "Warning Column" 10 "Water Horse" 11 "Anti-Collision Bucket" 12 "others" 13 "animal" 14 "Non-road vehicle" 15 "CarWarningTriangle" ;
VAL_ 1323 ACC_Target17RightLightStatus 0 "off" 1 "on" ;
VAL_ 1323 ACC_Target17LngRelSpeed 0 "-250~250
0x1F5~0x1FE=reserved
0x1FF=unknown" ;
VAL_ 1323 ACC_Target17LngRange 0 "-100~300" 4001 "reserved" 4095 "Invalid" ;
VAL_ 1323 ACC_Target17LeftLightStatus 0 "off" 1 "on" ;
VAL_ 1323 ACC_Target17LDC 0 "No LDC warning" 1 " LDC warning" ;
VAL_ 1323 ACC_Target17LatRelSpeed 0 "-64~63.875
0x400=unknown" ;
VAL_ 1323 ACC_Target17LatRange 0 "-50-50m" 1001 "reserved" 1023 "Invalid" ;
VAL_ 1323 ACC_Target17ID 0 "" ;
VAL_ 1323 ACC_Target17Direction 0 "Forward" 1 "OnComing" 2 "Left" 3 "Right" 4 "unknown" 5 "refer to headingangle" 6 "reserved" ;
VAL_ 1323 ACC_Target17Detection 0 "not dectected" 1 "IP display" 2 "Front Target" 3 "IACC target" 4 "AEB target" 5 "dangerous target（ELK、UDLC、RCW, etc）" 6 "other target" 7 "reserved" ;
VAL_ 1323 ACC_Target17BrakeLightStatus 0 "off" 1 "on" ;
VAL_ 1323 ACC_Target16ZoneID 0 "no zoneid" 1 "zoneid1-11
0xC=hostlane_zone
0xD=leftlane_zone
0xE=rightlane_zone
0xF=LLLane_zone
0x10=RRLane_zone
0x11=Ramp_zone" 18 "others" 19 "reserved" ;
VAL_ 1323 ACC_Target16Type 0 "no display" 1 "sedan" 2 "motorcycle" 3 "pedestrian" 4 "Bicycle" 5 "Bus" 6 "VAN" 7 "truck" 8 "Cone Consideration" 9 "Warning Column" 10 "Water Horse" 11 "Anti-Collision Bucket" 12 "others" 13 "animal" 14 "Non-road vehicle" 15 "CarWarningTriangle" ;
VAL_ 1329 ACC_Target27BrakeLightStatus 0 "off" 1 "on" ;
VAL_ 1329 ACC_Target26ZoneID 0 "no zoneid" 1 "zoneid1-11
0xC=hostlane_zone
0xD=leftlane_zone
0xE=rightlane_zone
0xF=LLLane_zone
0x10=RRLane_zone
0x11=Ramp_zone" 18 "others" 19 "reserved" ;
VAL_ 1329 ACC_Target26RightLightStatus 0 "off" 1 "on" ;
VAL_ 1329 ACC_Target26LngRange 0 "-100~300" 4001 "reserved" 4095 "Invalid" ;
VAL_ 1329 ACC_Target26LeftLightStatus 0 "off" 1 "on" ;
VAL_ 1329 ACC_Target26LDC 0 "No LDC warning" 1 " LDC warning" ;
VAL_ 1329 ACC_Target26LatRelSpeed 0 "-64~63.875
0x400=unknown" ;
VAL_ 1329 ACC_Target26LatRange 0 "-50-50m" 1001 "reserved" 1023 "Invalid" ;
VAL_ 1329 ACC_Target26ID 0 "" ;
VAL_ 1329 ACC_Target26Direction 0 "Forward" 1 "OnComing" 2 "Left" 3 "Right" 4 "unknown" 5 "refer to headingangle" 6 "reserved" ;
VAL_ 1329 ACC_Target26Detection 0 "not dectected" 1 "IP display" 2 "Front Target" 3 "IACC target" 4 "AEB target" 5 "dangerous target（ELK、UDLC、RCW, etc）" 6 "other target" 7 "reserved" ;
VAL_ 1329 ACC_Target26BSDStatus 0 "No LCA warning" 1 "LCA warning level 1" 2 " LCA warning level 2" 3 "Reserved" ;
VAL_ 1329 ACC_Target26BrakeLightStatus 0 "off" 1 "on" ;
VAL_ 1329 ACC_Target25ZoneID 0 "no zoneid" 1 "zoneid1-11
0xC=hostlane_zone
0xD=leftlane_zone
0xE=rightlane_zone
0xF=LLLane_zone
0x10=RRLane_zone
0x11=Ramp_zone" 18 "others" 19 "reserved" ;
VAL_ 1329 ACC_Target25Type 0 "no display" 1 "sedan" 2 "motorcycle" 3 "pedestrian" 4 "Bicycle" 5 "Bus" 6 "VAN" 7 "truck" 8 "Cone Consideration" 9 "Warning Column" 10 "Water Horse" 11 "Anti-Collision Bucket" 12 "others" 13 "animal" 14 "Non-road vehicle" 15 "CarWarningTriangle" ;
VAL_ 1329 ACC_Target25RightLightStatus 0 "off" 1 "on" ;
VAL_ 1329 ACC_Target25LngRelSpeed 0 "-250~250
0x1F5~0x1FE=reserved
0x1FF=unknown" ;
VAL_ 1329 ACC_Target25LngRange 0 "-100~300" 4001 "reserved" 4095 "Invalid" ;
VAL_ 1329 ACC_Target25LeftLightStatus 0 "off" 1 "on" ;
VAL_ 1329 ACC_Target25LDC 0 "No LDC warning" 1 " LDC warning" ;
VAL_ 1329 ACC_Target25LatRelSpeed 0 "-64~63.875
0x400=unknown" ;
VAL_ 1329 ACC_Target25LatRange 0 "-50-50m" 1001 "reserved" 1023 "Invalid" ;
VAL_ 1329 ACC_Target25ID 0 "" ;
VAL_ 1329 ACC_Target25Direction 0 "Forward" 1 "OnComing" 2 "Left" 3 "Right" 4 "unknown" 5 "refer to headingangle" 6 "reserved" ;
VAL_ 1329 ACC_Target25Detection 0 "not dectected" 1 "IP display" 2 "Front Target" 3 "IACC target" 4 "AEB target" 5 "dangerous target（ELK、UDLC、RCW, etc）" 6 "other target" 7 "reserved" ;
VAL_ 1329 ACC_Target25BSDStatus 0 "No LCA warning" 1 "LCA warning level 1" 2 " LCA warning level 2" 3 "Reserved" ;
VAL_ 1329 ACC_Target25BrakeLightStatus 0 "off" 1 "on" ;
VAL_ 1329 ACC_Target24ZoneID 0 "no zoneid" 1 "zoneid1-11
0xC=hostlane_zone
0xD=leftlane_zone
0xE=rightlane_zone
0xF=LLLane_zone
0x10=RRLane_zone
0x11=Ramp_zone" 18 "others" 19 "reserved" ;
VAL_ 1329 ACC_Target24Type 0 "no display" 1 "sedan" 2 "motorcycle" 3 "pedestrian" 4 "Bicycle" 5 "Bus" 6 "VAN" 7 "truck" 8 "Cone Consideration" 9 "Warning Column" 10 "Water Horse" 11 "Anti-Collision Bucket" 12 "others" 13 "animal" 14 "Non-road vehicle" 15 "CarWarningTriangle" ;
VAL_ 1329 ACC_Target24RightLightStatus 0 "off" 1 "on" ;
VAL_ 1329 ACC_Target24LngRelSpeed 0 "-250~250
0x1F5~0x1FE=reserved
0x1FF=unknown" ;
VAL_ 1329 ACC_Target24LngRange 0 "-100~300" 4001 "reserved" 4095 "Invalid" ;
VAL_ 1329 ACC_Target24LeftLightStatus 0 "off" 1 "on" ;
VAL_ 1329 ACC_Target24LDC 0 "No LDC warning" 1 " LDC warning" ;
VAL_ 1329 ACC_Target24LatRelSpeed 0 "-64~63.875
0x400=unknown" ;
VAL_ 1329 ACC_Target24LatRange 0 "-50-50m" 1001 "reserved" 1023 "Invalid" ;
VAL_ 1329 ACC_Target24ID 0 "" ;
VAL_ 1329 ACC_Target24Direction 0 "Forward" 1 "OnComing" 2 "Left" 3 "Right" 4 "unknown" 5 "refer to headingangle" 6 "reserved" ;
VAL_ 1329 ACC_Target24Detection 0 "not dectected" 1 "IP display" 2 "Front Target" 3 "IACC target" 4 "AEB target" 5 "dangerous target（ELK、UDLC、RCW, etc）" 6 "other target" 7 "reserved" ;
VAL_ 1329 ACC_Target24BSDStatus 0 "No LCA warning" 1 "LCA warning level 1" 2 " LCA warning level 2" 3 "Reserved" ;
VAL_ 1329 ACC_Target24BrakeLightStatus 0 "off" 1 "on" ;
VAL_ 1329 ACC_Target23ZoneID 0 "no zoneid" 1 "zoneid1-11
0xC=hostlane_zone
0xD=leftlane_zone
0xE=rightlane_zone
0xF=LLLane_zone
0x10=RRLane_zone
0x11=Ramp_zone" 18 "others" 19 "reserved" ;
VAL_ 1329 ACC_Target23Type 0 "no display" 1 "sedan" 2 "motorcycle" 3 "pedestrian" 4 "Bicycle" 5 "Bus" 6 "VAN" 7 "truck" 8 "Cone Consideration" 9 "Warning Column" 10 "Water Horse" 11 "Anti-Collision Bucket" 12 "others" 13 "animal" 14 "Non-road vehicle" 15 "CarWarningTriangle" ;
VAL_ 1329 ACC_Target23RightLightStatus 0 "off" 1 "on" ;
VAL_ 1329 ACC_Target23LngRelSpeed 0 "-250~250
0x1F5~0x1FE=reserved
0x1FF=unknown" ;
VAL_ 1329 ACC_Target23LngRange 0 "-100~300" 4001 "reserved" 4095 "Invalid" ;
VAL_ 1329 ACC_Target23LeftLightStatus 0 "off" 1 "on" ;
VAL_ 1329 ACC_Target23LDC 0 "No LDC warning" 1 " LDC warning" ;
VAL_ 1329 ACC_Target23LatRelSpeed 0 "-64~63.875
0x400=unknown" ;
VAL_ 1329 ACC_Target23LatRange 0 "-50-50m" 1001 "reserved" 1023 "Invalid" ;
VAL_ 1329 ACC_Target23ID 0 "" ;
VAL_ 1329 ACC_Target23Direction 0 "Forward" 1 "OnComing" 2 "Left" 3 "Right" 4 "unknown" 5 "refer to headingangle" 6 "reserved" ;
VAL_ 1329 ACC_Target23Detection 0 "not dectected" 1 "IP display" 2 "Front Target" 3 "IACC target" 4 "AEB target" 5 "dangerous target（ELK、UDLC、RCW, etc）" 6 "other target" 7 "reserved" ;
VAL_ 1329 ACC_Target23BSDStatus 0 "No LCA warning" 1 "LCA warning level 1" 2 " LCA warning level 2" 3 "Reserved" ;
VAL_ 1329 ACC_Target23BrakeLightStatus 0 "off" 1 "on" ;
VAL_ 1329 ACC_Target22ZoneID 0 "no zoneid" 1 "zoneid1-11
0xC=hostlane_zone
0xD=leftlane_zone
0xE=rightlane_zone
0xF=LLLane_zone
0x10=RRLane_zone
0x11=Ramp_zone" 18 "others" 19 "reserved" ;
VAL_ 1329 ACC_Target22Type 0 "no display" 1 "sedan" 2 "motorcycle" 3 "pedestrian" 4 "Bicycle" 5 "Bus" 6 "VAN" 7 "truck" 8 "Cone Consideration" 9 "Warning Column" 10 "Water Horse" 11 "Anti-Collision Bucket" 12 "others" 13 "animal" 14 "Non-road vehicle" 15 "CarWarningTriangle" ;
VAL_ 1329 ACC_Target22RightLightStatus 0 "off" 1 "on" ;
VAL_ 1329 ACC_Target22LngRelSpeed 0 "-250~250
0x1F5~0x1FE=reserved
0x1FF=unknown" ;
VAL_ 1329 ACC_Target22LngRange 0 "-100~300" 4001 "reserved" 4095 "Invalid" ;
VAL_ 1329 ACC_Target22LeftLightStatus 0 "off" 1 "on" ;
VAL_ 1329 ACC_Target22LDC 0 "No LDC warning" 1 " LDC warning" ;
VAL_ 1329 ACC_Target22LatRelSpeed 0 "-64~63.875
0x400=unknown" ;
VAL_ 1329 ACC_Target22LatRange 0 "-50-50m" 1001 "reserved" 1023 "Invalid" ;
VAL_ 1329 ACC_Target22ID 0 "" ;
VAL_ 1329 ACC_Target22Direction 0 "Forward" 1 "OnComing" 2 "Left" 3 "Right" 4 "unknown" 5 "refer to headingangle" 6 "reserved" ;
VAL_ 1329 ACC_Target22Detection 0 "not dectected" 1 "IP display" 2 "Front Target" 3 "IACC target" 4 "AEB target" 5 "dangerous target（ELK、UDLC、RCW, etc）" 6 "other target" 7 "reserved" ;
VAL_ 1329 ACC_Target22BrakeLightStatus 0 "off" 1 "on" ;
VAL_ 1329 ACC_Target21ZoneID 0 "no zoneid" 1 "zoneid1-11
0xC=hostlane_zone
0xD=leftlane_zone
0xE=rightlane_zone
0xF=LLLane_zone
0x10=RRLane_zone
0x11=Ramp_zone" 18 "others" 19 "reserved" ;
VAL_ 1329 ACC_Target21Type 0 "no display" 1 "sedan" 2 "motorcycle" 3 "pedestrian" 4 "Bicycle" 5 "Bus" 6 "VAN" 7 "truck" 8 "Cone Consideration" 9 "Warning Column" 10 "Water Horse" 11 "Anti-Collision Bucket" 12 "others" 13 "animal" 14 "Non-road vehicle" 15 "CarWarningTriangle" ;
VAL_ 1329 ACC_Target21LngRelSpeed 0 "-250~250
0x1F5~0x1FE=reserved
0x1FF=unknown" ;
VAL_ 1329 ACC_Target21ID 0 "" ;
VAL_ 1330 ACC_Target31LngRange 0 "-100~300" 4001 "reserved" 4095 "Invalid" ;
VAL_ 1330 ACC_Target31LeftLightStatus 0 "off" 1 "on" ;
VAL_ 1330 ACC_Target31LDC 0 "No LDC warning" 1 " LDC warning" ;
VAL_ 1330 ACC_Target31LatRelSpeed 0 "-64~63.875
0x400=unknown" ;
VAL_ 1330 ACC_Target31LatRange 0 "-50-50m" 1001 "reserved" 1023 "Invalid" ;
VAL_ 1330 ACC_Target31ID 0 "" ;
VAL_ 1330 ACC_Target31Direction 0 "Forward" 1 "OnComing" 2 "Left" 3 "Right" 4 "unknown" 5 "refer to headingangle" 6 "reserved" ;
VAL_ 1330 ACC_Target31Detection 0 "not dectected" 1 "IP display" 2 "Front Target" 3 "IACC target" 4 "AEB target" 5 "dangerous target（ELK、UDLC、RCW, etc）" 6 "other target" 7 "reserved" ;
VAL_ 1330 ACC_Target31BSDStatus 0 "No LCA warning" 1 "LCA warning level 1" 2 " LCA warning level 2" 3 "Reserved" ;
VAL_ 1330 ACC_Target31BrakeLightStatus 0 "off" 1 "on" ;
VAL_ 1330 ACC_Target30ZoneID 0 "no zoneid" 1 "zoneid1-11
0xC=hostlane_zone
0xD=leftlane_zone
0xE=rightlane_zone
0xF=LLLane_zone
0x10=RRLane_zone
0x11=Ramp_zone" 18 "others" 19 "reserved" ;
VAL_ 1330 ACC_Target30Type 0 "no display" 1 "sedan" 2 "motorcycle" 3 "pedestrian" 4 "Bicycle" 5 "Bus" 6 "VAN" 7 "truck" 8 "Cone Consideration" 9 "Warning Column" 10 "Water Horse" 11 "Anti-Collision Bucket" 12 "others" 13 "animal" 14 "Non-road vehicle" 15 "CarWarningTriangle" ;
VAL_ 1330 ACC_Target30RightLightStatus 0 "off" 1 "on" ;
VAL_ 1330 ACC_Target30LngRelSpeed 0 "-250~250
0x1F5~0x1FE=reserved
0x1FF=unknown" ;
VAL_ 1330 ACC_Target30LngRange 0 "-100~300" 4001 "reserved" 4095 "Invalid" ;
VAL_ 1330 ACC_Target30LeftLightStatus 0 "off" 1 "on" ;
VAL_ 1330 ACC_Target30LDC 0 "No LDC warning" 1 " LDC warning" ;
VAL_ 1330 ACC_Target30LatRelSpeed 0 "-64~63.875
0x400=unknown" ;
VAL_ 1330 ACC_Target30LatRange 0 "-50-50m" 1001 "reserved" 1023 "Invalid" ;
VAL_ 1330 ACC_Target30ID 0 "" ;
VAL_ 1330 ACC_Target30Direction 0 "Forward" 1 "OnComing" 2 "Left" 3 "Right" 4 "unknown" 5 "refer to headingangle" 6 "reserved" ;
VAL_ 1330 ACC_Target30Detection 0 "not dectected" 1 "IP display" 2 "Front Target" 3 "IACC target" 4 "AEB target" 5 "dangerous target（ELK、UDLC、RCW, etc）" 6 "other target" 7 "reserved" ;
VAL_ 1330 ACC_Target30BSDStatus 0 "No LCA warning" 1 "LCA warning level 1" 2 " LCA warning level 2" 3 "Reserved" ;
VAL_ 1330 ACC_Target30BrakeLightStatus 0 "off" 1 "on" ;
VAL_ 1330 ACC_Target2RightLightStatus 0 "off" 1 "on" ;
VAL_ 1330 ACC_Target2LngRelSpeed 0 "-250~250
0x1F5~0x1FE=reserved
0x1FF=unknown" ;
VAL_ 1330 ACC_Target2LeftLightStatus 0 "off" 1 "on" ;
VAL_ 1330 ACC_Target2LDC 0 "No LDC warning" 1 " LDC warning" ;
VAL_ 1330 ACC_Target2LatRelSpeed 0 "-64~63.875
0x400=unknown" ;
VAL_ 1330 ACC_Target2BSDStatus 0 "No LCA warning" 1 "LCA warning level 1" 2 " LCA warning level 2" 3 "Reserved" ;
VAL_ 1330 ACC_Target2BrakeLightStatus 0 "off" 1 "on" ;
VAL_ 1330 ACC_Target29ZoneID 0 "no zoneid" 1 "zoneid1-11
0xC=hostlane_zone
0xD=leftlane_zone
0xE=rightlane_zone
0xF=LLLane_zone
0x10=RRLane_zone
0x11=Ramp_zone" 18 "others" 19 "reserved" ;
VAL_ 1330 ACC_Target29Type 0 "no display" 1 "sedan" 2 "motorcycle" 3 "pedestrian" 4 "Bicycle" 5 "Bus" 6 "VAN" 7 "truck" 8 "Cone Consideration" 9 "Warning Column" 10 "Water Horse" 11 "Anti-Collision Bucket" 12 "others" 13 "animal" 14 "Non-road vehicle" 15 "CarWarningTriangle" ;
VAL_ 1330 ACC_Target29RightLightStatus 0 "off" 1 "on" ;
VAL_ 1330 ACC_Target29LngRelSpeed 0 "-250~250
0x1F5~0x1FE=reserved
0x1FF=unknown" ;
VAL_ 1330 ACC_Target29LngRange 0 "-100~300" 4001 "reserved" 4095 "Invalid" ;
VAL_ 1330 ACC_Target29LeftLightStatus 0 "off" 1 "on" ;
VAL_ 1330 ACC_Target29LDC 0 "No LDC warning" 1 " LDC warning" ;
VAL_ 1330 ACC_Target29LatRelSpeed 0 "-64~63.875
0x400=unknown" ;
VAL_ 1330 ACC_Target29LatRange 0 "-50-50m" 1001 "reserved" 1023 "Invalid" ;
VAL_ 1330 ACC_Target29ID 0 "" ;
VAL_ 1330 ACC_Target29Direction 0 "Forward" 1 "OnComing" 2 "Left" 3 "Right" 4 "unknown" 5 "refer to headingangle" 6 "reserved" ;
VAL_ 1330 ACC_Target29Detection 0 "not dectected" 1 "IP display" 2 "Front Target" 3 "IACC target" 4 "AEB target" 5 "dangerous target（ELK、UDLC、RCW, etc）" 6 "other target" 7 "reserved" ;
VAL_ 1330 ACC_Target29BSDStatus 0 "No LCA warning" 1 "LCA warning level 1" 2 " LCA warning level 2" 3 "Reserved" ;
VAL_ 1330 ACC_Target29BrakeLightStatus 0 "off" 1 "on" ;
VAL_ 1330 ACC_Target28ZoneID 0 "no zoneid" 1 "zoneid1-11
0xC=hostlane_zone
0xD=leftlane_zone
0xE=rightlane_zone
0xF=LLLane_zone
0x10=RRLane_zone
0x11=Ramp_zone" 18 "others" 19 "reserved" ;
VAL_ 1330 ACC_Target28Type 0 "no display" 1 "sedan" 2 "motorcycle" 3 "pedestrian" 4 "Bicycle" 5 "Bus" 6 "VAN" 7 "truck" 8 "Cone Consideration" 9 "Warning Column" 10 "Water Horse" 11 "Anti-Collision Bucket" 12 "others" 13 "animal" 14 "Non-road vehicle" 15 "CarWarningTriangle" ;
VAL_ 1330 ACC_Target28RightLightStatus 0 "off" 1 "on" ;
VAL_ 1330 ACC_Target28LngRelSpeed 0 "-250~250
0x1F5~0x1FE=reserved
0x1FF=unknown" ;
VAL_ 1330 ACC_Target28LngRange 0 "-100~300" 4001 "reserved" 4095 "Invalid" ;
VAL_ 1330 ACC_Target28LeftLightStatus 0 "off" 1 "on" ;
VAL_ 1330 ACC_Target28LDC 0 "No LDC warning" 1 " LDC warning" ;
VAL_ 1330 ACC_Target28LatRelSpeed 0 "-64~63.875
0x400=unknown" ;
VAL_ 1330 ACC_Target28LatRange 0 "-50-50m" 1001 "reserved" 1023 "Invalid" ;
VAL_ 1330 ACC_Target28ID 0 "" ;
VAL_ 1330 ACC_Target28Direction 0 "Forward" 1 "OnComing" 2 "Left" 3 "Right" 4 "unknown" 5 "refer to headingangle" 6 "reserved" ;
VAL_ 1330 ACC_Target28Detection 0 "not dectected" 1 "IP display" 2 "Front Target" 3 "IACC target" 4 "AEB target" 5 "dangerous target（ELK、UDLC、RCW, etc）" 6 "other target" 7 "reserved" ;
VAL_ 1330 ACC_Target28BSDStatus 0 "No LCA warning" 1 "LCA warning level 1" 2 " LCA warning level 2" 3 "Reserved" ;
VAL_ 1330 ACC_Target28BrakeLightStatus 0 "off" 1 "on" ;
VAL_ 1330 ACC_Target27ZoneID 0 "no zoneid" 1 "zoneid1-11
0xC=hostlane_zone
0xD=leftlane_zone
0xE=rightlane_zone
0xF=LLLane_zone
0x10=RRLane_zone
0x11=Ramp_zone" 18 "others" 19 "reserved" ;
VAL_ 1330 ACC_Target27Type 0 "no display" 1 "sedan" 2 "motorcycle" 3 "pedestrian" 4 "Bicycle" 5 "Bus" 6 "VAN" 7 "truck" 8 "Cone Consideration" 9 "Warning Column" 10 "Water Horse" 11 "Anti-Collision Bucket" 12 "others" 13 "animal" 14 "Non-road vehicle" 15 "CarWarningTriangle" ;
VAL_ 1330 ACC_Target27RightLightStatus 0 "off" 1 "on" ;
VAL_ 1330 ACC_Target27LngRelSpeed 0 "-250~250
0x1F5~0x1FE=reserved
0x1FF=unknown" ;
VAL_ 1330 ACC_Target27LngRange 0 "-100~300" 4001 "reserved" 4095 "Invalid" ;
VAL_ 1330 ACC_Target27LeftLightStatus 0 "off" 1 "on" ;
VAL_ 1330 ACC_Target27LDC 0 "No LDC warning" 1 " LDC warning" ;
VAL_ 1330 ACC_Target27LatRelSpeed 0 "-64~63.875
0x400=unknown" ;
VAL_ 1330 ACC_Target27LatRange 0 "-50-50m" 1001 "reserved" 1023 "Invalid" ;
VAL_ 1330 ACC_Target27ID 0 "" ;
VAL_ 1330 ACC_Target27Direction 0 "Forward" 1 "OnComing" 2 "Left" 3 "Right" 4 "unknown" 5 "refer to headingangle" 6 "reserved" ;
VAL_ 1330 ACC_Target27Detection 0 "not dectected" 1 "IP display" 2 "Front Target" 3 "IACC target" 4 "AEB target" 5 "dangerous target（ELK、UDLC、RCW, etc）" 6 "other target" 7 "reserved" ;
VAL_ 1330 ACC_Target27BSDStatus 0 "No LCA warning" 1 "LCA warning level 1" 2 " LCA warning level 2" 3 "Reserved" ;
VAL_ 1330 ACC_Target26Type 0 "no display" 1 "sedan" 2 "motorcycle" 3 "pedestrian" 4 "Bicycle" 5 "Bus" 6 "VAN" 7 "truck" 8 "Cone Consideration" 9 "Warning Column" 10 "Water Horse" 11 "Anti-Collision Bucket" 12 "others" 13 "animal" 14 "Non-road vehicle" 15 "CarWarningTriangle" ;
VAL_ 1330 ACC_Target26LngRelSpeed 0 "-250~250
0x1F5~0x1FE=reserved
0x1FF=unknown" ;
VAL_ 1331 APA_DynamicButton 0 "" ;
VAL_ 1331 APA_DLPReq 0 "No Request
0x1=Parking Active
0x2=Parking Suspension
0x3=Parking Completed
0x4=Parking Failed
0x5=Pedestrian Avoidance
0x6=Vehicle Avoidance
0x7=Straight In and Out On
0x8=Straight In Active
0x9=Straight Out Active
0xA-0xF=Reserved" ;
VAL_ 1331 APA_DetailedVoice_Switch 0 "OFF" 1 "ON" ;
VAL_ 1331 APA_BackstageSearchSts 0 "Disable" 1 "Enable" ;
VAL_ 1331 ADS_IACCSysdeactiveReason 0 "无
0x1=纵向退出
0x2=IACC故障
0x3=横向紧急功能触发
0x4=ABS／ESP／TCS／VDC／AEB触发
0x5=驾驶员主动退出
0x6=安全停车退出
0x7=其他
0x8~0xF=reserved" ;
VAL_ 1331 ADS_IACC_LatTakeOverReason 0 "无
0x1=异常退出
0x2=安全停车
0x3=车道线丢失
0x4=压线
0x5=前方障碍物
0x6=截止车道
0x7=曲率过大
0x8=IACC故障
0x9=其他
0xA~F=Reserved" ;
VAL_ 1331 ACC_RLaneQuality 0 "" ;
VAL_ 1331 ACC_RedLightRemindEnable 0 "OFF" 1 "ON" ;
VAL_ 1331 ACC_DOSECountDown 1 "0s" 2 "1s" 3 "2s" 4 "3s" 5 "4s" 6 "5s" 7 "6s" 8 "7s" 9 "8s" 10 "9s" 11 "10s" 12 "11s" 13 "12s" 14 "13s" 15 "14s" 16 "15s" 17 "Reserved" ;
VAL_ 1331 ACC_Target9ZoneID 0 "no zoneid" 1 "zoneid1-11
0xC=hostlane_zone
0xD=leftlane_zone
0xE=rightlane_zone
0xF=LLLane_zone
0x10=RRLane_zone
0x11=Ramp_zone" 18 "others" 19 "reserved" ;
VAL_ 1331 ACC_Target9Type 0 "no display" 1 "sedan" 2 "motorcycle" 3 "pedestrian" 4 "Bicycle" 5 "Bus" 6 "VAN" 7 "truck" 8 "Cone Consideration" 9 "Warning Column" 10 "Water Horse" 11 "Anti-Collision Bucket" 12 "others" 13 "animal" 14 "Non-road vehicle" 15 "CarWarningTriangle" ;
VAL_ 1331 ACC_Target9RightLightStatus 0 "off" 1 "on" ;
VAL_ 1331 ACC_Target9LngRelSpeed 0 "-250~250
0x1F5~0x1FE=reserved
0x1FF=unknown" ;
VAL_ 1331 ACC_Target9LngRange 0 "-100~300" 4001 "reserved" 4095 "Invalid" ;
VAL_ 1331 ACC_Target9LeftLightStatus 0 "off" 1 "on" ;
VAL_ 1331 ACC_Target9LDC 0 "No LDC warning" 1 " LDC warning" ;
VAL_ 1331 ACC_Target9LatRelSpeed 0 "-64~63.875
0x400=unknown" ;
VAL_ 1331 ACC_Target9LatRange 0 "-50-50m" 1001 "reserved" 1023 "Invalid" ;
VAL_ 1331 ACC_Target9ID 0 "" ;
VAL_ 1331 ACC_Target9Direction 0 "Forward" 1 "OnComing" 2 "Left" 3 "Right" 4 "unknown" 5 "refer to headingangle" 6 "reserved" ;
VAL_ 1331 ACC_Target9Detection 0 "not dectected" 1 "IP display" 2 "Front Target" 3 "IACC target" 4 "AEB target" 5 "dangerous target（ELK、UDLC、RCW, etc）" 6 "other target" 7 "reserved" ;
VAL_ 1331 ACC_Target9BSDStatus 0 "No LCA warning" 1 "LCA warning level 1" 2 " LCA warning level 2" 3 "Reserved" ;
VAL_ 1331 ACC_Target9BrakeLightStatus 0 "off" 1 "on" ;
VAL_ 1331 ACC_Target8ZoneID 0 "no zoneid" 1 "zoneid1-11
0xC=hostlane_zone
0xD=leftlane_zone
0xE=rightlane_zone
0xF=LLLane_zone
0x10=RRLane_zone
0x11=Ramp_zone" 18 "others" 19 "reserved" ;
VAL_ 1331 ACC_Target8Type 0 "no display" 1 "sedan" 2 "motorcycle" 3 "pedestrian" 4 "Bicycle" 5 "Bus" 6 "VAN" 7 "truck" 8 "Cone Consideration" 9 "Warning Column" 10 "Water Horse" 11 "Anti-Collision Bucket" 12 "others" 13 "animal" 14 "Non-road vehicle" 15 "CarWarningTriangle" ;
VAL_ 1331 ACC_Target8RightLightStatus 0 "off" 1 "on" ;
VAL_ 1331 ACC_Target8LngRelSpeed 0 "-250~250
0x1F5~0x1FE=reserved
0x1FF=unknown" ;
VAL_ 1331 ACC_Target8LngRange 0 "-100~300" 4001 "reserved" 4095 "Invalid" ;
VAL_ 1331 ACC_Target8LeftLightStatus 0 "off" 1 "on" ;
VAL_ 1331 ACC_Target8LDC 0 "No LDC warning" 1 " LDC warning" ;
VAL_ 1331 ACC_Target8LatRelSpeed 0 "-64~63.875
0x400=unknown" ;
VAL_ 1331 ACC_Target8LatRange 0 "-50-50m" 1001 "reserved" 1023 "Invalid" ;
VAL_ 1331 ACC_Target8ID 0 "" ;
VAL_ 1331 ACC_Target8Direction 0 "Forward" 1 "OnComing" 2 "Left" 3 "Right" 4 "unknown" 5 "refer to headingangle" 6 "reserved" ;
VAL_ 1331 ACC_Target8Detection 0 "not dectected" 1 "IP display" 2 "Front Target" 3 "IACC target" 4 "AEB target" 5 "dangerous target（ELK、UDLC、RCW, etc）" 6 "other target" 7 "reserved" ;
VAL_ 1331 ACC_Target8BSDStatus 0 "No LCA warning" 1 "LCA warning level 1" 2 " LCA warning level 2" 3 "Reserved" ;
VAL_ 1331 ACC_Target8BrakeLightStatus 0 "off" 1 "on" ;
VAL_ 1331 ACC_Target7RightLightStatus 0 "off" 1 "on" ;
VAL_ 1331 ACC_Target7LngRelSpeed 0 "-250~250
0x1F5~0x1FE=reserved
0x1FF=unknown" ;
VAL_ 1331 ACC_Target7LeftLightStatus 0 "off" 1 "on" ;
VAL_ 1331 ACC_Target7LDC 0 "No LDC warning" 1 " LDC warning" ;
VAL_ 1331 ACC_Target7LatRelSpeed 0 "-64~63.875
0x400=unknown" ;
VAL_ 1331 ACC_Target7BSDStatus 0 "No LCA warning" 1 "LCA warning level 1" 2 " LCA warning level 2" 3 "Reserved" ;
VAL_ 1331 ACC_Target7BrakeLightStatus 0 "off" 1 "on" ;
VAL_ 1331 ACC_Target6RightLightStatus 0 "off" 1 "on" ;
VAL_ 1331 ACC_Target6LngRelSpeed 0 "-250~250
0x1F5~0x1FE=reserved
0x1FF=unknown" ;
VAL_ 1331 ACC_Target6LeftLightStatus 0 "off" 1 "on" ;
VAL_ 1331 ACC_Target6LDC 0 "No LDC warning" 1 " LDC warning" ;
VAL_ 1331 ACC_Target6LatRelSpeed 0 "-64~63.875
0x400=unknown" ;
VAL_ 1331 ACC_Target6BSDStatus 0 "No LCA warning" 1 "LCA warning level 1" 2 " LCA warning level 2" 3 "Reserved" ;
VAL_ 1331 ACC_Target6BrakeLightStatus 0 "off" 1 "on" ;
VAL_ 1331 ACC_Target5RightLightStatus 0 "off" 1 "on" ;
VAL_ 1331 ACC_Target5LngRelSpeed 0 "-250~250
0x1F5~0x1FE=reserved
0x1FF=unknown" ;
VAL_ 1331 ACC_Target5LeftLightStatus 0 "off" 1 "on" ;
VAL_ 1331 ACC_Target5LDC 0 "No LDC warning" 1 " LDC warning" ;
VAL_ 1331 ACC_Target5LatRelSpeed 0 "-64~63.875
0x400=unknown" ;
VAL_ 1331 ACC_Target5BSDStatus 0 "No LCA warning" 1 "LCA warning level 1" 2 " LCA warning level 2" 3 "Reserved" ;
VAL_ 1331 ACC_Target5BrakeLightStatus 0 "off" 1 "on" ;
VAL_ 1331 ACC_Target4RightLightStatus 0 "off" 1 "on" ;
VAL_ 1331 ACC_Target4LngRelSpeed 0 "-250~250
0x1F5~0x1FE=reserved
0x1FF=unknown" ;
VAL_ 1331 ACC_Target4LeftLightStatus 0 "off" 1 "on" ;
VAL_ 1331 ACC_Target4LDC 0 "No LDC warning" 1 " LDC warning" ;
VAL_ 1331 ACC_Target4LatRelSpeed 0 "-64~63.875
0x400=unknown" ;
VAL_ 1331 ACC_Target4BSDStatus 0 "No LCA warning" 1 "LCA warning level 1" 2 " LCA warning level 2" 3 "Reserved" ;
VAL_ 1331 ACC_Target4BrakeLightStatus 0 "off" 1 "on" ;
VAL_ 1331 ACC_Target3RightLightStatus 0 "off" 1 "on" ;
VAL_ 1331 ACC_Target3LngRelSpeed 0 "-250~250
0x1F5~0x1FE=reserved
0x1FF=unknown" ;
VAL_ 1331 ACC_Target3LeftLightStatus 0 "off" 1 "on" ;
VAL_ 1331 ACC_Target3LDC 0 "No LDC warning" 1 " LDC warning" ;
VAL_ 1331 ACC_Target3LatRelSpeed 0 "-64~63.875
0x400=unknown" ;
VAL_ 1331 ACC_Target3BSDStatus 0 "No LCA warning" 1 "LCA warning level 1" 2 " LCA warning level 2" 3 "Reserved" ;
VAL_ 1331 ACC_Target3BrakeLightStatus 0 "off" 1 "on" ;
VAL_ 1331 ACC_Target32ZoneID 0 "no zoneid" 1 "zoneid1-11
0xC=hostlane_zone
0xD=leftlane_zone
0xE=rightlane_zone
0xF=LLLane_zone
0x10=RRLane_zone
0x11=Ramp_zone" 18 "others" 19 "reserved" ;
VAL_ 1331 ACC_Target32Type 0 "no display" 1 "sedan" 2 "motorcycle" 3 "pedestrian" 4 "Bicycle" 5 "Bus" 6 "VAN" 7 "truck" 8 "Cone Consideration" 9 "Warning Column" 10 "Water Horse" 11 "Anti-Collision Bucket" 12 "others" 13 "animal" 14 "Non-road vehicle" 15 "CarWarningTriangle" ;
VAL_ 1331 ACC_Target32RightLightStatus 0 "off" 1 "on" ;
VAL_ 1331 ACC_Target32LngRelSpeed 0 "-250~250
0x1F5~0x1FE=reserved
0x1FF=unknown" ;
VAL_ 1331 ACC_Target32LngRange 0 "-100~300" 4001 "reserved" 4095 "Invalid" ;
VAL_ 1331 ACC_Target32LeftLightStatus 0 "off" 1 "on" ;
VAL_ 1331 ACC_Target32LDC 0 "No LDC warning" 1 " LDC warning" ;
VAL_ 1331 ACC_Target32LatRelSpeed 0 "-64~63.875
0x400=unknown" ;
VAL_ 1331 ACC_Target32LatRange 0 "-50-50m" 1001 "reserved" 1023 "Invalid" ;
VAL_ 1331 ACC_Target32ID 0 "" ;
VAL_ 1331 ACC_Target32Direction 0 "Forward" 1 "OnComing" 2 "Left" 3 "Right" 4 "unknown" 5 "refer to headingangle" 6 "reserved" ;
VAL_ 1331 ACC_Target32Detection 0 "not dectected" 1 "IP display" 2 "Front Target" 3 "IACC target" 4 "AEB target" 5 "dangerous target（ELK、UDLC、RCW, etc）" 6 "other target" 7 "reserved" ;
VAL_ 1331 ACC_Target32BSDStatus 0 "No LCA warning" 1 "LCA warning level 1" 2 " LCA warning level 2" 3 "Reserved" ;
VAL_ 1331 ACC_Target32BrakeLightStatus 0 "off" 1 "on" ;
VAL_ 1331 ACC_Target31ZoneID 0 "no zoneid" 1 "zoneid1-11
0xC=hostlane_zone
0xD=leftlane_zone
0xE=rightlane_zone
0xF=LLLane_zone
0x10=RRLane_zone
0x11=Ramp_zone" 18 "others" 19 "reserved" ;
VAL_ 1331 ACC_Target31Type 0 "no display" 1 "sedan" 2 "motorcycle" 3 "pedestrian" 4 "Bicycle" 5 "Bus" 6 "VAN" 7 "truck" 8 "Cone Consideration" 9 "Warning Column" 10 "Water Horse" 11 "Anti-Collision Bucket" 12 "others" 13 "animal" 14 "Non-road vehicle" 15 "CarWarningTriangle" ;
VAL_ 1331 ACC_Target31RightLightStatus 0 "off" 1 "on" ;
VAL_ 1331 ACC_Target31LngRelSpeed 0 "-250~250
0x1F5~0x1FE=reserved
0x1FF=unknown" ;
VAL_ 1423 mADC_NotSleep_BYTE7BIT6 0 "Inactive" 1 " IGN硬线信号为ON档/总线电源挡位信号非OFF" ;
VAL_ 1423 mADC_NotSleep_BYTE7BIT5 0 "Inactive" 1 "OTA功能未完成" ;
VAL_ 1423 mADC_NotSleep_BYTE7BIT4 0 "Inactive" 1 "开门预警功能未结束" ;
VAL_ 1423 mADC_NotSleep_BYTE7BIT3 0 "Inactive" 1 " ADASE_CAN不允许休眠" ;
VAL_ 1423 mADC_NotSleep_BYTE7BIT2 0 "Inactive" 1 " ADASC_CAN不允许休眠" ;
VAL_ 1423 mADC_NotSleep_BYTE7BIT1 0 "Inactive" 1 " ADASB_CAN不允许休眠" ;
VAL_ 1423 mADC_NotSleep_BYTE7BIT0 0 "Inactive" 1 " CAN网络管理报文不允许休眠" ;
VAL_ 1423 mADC_WakeUp_BYTE4BIT1 0 "Inactive" 1 "  IG唤醒（若不接IG硬线则无此位）" ;
VAL_ 1423 mADC_WakeUp_BYTE4BIT0 0 "Inactive" 1 "  CAN网络管理报文唤醒" ;
VAL_ 958 ATS_CurrentDrivingMode 0 " normal" 1 " snow（雪地）" 2 " mud（泥地）" 3 " sand（沙地）" 4 " rock（崎岖）" 5 " wade（涉水）" 6 "protect（" 7 "eco" 8 " sport" ;
VAL_ 1430 LCDAL_NotSleep_BYTE7BIT4 0 "Inactive" 1 "SEW功能开启且电源模式切换为OFF刚好5分钟但SEW报警报文正在发送" ;
VAL_ 1430 LCDAL_NotSleep_BYTE7BIT3 0 "Inactive" 1 "SEW功能开启且电源模式切换为OFF不足5分钟" ;
VAL_ 1430 LCDAL_NotSleep_BYTE7BIT2 0 "Inactive" 1 "诊断服务在线" ;
VAL_ 1430 LCDAL_NotSleep_BYTE7BIT1 0 "Inactive" 1 " IGN硬线信号为ON档/总线电源挡位信号非OFF" ;
VAL_ 1430 LCDAL_NotSleep_BYTE7BIT0 0 "Inactive" 1 " CAN网络上其他节点不允许休眠" ;
VAL_ 1430 LCDAL_WakeUp_BYTE4BIT1 0 "Inactive" 1 " IG唤醒（若不接IG硬线则无此位）" ;
VAL_ 1430 LCDAL_WakeUp_BYTE4BIT0 0 "Inactive" 1 " CAN网络管理报文唤醒" ;
VAL_ 1431 LCDAR_NotSleep_BYTE7BIT4 0 "Inactive" 1 "SEW功能开启且电源模式切换为OFF刚好5分钟但SEW报警报文正在发送" ;
VAL_ 1431 LCDAR_NotSleep_BYTE7BIT3 0 "Inactive" 1 "SEW功能开启且电源模式切换为OFF不足5分钟" ;
VAL_ 1431 LCDAR_NotSleep_BYTE7BIT2 0 "Inactive" 1 "诊断服务在线" ;
VAL_ 1431 LCDAR_NotSleep_BYTE7BIT1 0 "Inactive" 1 " IGN硬线信号为ON档/总线电源挡位信号非OFF" ;
VAL_ 1431 LCDAR_NotSleep_BYTE7BIT0 0 "Inactive" 1 " CAN网络上其他节点不允许休眠" ;
VAL_ 1431 LCDAR_WakeUp_BYTE4BIT1 0 "Inactive" 1 " IG唤醒（若不接IG硬线则无此位）" ;
VAL_ 1431 LCDAR_WakeUp_BYTE4BIT0 0 "Inactive" 1 " CAN网络管理报文唤醒" ;
VAL_ 1432 FRR_NotSleep_BYTE7BIT1 0 "Inactive" 1 " IGN硬线信号为ON档/总线电源挡位信号非OFF" ;
VAL_ 1432 FRR_NotSleep_BYTE7BIT0 0 "Inactive" 1 " CAN网络上其他节点不允许休眠" ;
VAL_ 1432 FRR_WakeUp_BYTE4BIT1 0 "Inactive" 1 " IG唤醒（若不接IG硬线则无此位）" ;
VAL_ 1432 FRR_WakeUp_BYTE4BIT0 0 "Inactive" 1 " CAN网络管理报文唤醒" ;
VAL_ 1442 FLR_NotSleep_BYTE7BIT1 0 "Inactive" 1 " IGN硬线信号为ON档/总线电源挡位信号非OFF" ;
VAL_ 1442 FLR_NotSleep_BYTE7BIT0 0 "Inactive" 1 " CAN网络上其他节点不允许休眠" ;
VAL_ 1442 FLR_WakeUp_BYTE4BIT1 0 "Inactive" 1 " IG唤醒（若不接IG硬线则无此位）" ;
VAL_ 1442 FLR_WakeUp_BYTE4BIT0 0 "Inactive" 1 " CAN网络管理报文唤醒" ;
VAL_ 953 BDC_TurnLightSw 0 "Initial" 1 "Left 1" 2 "Right 1" 3 "Left 2" 4 "Right 2" 5 "Invalid" ;
VAL_ 691 THU_ShippingMod 0 "Inactive" 1 "开启" 2 "关闭" ;
VAL_ 989 HU_frontline8_icon 0 "直行" 1 "左转" 2 "直行+左转" 3 "右转" 4 "直行+右转" 5 "左掉头" 6 "左转+右转" 7 "直行+左转+右转" 8 "右掉头" 9 "直行+左掉头" 10 "直行+右掉头" 11 "左转+左掉头" 12 "右转+右掉头" 13 "预留" 14 "预留" 15 "预留" 16 "直行+左转+左掉头" 17 "右转+左掉头" 18 "左转+右转+左掉头" 19 "直行+右转+左掉头" 20 "左转+右掉头" 21 "公交车道" 22 "空车道" 23 "可变车道" 24 "专用车道" 25 "潮汐车道" 26 "预留" 255 "不显示车道" ;
VAL_ 989 HU_frontline7_icon 0 "直行" 1 "左转" 2 "直行+左转" 3 "右转" 4 "直行+右转" 5 "左掉头" 6 "左转+右转" 7 "直行+左转+右转" 8 "右掉头" 9 "直行+左掉头" 10 "直行+右掉头" 11 "左转+左掉头" 12 "右转+右掉头" 13 "预留" 14 "预留" 15 "预留" 16 "直行+左转+左掉头" 17 "右转+左掉头" 18 "左转+右转+左掉头" 19 "直行+右转+左掉头" 20 "左转+右掉头" 21 "公交车道" 22 "空车道" 23 "可变车道" 24 "专用车道" 25 "潮汐车道" 26 "预留" 255 "不显示车道" ;
VAL_ 989 HU_frontline6_icon 0 "直行" 1 "左转" 2 "直行+左转" 3 "右转" 4 "直行+右转" 5 "左掉头" 6 "左转+右转" 7 "直行+左转+右转" 8 "右掉头" 9 "直行+左掉头" 10 "直行+右掉头" 11 "左转+左掉头" 12 "右转+右掉头" 13 "预留" 14 "预留" 15 "预留" 16 "直行+左转+左掉头" 17 "右转+左掉头" 18 "左转+右转+左掉头" 19 "直行+右转+左掉头" 20 "左转+右掉头" 21 "公交车道" 22 "空车道" 23 "可变车道" 24 "专用车道" 25 "潮汐车道" 26 "预留" 255 "不显示车道" ;
VAL_ 989 HU_frontline5_icon 0 "直行" 1 "左转" 2 "直行+左转" 3 "右转" 4 "直行+右转" 5 "左掉头" 6 "左转+右转" 7 "直行+左转+右转" 8 "右掉头" 9 "直行+左掉头" 10 "直行+右掉头" 11 "左转+左掉头" 12 "右转+右掉头" 13 "预留" 14 "预留" 15 "预留" 16 "直行+左转+左掉头" 17 "右转+左掉头" 18 "左转+右转+左掉头" 19 "直行+右转+左掉头" 20 "左转+右掉头" 21 "公交车道" 22 "空车道" 23 "可变车道" 24 "专用车道" 25 "潮汐车道" 26 "预留" 255 "不显示车道" ;
VAL_ 989 HU_frontline4_icon 0 "直行" 1 "左转" 2 "直行+左转" 3 "右转" 4 "直行+右转" 5 "左掉头" 6 "左转+右转" 7 "直行+左转+右转" 8 "右掉头" 9 "直行+左掉头" 10 "直行+右掉头" 11 "左转+左掉头" 12 "右转+右掉头" 13 "预留" 14 "预留" 15 "预留" 16 "直行+左转+左掉头" 17 "右转+左掉头" 18 "左转+右转+左掉头" 19 "直行+右转+左掉头" 20 "左转+右掉头" 21 "公交车道" 22 "空车道" 23 "可变车道" 24 "专用车道" 25 "潮汐车道" 26 "预留" 255 "不显示车道" ;
VAL_ 989 HU_frontline3_icon 0 "直行" 1 "左转" 2 "直行+左转" 3 "右转" 4 "直行+右转" 5 "左掉头" 6 "左转+右转" 7 "直行+左转+右转" 8 "右掉头" 9 "直行+左掉头" 10 "直行+右掉头" 11 "左转+左掉头" 12 "右转+右掉头" 13 "预留" 14 "预留" 15 "预留" 16 "直行+左转+左掉头" 17 "右转+左掉头" 18 "左转+右转+左掉头" 19 "直行+右转+左掉头" 20 "左转+右掉头" 21 "公交车道" 22 "空车道" 23 "可变车道" 24 "专用车道" 25 "潮汐车道" 26 "预留" 255 "不显示车道" ;
VAL_ 989 HU_frontline2_icon 0 "直行" 1 "左转" 2 "直行+左转" 3 "右转" 4 "直行+右转" 5 "左掉头" 6 "左转+右转" 7 "直行+左转+右转" 8 "右掉头" 9 "直行+左掉头" 10 "直行+右掉头" 11 "左转+左掉头" 12 "右转+右掉头" 13 "预留" 14 "预留" 15 "预留" 16 "直行+左转+左掉头" 17 "右转+左掉头" 18 "左转+右转+左掉头" 19 "直行+右转+左掉头" 20 "左转+右掉头" 21 "公交车道" 22 "空车道" 23 "可变车道" 24 "专用车道" 25 "潮汐车道" 26 "预留" 255 "不显示车道" ;
VAL_ 989 HU_frontline1_icon 0 "直行" 1 "左转" 2 "直行+左转" 3 "右转" 4 "直行+右转" 5 "左掉头" 6 "左转+右转" 7 "直行+左转+右转" 8 "右掉头" 9 "直行+左掉头" 10 "直行+右掉头" 11 "左转+左掉头" 12 "右转+右掉头" 13 "预留" 14 "预留" 15 "预留" 16 "直行+左转+左掉头" 17 "右转+左掉头" 18 "左转+右转+左掉头" 19 "直行+右转+左掉头" 20 "左转+右掉头" 21 "公交车道" 22 "空车道" 23 "可变车道" 24 "专用车道" 25 "潮汐车道" 26 "预留" 255 "不显示车道" ;
VAL_ 989 HU_backline8_icon 0 "直行" 1 "左转" 2 "直行+左转" 3 "右转" 4 "直行+右转" 5 "左掉头" 6 "左转+右转" 7 "直行+左转+右转" 8 "右掉头" 9 "直行+左掉头" 10 "直行+右掉头" 11 "左转+左掉头" 12 "右转+右掉头" 13 "预留" 14 "预留" 15 "预留" 16 "直行+左转+左掉头" 17 "右转+左掉头" 18 "左转+右转+左掉头" 19 "直行+右转+左掉头" 20 "左转+右掉头" 21 "公交车道" 22 "空车道" 23 "可变车道" 24 "专用车道" 25 "潮汐车道" 26 "预留" ;
VAL_ 989 HU_backline7_icon 0 "直行" 1 "左转" 2 "直行+左转" 3 "右转" 4 "直行+右转" 5 "左掉头" 6 "左转+右转" 7 "直行+左转+右转" 8 "右掉头" 9 "直行+左掉头" 10 "直行+右掉头" 11 "左转+左掉头" 12 "右转+右掉头" 13 "预留" 14 "预留" 15 "预留" 16 "直行+左转+左掉头" 17 "右转+左掉头" 18 "左转+右转+左掉头" 19 "直行+右转+左掉头" 20 "左转+右掉头" 21 "公交车道" 22 "空车道" 23 "可变车道" 24 "专用车道" 25 "潮汐车道" 26 "预留" ;
VAL_ 989 HU_backline6_icon 0 "直行" 1 "左转" 2 "直行+左转" 3 "右转" 4 "直行+右转" 5 "左掉头" 6 "左转+右转" 7 "直行+左转+右转" 8 "右掉头" 9 "直行+左掉头" 10 "直行+右掉头" 11 "左转+左掉头" 12 "右转+右掉头" 13 "预留" 14 "预留" 15 "预留" 16 "直行+左转+左掉头" 17 "右转+左掉头" 18 "左转+右转+左掉头" 19 "直行+右转+左掉头" 20 "左转+右掉头" 21 "公交车道" 22 "空车道" 23 "可变车道" 24 "专用车道" 25 "潮汐车道" 26 "预留" ;
VAL_ 989 HU_backline5_icon 0 "直行" 1 "左转" 2 "直行+左转" 3 "右转" 4 "直行+右转" 5 "左掉头" 6 "左转+右转" 7 "直行+左转+右转" 8 "右掉头" 9 "直行+左掉头" 10 "直行+右掉头" 11 "左转+左掉头" 12 "右转+右掉头" 13 "预留" 14 "预留" 15 "预留" 16 "直行+左转+左掉头" 17 "右转+左掉头" 18 "左转+右转+左掉头" 19 "直行+右转+左掉头" 20 "左转+右掉头" 21 "公交车道" 22 "空车道" 23 "可变车道" 24 "专用车道" 25 "潮汐车道" 26 "预留" ;
VAL_ 989 HU_backline4_icon 0 "直行" 1 "左转" 2 "直行+左转" 3 "右转" 4 "直行+右转" 5 "左掉头" 6 "左转+右转" 7 "直行+左转+右转" 8 "右掉头" 9 "直行+左掉头" 10 "直行+右掉头" 11 "左转+左掉头" 12 "右转+右掉头" 13 "预留" 14 "预留" 15 "预留" 16 "直行+左转+左掉头" 17 "右转+左掉头" 18 "左转+右转+左掉头" 19 "直行+右转+左掉头" 20 "左转+右掉头" 21 "公交车道" 22 "空车道" 23 "可变车道" 24 "专用车道" 25 "潮汐车道" 26 "预留" ;
VAL_ 989 HU_backline3_icon 0 "直行" 1 "左转" 2 "直行+左转" 3 "右转" 4 "直行+右转" 5 "左掉头" 6 "左转+右转" 7 "直行+左转+右转" 8 "右掉头" 9 "直行+左掉头" 10 "直行+右掉头" 11 "左转+左掉头" 12 "右转+右掉头" 13 "预留" 14 "预留" 15 "预留" 16 "直行+左转+左掉头" 17 "右转+左掉头" 18 "左转+右转+左掉头" 19 "直行+右转+左掉头" 20 "左转+右掉头" 21 "公交车道" 22 "空车道" 23 "可变车道" 24 "专用车道" 25 "潮汐车道" 26 "预留" ;
VAL_ 989 HU_backline2_icon 0 "直行" 1 "左转" 2 "直行+左转" 3 "右转" 4 "直行+右转" 5 "左掉头" 6 "左转+右转" 7 "直行+左转+右转" 8 "右掉头" 9 "直行+左掉头" 10 "直行+右掉头" 11 "左转+左掉头" 12 "右转+右掉头" 13 "预留" 14 "预留" 15 "预留" 16 "直行+左转+左掉头" 17 "右转+左掉头" 18 "左转+右转+左掉头" 19 "直行+右转+左掉头" 20 "左转+右掉头" 21 "公交车道" 22 "空车道" 23 "可变车道" 24 "专用车道" 25 "潮汐车道" 26 "预留" ;
VAL_ 989 HU_backline1_icon 0 "直行" 1 "左转" 2 "直行+左转" 3 "右转" 4 "直行+右转" 5 "左掉头" 6 "左转+右转" 7 "直行+左转+右转" 8 "右掉头" 9 "直行+左掉头" 10 "直行+右掉头" 11 "左转+左掉头" 12 "右转+右掉头" 13 "预留" 14 "预留" 15 "预留" 16 "直行+左转+左掉头" 17 "右转+左掉头" 18 "左转+右转+左掉头" 19 "直行+右转+左掉头" 20 "左转+右掉头" 21 "公交车道" 22 "空车道" 23 "可变车道" 24 "专用车道" 25 "潮汐车道" 26 "预留" ;
VAL_ 989 HU_LineShow 0 "隐藏" 1 "显示" ;
VAL_ 1018 ESP_EpbReqAvl 0 "Not available
0x1=available" ;
VAL_ 913 PCU_TowingMode 0 "not Active" 1 "Active" ;
VAL_ 573 HU_8stRoadTransferTime 0 "0-65534s" 65535 "out of  range" ;
VAL_ 573 HU_8stRoadLength 0 "0-65534m" 65535 "out of  range" ;
VAL_ 573 HU_8stRoadTrafficStatus 0 "Unknown" 1 "畅通" 2 "缓行" 3 "拥堵" 4 "严重拥堵" 5 "极度畅通" 6 "reserved" ;
VAL_ 573 HU_7stRoadTransferTime 0 "0-65534s" 65535 "out of  range" ;
VAL_ 573 HU_7stRoadLength 0 "0-65534m" 65535 "out of  range" ;
VAL_ 573 HU_7stRoadTrafficStatus 0 "Unknown" 1 "畅通" 2 "缓行" 3 "拥堵" 4 "严重拥堵" 5 "极度畅通" 6 "reserved" ;
VAL_ 573 HU_6stRoadTransferTime 0 "0-65534s" 65535 "out of  range" ;
VAL_ 573 HU_6stRoadLength 0 "0-65534m" 65535 "out of  range" ;
VAL_ 573 HU_6stRoadTrafficStatus 0 "Unknown" 1 "畅通" 2 "缓行" 3 "拥堵" 4 "严重拥堵" 5 "极度畅通" 6 "reserved" ;
VAL_ 573 HU_5stRoadTransferTime 0 "0-65534s" 65535 "out of  range" ;
VAL_ 573 HU_5stRoadLength 0 "0-65534m" 65535 "out of  range" ;
VAL_ 573 HU_5stRoadTrafficStatus 0 "Unknown" 1 "畅通" 2 "缓行" 3 "拥堵" 4 "严重拥堵" 5 "极度畅通" 6 "reserved" ;
VAL_ 573 HU_4stRoadTransferTime 0 "0-65534s" 65535 "out of  range" ;
VAL_ 573 HU_4stRoadLength 0 "0-65534m" 65535 "out of  range" ;
VAL_ 573 HU_4stRoadTrafficStatus 0 "Unknown" 1 "畅通" 2 "缓行" 3 "拥堵" 4 "严重拥堵" 5 "极度畅通" 6 "reserved" ;
VAL_ 573 HU_3stRoadTransferTime 0 "0-65534s" 65535 "out of  range" ;
VAL_ 573 HU_3stRoadLength 0 "0-65534m" 65535 "out of  range" ;
VAL_ 573 HU_3stRoadTrafficStatus 0 "Unknown" 1 "畅通" 2 "缓行" 3 "拥堵" 4 "严重拥堵" 5 "极度畅通" 6 "reserved" ;
VAL_ 573 HU_2stRoadTransferTime 0 "0-65534s" 65535 "out of  range" ;
VAL_ 573 HU_2stRoadLength 0 "0-65534m" 65535 "out of  range" ;
VAL_ 573 HU_2stRoadTrafficStatus 0 "Unknown" 1 "畅通" 2 "缓行" 3 "拥堵" 4 "严重拥堵" 5 "极度畅通" 6 "reserved" ;
VAL_ 573 HU_1stRoadTransferTime 0 "0-65534s" 65535 "out of  range" ;
VAL_ 573 HU_1stRoadLength 0 "0-65534m" 65535 "out of  range" ;
VAL_ 573 HU_1stRoadTrafficStatus 0 "Unknown" 1 "畅通" 2 "缓行" 3 "拥堵" 4 "严重拥堵" 5 "极度畅通" 6 "reserved" ;
VAL_ 392 TCU_ShiftinProgress 0 "Noshift" 1 "Shift" ;
VAL_ 632 ESP_YawRateValid 0 "Valid" 1 "Invalid" ;
VAL_ 424 TCU_STLKfailure 0 "normal" 1 "error" ;
VAL_ 424 TCU_GearShiftPosition 0 "Parking" 1 "Reverse" 2 "Neutral" 3 "D" 4 "D3" 5 "D2" 6 "L" 7 "M_or_S" 8 "Reserved" 9 "Reserved" 10 "Reserved" 11 "Reserved" 12 "Reserved" 13 "Reserved" 14 "Unreliable" 15 "Invalid" ;
VAL_ 424 TCU_ShiftPostionValid 0 "Valid" 1 "Invalid" ;
VAL_ 588 TCU_APAShiftGearRequestEnable 0 "no request received" 1 "Control enabled" 2 "Control disable" 3 "invalid" ;
VAL_ 901 HU_CDCUnitSystSetStatus 0 "no req
0x1=kph
0x2=mph" ;
VAL_ 890 VMC_EcasModeFB 0 "inactive" 1 "Normal" 2 "sport" 3 "Off road " 4 "Auto " 5 "Access" 6 "Loading mode" 7 "Level" 8 "Trailer mode" 9 "maintenance mode" 10 "预留" ;
VAL_ 890 VMC_CtrlLevelRRValid 0 "Valid" 1 "Invalid" ;
VAL_ 890 VMC_CtrlLevelRLyValid 0 "Valid" 1 "Invalid" ;
VAL_ 890 VMC_CtrlLevelFRValid 0 "Valid" 1 "Invalid" ;
VAL_ 890 VMC_CtrlLevelFLValid 0 "Valid" 1 "Invalid" ;
VAL_ 890 VMC_EcasModeRELSts 0 "Idle" 1 "up" 2 "down" 3 "Switch fail" 4 "ready to Switch " ;
VAL_ 890 VMC_EcasModeFRTSts 0 "Idle" 1 "up" 2 "down" 3 "Switch fail" 4 "ready to Switch " ;
VAL_ 890 VMC_EcasModeCHASts 0 "no Switch request" 1 "Switching" 2 "Switch fail" 3 "reading to Switch " ;
VAL_ 890 VMC_EcasModeVal 0 "Disable" 1 "Enable" ;
VAL_ 890 VMC_EcdcMode 0 "inactive" 1 "Comfort" 2 "Normal" 3 "Sport" 4 "Auto" ;
